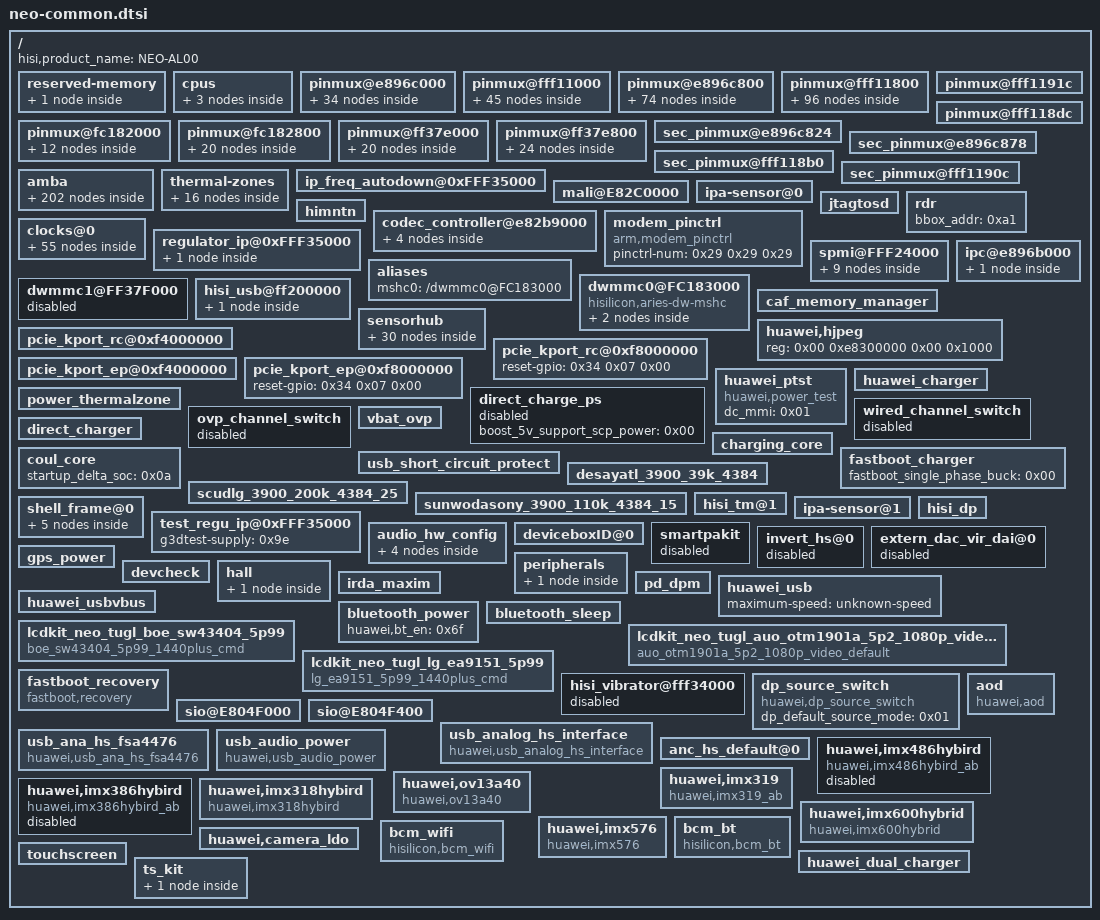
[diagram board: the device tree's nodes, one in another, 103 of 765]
/include/ "../kirin970-common.dtsi"

/ {
	hisi,product_name = "NEO-AL00";

	reserved-memory {
		bbox-mem {
			phandle = <0xa1>;
		};
	};

	cpus {
		cpu-map {
			cluster0 {
				phandle = <0x98>;
			};

			cluster1 {
				phandle = <0x99>;
			};
		};
	};

	pinmux@e896c000 {
		phandle = <0x52>;

		gpio006_pmx_idle {
			pinctrl-single,pins = <0x10 0x00>;
		};

		gpio007_pmx_idle {
			pinctrl-single,pins = <0x14 0x00>;
		};

		gpio016_pmx_func {
			pinctrl-single,pins = <0x720 0x02>;
		};

		gpio016_pmx_idle {
			pinctrl-single,pins = <0x720 0x02>;
		};

		gpio024_pmx_func {
			pinctrl-single,pins = <0x34 0x01>;
		};

		gpio024_pmx_idle {
			pinctrl-single,pins = <0x34 0x01>;
		};

		gpio025_pmx_func {
			pinctrl-single,pins = <0x38 0x01>;
		};

		gpio025_pmx_idle {
			pinctrl-single,pins = <0x38 0x01>;
		};

		gpio037_pmx_func {
			pinctrl-single,pins = <0x5c 0x01>;
		};

		gpio037_pmx_idle {
			pinctrl-single,pins = <0x5c 0x01>;
		};

		gpio038_pmx_func {
			pinctrl-single,pins = <0x60 0x01>;
		};

		gpio038_pmx_idle {
			pinctrl-single,pins = <0x60 0x01>;
		};

		gpio039_pmx_func {
			pinctrl-single,pins = <0x64 0x02>;
		};

		gpio039_pmx_idle {
			pinctrl-single,pins = <0x64 0x02>;
		};

		gpio040_pmx_func {
			pinctrl-single,pins = <0x68 0x02>;
		};

		gpio040_pmx_idle {
			pinctrl-single,pins = <0x68 0x02>;
		};

		gpio041_pmx_func {
			pinctrl-single,pins = <0x6c 0x02>;
		};

		gpio041_pmx_idle {
			pinctrl-single,pins = <0x6c 0x02>;
		};

		gpio042_pmx_func {
			pinctrl-single,pins = <0x70 0x02>;
		};

		gpio042_pmx_idle {
			pinctrl-single,pins = <0x70 0x02>;
		};

		gpio043_pmx_func {
			pinctrl-single,pins = <0x74 0x01>;
		};

		gpio043_pmx_idle {
			pinctrl-single,pins = <0x74 0x01>;
		};

		gpio044_pmx_func {
			pinctrl-single,pins = <0x78 0x01>;
		};

		gpio044_pmx_idle {
			pinctrl-single,pins = <0x78 0x01>;
		};

		gpio050_pmx_func {
			pinctrl-single,pins = <0x8c 0x00>;
		};

		gpio050_pmx_idle {
			pinctrl-single,pins = <0x8c 0x00>;
		};

		gpio055_pmx_func {
			pinctrl-single,pins = <0xa0 0x00>;
		};

		gpio055_pmx_idle {
			pinctrl-single,pins = <0xa0 0x00>;
		};

		gpio059_pmx_func {
			pinctrl-single,pins = <0xb0 0x00>;
		};

		gpio059_pmx_idle {
			pinctrl-single,pins = <0xb0 0x00>;
		};

		gpio060_pmx_func {
			pinctrl-single,pins = <0xb4 0x00>;
		};

		gpio060_pmx_idle {
			pinctrl-single,pins = <0xb4 0x00>;
		};

		gpio061_pmx_func {
			pinctrl-single,pins = <0xb8 0x00>;
		};

		gpio061_pmx_idle {
			pinctrl-single,pins = <0xb8 0x00>;
		};
	};

	pinmux@fff11000 {
		phandle = <0x66>;

		gpio144_pmx_func {
			pinctrl-single,pins = <0x72c 0x00>;
			phandle = <0x45>;
		};

		gpio144_pmx_idle {
			pinctrl-single,pins = <0x72c 0x00>;
			phandle = <0x4b>;
		};

		gpio145_pmx_func {
			pinctrl-single,pins = <0x730 0x00>;
			phandle = <0x46>;
		};

		gpio145_pmx_idle {
			pinctrl-single,pins = <0x730 0x00>;
			phandle = <0x4c>;
		};

		gpio146_pmx_func {
			pinctrl-single,pins = <0x734 0x00>;
			phandle = <0x47>;
		};

		gpio146_pmx_idle {
			pinctrl-single,pins = <0x734 0x00>;
			phandle = <0x4d>;
		};

		gpio182_pmx_func {
		};

		gpio182_pmx_idle {
		};

		gpio183_pmx_func {
			pinctrl-single,pins = <0x14 0x02>;
		};

		gpio183_pmx_idle {
			pinctrl-single,pins = <0x14 0x02>;
		};

		gpio184_pmx_func {
			pinctrl-single,pins = <0x18 0x00>;
		};

		gpio185_pmx_func {
			pinctrl-single,pins = <0x1c 0x00>;
		};

		gpio185_pmx_idle {
			pinctrl-single,pins = <0x1c 0x00>;
		};

		gpio188_pmx_idle {
			pinctrl-single,pins = <0x28 0x00>;
		};

		gpio189_pmx_idle {
			pinctrl-single,pins = <0x2c 0x00>;
		};

		gpio190_pmx_func {
			pinctrl-single,pins = <0x30 0x03>;
		};

		gpio190_pmx_idle {
			pinctrl-single,pins = <0x30 0x03>;
		};

		gpio191_pmx_func {
			pinctrl-single,pins = <0x34 0x03>;
		};

		gpio191_pmx_idle {
			pinctrl-single,pins = <0x34 0x03>;
		};

		gpio194_pmx_func {
			pinctrl-single,pins = <0x40 0x00>;
		};

		gpio194_pmx_idle {
			pinctrl-single,pins = <0x40 0x00>;
		};

		gpio195_pmx_func {
			pinctrl-single,pins = <0x44 0x02>;
		};

		gpio195_pmx_idle {
			pinctrl-single,pins = <0x44 0x02>;
		};

		gpio198_pmx_idle {
			pinctrl-single,pins = <0x50 0x00>;
		};

		gpio199_pmx_idle {
			pinctrl-single,pins = <0x54 0x00>;
		};

		gpio200_pmx_func {
			pinctrl-single,pins = <0x58 0x00>;
		};

		gpio200_pmx_idle {
			pinctrl-single,pins = <0x58 0x00>;
		};

		gpio206_pmx_func {
			pinctrl-single,pins = <0x70 0x00>;
		};

		gpio206_pmx_idle {
			pinctrl-single,pins = <0x70 0x00>;
		};

		gpio208_pmx_func {
			pinctrl-single,pins = <0x78 0x02>;
		};

		gpio208_pmx_idle {
			pinctrl-single,pins = <0x78 0x02>;
		};

		gpio216_pmx_func {
			pinctrl-single,pins = <0x71c 0x01>;
		};

		gpio216_pmx_idle {
			pinctrl-single,pins = <0x71c 0x01>;
		};

		gpio217_pmx_func {
			pinctrl-single,pins = <0x720 0x00>;
		};

		gpio217_pmx_idle {
			pinctrl-single,pins = <0x720 0x00>;
		};

		gpio218_pmx_func {
			pinctrl-single,pins = <0x724 0x02>;
		};

		gpio218_pmx_idle {
			pinctrl-single,pins = <0x724 0x02>;
		};

		gpio220_pmx_func {
			pinctrl-single,pins = <0x7c 0x02>;
		};

		gpio220_pmx_idle {
			pinctrl-single,pins = <0x7c 0x02>;
		};

		gpio221_pmx_func {
			pinctrl-single,pins = <0x80 0x02>;
		};

		gpio221_pmx_idle {
			pinctrl-single,pins = <0x80 0x02>;
		};

		gpio222_pmx_func {
			pinctrl-single,pins = <0x84 0x01>;
		};

		gpio222_pmx_idle {
			pinctrl-single,pins = <0x84 0x01>;
		};

		gpio223_pmx_func {
			pinctrl-single,pins = <0x88 0x01>;
		};

		gpio223_pmx_idle {
			pinctrl-single,pins = <0x88 0x01>;
		};
	};

	pinmux@e896c800 {
		gpio003_cfg_func {
			pinctrl-single,bias-pulldown = <0x00 0x02 0x00 0x02>;
		};

		gpio003_cfg_idle {
			pinctrl-single,bias-pulldown = <0x00 0x02 0x00 0x02>;
		};

		gpio004_cfg_func {
			pinctrl-single,bias-pulldown = <0x00 0x02 0x00 0x02>;
			pinctrl-single,bias-pullup = <0x00 0x01 0x00 0x01>;
		};

		gpio004_cfg_idle {
			pinctrl-single,bias-pulldown = <0x00 0x02 0x00 0x02>;
			pinctrl-single,bias-pullup = <0x00 0x01 0x00 0x01>;
		};

		gpio005_cfg_func {
			pinctrl-single,drive-strength = <0x20 0x70>;
		};

		gpio005_cfg_idle {
			pinctrl-single,drive-strength = <0x20 0x70>;
		};

		gpio006_cfg_func {
			pinctrl-single,drive-strength = <0x20 0x70>;
		};

		gpio007_cfg_func {
			pinctrl-single,drive-strength = <0x20 0x70>;
		};

		gpio008_cfg_func {
			pinctrl-single,bias-pulldown = <0x00 0x02 0x00 0x02>;
			pinctrl-single,bias-pullup = <0x00 0x01 0x00 0x01>;
		};

		gpio008_cfg_idle {
			pinctrl-single,bias-pulldown = <0x00 0x02 0x00 0x02>;
			pinctrl-single,bias-pullup = <0x00 0x01 0x00 0x01>;
		};

		gpio009_cfg_func {
			pinctrl-single,bias-pullup = <0x00 0x01 0x00 0x01>;
		};

		gpio009_cfg_idle {
			pinctrl-single,bias-pulldown = <0x00 0x02 0x00 0x02>;
			pinctrl-single,bias-pullup = <0x00 0x01 0x00 0x01>;
		};

		gpio010_cfg_func {
			pinctrl-single,bias-pulldown = <0x00 0x02 0x00 0x02>;
			pinctrl-single,bias-pullup = <0x00 0x01 0x00 0x01>;
		};

		gpio010_cfg_idle {
			pinctrl-single,bias-pulldown = <0x00 0x02 0x00 0x02>;
			pinctrl-single,bias-pullup = <0x00 0x01 0x00 0x01>;
		};

		gpio011_cfg_func {
			pinctrl-single,bias-pulldown = <0x00 0x02 0x00 0x02>;
			pinctrl-single,bias-pullup = <0x00 0x01 0x00 0x01>;
		};

		gpio011_cfg_idle {
			pinctrl-single,bias-pulldown = <0x00 0x02 0x00 0x02>;
			pinctrl-single,bias-pullup = <0x00 0x01 0x00 0x01>;
		};

		gpio012_cfg_func {
			pinctrl-single,bias-pulldown = <0x00 0x02 0x00 0x02>;
		};

		gpio012_cfg_idle {
			pinctrl-single,bias-pulldown = <0x00 0x02 0x00 0x02>;
		};

		gpio014_cfg_func {
			pinctrl-single,bias-pulldown = <0x00 0x02 0x00 0x02>;
		};

		gpio014_cfg_idle {
			pinctrl-single,bias-pulldown = <0x00 0x02 0x00 0x02>;
		};

		gpio015_cfg_func {
			pinctrl-single,bias-pulldown = <0x00 0x02 0x00 0x02>;
		};

		gpio015_cfg_idle {
			pinctrl-single,bias-pulldown = <0x00 0x02 0x00 0x02>;
		};

		gpio026_cfg_func {
			pinctrl-single,drive-strength = <0x20 0x70>;
		};

		gpio026_cfg_idle {
			pinctrl-single,drive-strength = <0x20 0x70>;
		};

		gpio027_cfg_func {
			pinctrl-single,drive-strength = <0x20 0x70>;
		};

		gpio027_cfg_idle {
			pinctrl-single,drive-strength = <0x20 0x70>;
		};

		gpio030_cfg_func {
			pinctrl-single,bias-pulldown = <0x00 0x02 0x00 0x02>;
		};

		gpio030_cfg_idle {
			pinctrl-single,bias-pulldown = <0x00 0x02 0x00 0x02>;
		};

		gpio034_cfg_func {
			pinctrl-single,bias-pulldown = <0x00 0x02 0x00 0x02>;
		};

		gpio034_cfg_idle {
			pinctrl-single,bias-pulldown = <0x00 0x02 0x00 0x02>;
		};

		gpio035_cfg_func {
			pinctrl-single,bias-pulldown = <0x00 0x02 0x00 0x02>;
			pinctrl-single,bias-pullup = <0x00 0x01 0x00 0x01>;
		};

		gpio035_cfg_idle {
			pinctrl-single,bias-pulldown = <0x00 0x02 0x00 0x02>;
			pinctrl-single,bias-pullup = <0x01 0x01 0x00 0x01>;
		};

		gpio036_cfg_func {
			pinctrl-single,bias-pulldown = <0x00 0x02 0x00 0x02>;
			pinctrl-single,bias-pullup = <0x00 0x01 0x00 0x01>;
		};

		gpio036_cfg_idle {
			pinctrl-single,bias-pulldown = <0x00 0x02 0x00 0x02>;
			pinctrl-single,bias-pullup = <0x00 0x01 0x00 0x01>;
			pinctrl-single,drive-strength = <0x10 0x70>;
		};

		gpio037_cfg_func {
			pinctrl-single,bias-pulldown = <0x00 0x02 0x00 0x02>;
			pinctrl-single,bias-pullup = <0x01 0x01 0x00 0x01>;
			pinctrl-single,drive-strength = <0x10 0x70>;
		};

		gpio037_cfg_idle {
			pinctrl-single,bias-pulldown = <0x00 0x02 0x00 0x02>;
			pinctrl-single,bias-pullup = <0x01 0x01 0x00 0x01>;
			pinctrl-single,drive-strength = <0x10 0x70>;
		};

		gpio038_cfg_func {
			pinctrl-single,bias-pulldown = <0x00 0x02 0x00 0x02>;
			pinctrl-single,drive-strength = <0x10 0x70>;
		};

		gpio038_cfg_idle {
			pinctrl-single,bias-pulldown = <0x00 0x02 0x00 0x02>;
			pinctrl-single,drive-strength = <0x10 0x70>;
		};

		gpio039_cfg_func {
			pinctrl-single,bias-pulldown = <0x02 0x02 0x00 0x02>;
		};

		gpio039_cfg_idle {
			pinctrl-single,bias-pulldown = <0x02 0x02 0x00 0x02>;
		};

		gpio040_cfg_func {
			pinctrl-single,bias-pulldown = <0x02 0x02 0x00 0x02>;
		};

		gpio040_cfg_idle {
			pinctrl-single,bias-pulldown = <0x02 0x02 0x00 0x02>;
		};

		gpio041_cfg_func {
			pinctrl-single,bias-pulldown = <0x00 0x02 0x00 0x02>;
			pinctrl-single,bias-pullup = <0x01 0x01 0x00 0x01>;
		};

		gpio041_cfg_idle {
			pinctrl-single,bias-pulldown = <0x00 0x02 0x00 0x02>;
			pinctrl-single,bias-pullup = <0x01 0x01 0x00 0x01>;
		};

		gpio042_cfg_func {
			pinctrl-single,bias-pulldown = <0x00 0x02 0x00 0x02>;
			pinctrl-single,bias-pullup = <0x01 0x01 0x00 0x01>;
		};

		gpio042_cfg_idle {
			pinctrl-single,bias-pulldown = <0x00 0x02 0x00 0x02>;
			pinctrl-single,bias-pullup = <0x01 0x01 0x00 0x01>;
		};

		gpio043_cfg_func {
			pinctrl-single,bias-pullup = <0x00 0x01 0x00 0x01>;
		};

		gpio043_cfg_idle {
			pinctrl-single,bias-pullup = <0x00 0x01 0x00 0x01>;
		};

		gpio044_cfg_func {
			pinctrl-single,bias-pullup = <0x00 0x01 0x00 0x01>;
		};

		gpio044_cfg_idle {
			pinctrl-single,bias-pullup = <0x00 0x01 0x00 0x01>;
		};

		gpio045_cfg_func {
			pinctrl-single,bias-pullup = <0x01 0x01 0x00 0x01>;
		};

		gpio045_cfg_idle {
			pinctrl-single,bias-pullup = <0x01 0x01 0x00 0x01>;
		};

		gpio046_cfg_func {
			pinctrl-single,bias-pullup = <0x00 0x01 0x00 0x01>;
		};

		gpio046_cfg_idle {
			pinctrl-single,bias-pullup = <0x00 0x01 0x00 0x01>;
		};

		gpio047_cfg_func {
			pinctrl-single,bias-pulldown = <0x00 0x02 0x00 0x02>;
			pinctrl-single,bias-pullup = <0x00 0x01 0x00 0x01>;
		};

		gpio047_cfg_idle {
			pinctrl-single,bias-pulldown = <0x00 0x02 0x00 0x02>;
			pinctrl-single,bias-pullup = <0x00 0x01 0x00 0x01>;
		};

		gpio049_cfg_idle {
			pinctrl-single,bias-pulldown = <0x00 0x02 0x00 0x02>;
		};

		gpio050_cfg_idle {
			pinctrl-single,bias-pulldown = <0x00 0x02 0x00 0x02>;
		};

		gpio051_cfg_func {
			pinctrl-single,bias-pulldown = <0x00 0x02 0x00 0x02>;
			pinctrl-single,bias-pullup = <0x00 0x01 0x00 0x01>;
		};

		gpio051_cfg_idle {
			pinctrl-single,bias-pulldown = <0x02 0x02 0x00 0x02>;
			pinctrl-single,bias-pullup = <0x00 0x01 0x00 0x01>;
		};

		gpio054_cfg_func {
			pinctrl-single,bias-pulldown = <0x00 0x02 0x00 0x02>;
		};

		gpio054_cfg_idle {
			pinctrl-single,bias-pulldown = <0x00 0x02 0x00 0x02>;
		};

		gpio055_cfg_func {
			pinctrl-single,pins = <0xa4 0x00>;
			pinctrl-single,bias-pulldown = <0x00 0x02 0x00 0x02>;
			pinctrl-single,bias-pullup = <0x01 0x01 0x00 0x01>;
			pinctrl-single,drive-strength = <0x40 0x70>;
			pinctrl-single,slew-rate = <0x00 0x80>;
		};

		gpio055_cfg_idle {
			pinctrl-single,pins = <0xa4 0x00>;
			pinctrl-single,bias-pulldown = <0x00 0x02 0x00 0x02>;
			pinctrl-single,bias-pullup = <0x01 0x01 0x00 0x01>;
			pinctrl-single,drive-strength = <0x40 0x70>;
			pinctrl-single,slew-rate = <0x00 0x80>;
		};

		gpio056_cfg_func {
			pinctrl-single,bias-pulldown = <0x00 0x02 0x00 0x02>;
			pinctrl-single,bias-pullup = <0x00 0x01 0x00 0x01>;
		};

		gpio056_cfg_idle {
			pinctrl-single,bias-pulldown = <0x00 0x02 0x00 0x02>;
			pinctrl-single,bias-pullup = <0x00 0x01 0x00 0x01>;
		};

		gpio057_cfg_func {
			pinctrl-single,bias-pulldown = <0x00 0x02 0x00 0x02>;
		};

		gpio057_cfg_idle {
			pinctrl-single,bias-pulldown = <0x00 0x02 0x00 0x02>;
		};

		gpio059_cfg_func {
			pinctrl-single,pins = <0xb4 0x00>;
			pinctrl-single,bias-pulldown = <0x00 0x02 0x00 0x02>;
			pinctrl-single,bias-pullup = <0x00 0x01 0x00 0x01>;
			pinctrl-single,drive-strength = <0x00 0x70>;
			pinctrl-single,slew-rate = <0x00 0x80>;
		};

		gpio059_cfg_idle {
			pinctrl-single,pins = <0xb4 0x00>;
			pinctrl-single,bias-pulldown = <0x00 0x02 0x00 0x02>;
			pinctrl-single,bias-pullup = <0x00 0x01 0x00 0x01>;
			pinctrl-single,drive-strength = <0x00 0x70>;
			pinctrl-single,slew-rate = <0x00 0x80>;
		};

		gpio060_cfg_func {
			pinctrl-single,pins = <0xb8 0x00>;
			pinctrl-single,bias-pulldown = <0x00 0x02 0x00 0x02>;
			pinctrl-single,bias-pullup = <0x00 0x01 0x00 0x01>;
			pinctrl-single,drive-strength = <0x00 0x70>;
			pinctrl-single,slew-rate = <0x00 0x80>;
		};

		gpio060_cfg_idle {
			pinctrl-single,pins = <0xb8 0x00>;
			pinctrl-single,bias-pulldown = <0x00 0x02 0x00 0x02>;
			pinctrl-single,bias-pullup = <0x00 0x01 0x00 0x01>;
			pinctrl-single,drive-strength = <0x00 0x70>;
			pinctrl-single,slew-rate = <0x00 0x80>;
		};

		gpio061_cfg_func {
			pinctrl-single,pins = <0xbc 0x00>;
			pinctrl-single,bias-pulldown = <0x00 0x02 0x00 0x02>;
			pinctrl-single,bias-pullup = <0x00 0x01 0x00 0x01>;
			pinctrl-single,drive-strength = <0x00 0x70>;
			pinctrl-single,slew-rate = <0x00 0x80>;
		};

		gpio061_cfg_idle {
			pinctrl-single,pins = <0xbc 0x00>;
			pinctrl-single,bias-pullup = <0x00 0x01 0x00 0x01>;
			pinctrl-single,drive-strength = <0x00 0x70>;
			pinctrl-single,slew-rate = <0x00 0x80>;
		};
	};

	pinmux@fff11800 {
		gpio144_cfg_func {
			pinctrl-single,bias-pulldown = <0x00 0x02 0x00 0x02>;
			pinctrl-single,bias-pullup = <0x00 0x01 0x00 0x01>;
			pinctrl-single,drive-strength = <0x00 0x70>;
			phandle = <0x48>;
		};

		gpio144_cfg_idle {
			pinctrl-single,bias-pulldown = <0x00 0x02 0x00 0x02>;
			pinctrl-single,bias-pullup = <0x00 0x01 0x00 0x01>;
			pinctrl-single,drive-strength = <0x00 0x70>;
			phandle = <0x4e>;
		};

		gpio145_cfg_func {
			pinctrl-single,bias-pulldown = <0x00 0x02 0x00 0x02>;
			pinctrl-single,bias-pullup = <0x00 0x01 0x00 0x01>;
			pinctrl-single,drive-strength = <0x00 0x70>;
			phandle = <0x49>;
		};

		gpio145_cfg_idle {
			pinctrl-single,bias-pulldown = <0x00 0x02 0x00 0x02>;
			pinctrl-single,bias-pullup = <0x00 0x01 0x00 0x01>;
			pinctrl-single,drive-strength = <0x00 0x70>;
			phandle = <0x4f>;
		};

		gpio146_cfg_func {
			pinctrl-single,bias-pulldown = <0x00 0x02 0x00 0x02>;
			pinctrl-single,drive-strength = <0x00 0x70>;
			phandle = <0x4a>;
		};

		gpio146_cfg_idle {
			pinctrl-single,bias-pulldown = <0x00 0x02 0x00 0x02>;
			pinctrl-single,drive-strength = <0x00 0x70>;
			phandle = <0x50>;
		};

		gpio147_cfg_func {
			pinctrl-single,bias-pulldown = <0x00 0x02 0x00 0x02>;
			pinctrl-single,drive-strength = <0x00 0x70>;
		};

		gpio147_cfg_idle {
			pinctrl-single,bias-pulldown = <0x00 0x02 0x00 0x02>;
			pinctrl-single,drive-strength = <0x00 0x70>;
		};

		gpio177_cfg_func {
			pinctrl-single,bias-pulldown = <0x02 0x02 0x00 0x02>;
			pinctrl-single,bias-pullup = <0x00 0x01 0x00 0x01>;
		};

		gpio177_cfg_idle {
			pinctrl-single,bias-pulldown = <0x02 0x02 0x00 0x02>;
			pinctrl-single,bias-pullup = <0x00 0x01 0x00 0x01>;
		};

		gpio182_cfg_func {
		};

		gpio182_cfg_idle {
		};

		gpio183_cfg_func {
			pinctrl-single,bias-pulldown = <0x00 0x02 0x00 0x02>;
			pinctrl-single,bias-pullup = <0x00 0x01 0x00 0x01>;
		};

		gpio183_cfg_idle {
			pinctrl-single,pins = <0x40 0x00>;
			pinctrl-single,bias-pulldown = <0x00 0x02 0x00 0x02>;
			pinctrl-single,bias-pullup = <0x00 0x01 0x00 0x01>;
		};

		gpio184_cfg_func {
			pinctrl-single,bias-pulldown = <0x00 0x02 0x00 0x02>;
			pinctrl-single,bias-pullup = <0x01 0x01 0x00 0x01>;
		};

		gpio184_cfg_idle {
			pinctrl-single,bias-pulldown = <0x00 0x02 0x00 0x02>;
			pinctrl-single,bias-pullup = <0x01 0x01 0x00 0x01>;
		};

		gpio185_cfg_func {
			pinctrl-single,bias-pulldown = <0x00 0x02 0x00 0x02>;
		};

		gpio185_cfg_idle {
			pinctrl-single,bias-pulldown = <0x00 0x02 0x00 0x02>;
		};

		gpio188_cfg_func {
			pinctrl-single,drive-strength = <0x20 0x70>;
		};

		gpio188_cfg_idle {
			pinctrl-single,drive-strength = <0x20 0x70>;
		};

		gpio189_cfg_func {
			pinctrl-single,drive-strength = <0x20 0x70>;
		};

		gpio189_cfg_idle {
			pinctrl-single,drive-strength = <0x20 0x70>;
		};

		gpio190_cfg_func {
			pinctrl-single,bias-pulldown = <0x00 0x02 0x00 0x02>;
			pinctrl-single,drive-strength = <0x30 0x70>;
		};

		gpio190_cfg_idle {
			pinctrl-single,bias-pulldown = <0x00 0x02 0x00 0x02>;
			pinctrl-single,drive-strength = <0x30 0x70>;
		};

		gpio191_cfg_func {
			pinctrl-single,bias-pulldown = <0x00 0x02 0x00 0x02>;
			pinctrl-single,drive-strength = <0x30 0x70>;
		};

		gpio191_cfg_idle {
			pinctrl-single,bias-pulldown = <0x00 0x02 0x00 0x02>;
			pinctrl-single,drive-strength = <0x30 0x70>;
		};

		gpio192_cfg_func {
			pinctrl-single,drive-strength = <0x20 0x70>;
		};

		gpio192_cfg_idle {
			pinctrl-single,drive-strength = <0x20 0x70>;
		};

		gpio193_cfg_func {
			pinctrl-single,drive-strength = <0x20 0x70>;
		};

		gpio193_cfg_idle {
			pinctrl-single,drive-strength = <0x20 0x70>;
		};

		gpio194_cfg_func {
			pinctrl-single,bias-pulldown = <0x00 0x02 0x00 0x02>;
		};

		gpio194_cfg_idle {
			pinctrl-single,bias-pulldown = <0x00 0x02 0x00 0x02>;
		};

		gpio195_cfg_func {
			pinctrl-single,bias-pulldown = <0x00 0x02 0x00 0x02>;
		};

		gpio195_cfg_idle {
			pinctrl-single,bias-pulldown = <0x00 0x02 0x00 0x02>;
		};

		gpio198_cfg_func {
			pinctrl-single,drive-strength = <0x20 0x70>;
		};

		gpio198_cfg_idle {
			pinctrl-single,drive-strength = <0x20 0x70>;
		};

		gpio199_cfg_func {
			pinctrl-single,drive-strength = <0x20 0x70>;
		};

		gpio199_cfg_idle {
			pinctrl-single,drive-strength = <0x20 0x70>;
		};

		gpio200_cfg_func {
			pinctrl-single,pins = <0x84 0x00>;
			pinctrl-single,bias-pulldown = <0x00 0x02 0x00 0x02>;
			pinctrl-single,bias-pullup = <0x01 0x01 0x00 0x01>;
			pinctrl-single,drive-strength = <0x10 0x70>;
			pinctrl-single,slew-rate = <0x00 0x80>;
		};

		gpio200_cfg_idle {
			pinctrl-single,pins = <0x84 0x00>;
			pinctrl-single,bias-pulldown = <0x00 0x02 0x00 0x02>;
			pinctrl-single,bias-pullup = <0x01 0x01 0x00 0x01>;
			pinctrl-single,drive-strength = <0x10 0x70>;
			pinctrl-single,slew-rate = <0x00 0x80>;
		};

		gpio201_cfg_func {
			pinctrl-single,bias-pulldown = <0x02 0x02 0x00 0x02>;
			pinctrl-single,bias-pullup = <0x00 0x01 0x00 0x01>;
			pinctrl-single,drive-strength = <0x10 0x70>;
			phandle = <0x3cb>;
		};

		gpio201_cfg_idle {
			pinctrl-single,bias-pulldown = <0x02 0x02 0x00 0x02>;
			pinctrl-single,bias-pullup = <0x00 0x01 0x00 0x01>;
			pinctrl-single,drive-strength = <0x10 0x70>;
			phandle = <0x3cc>;
		};

		gpio202_cfg_func {
			pinctrl-single,bias-pullup = <0x00 0x01 0x00 0x01>;
			phandle = <0x3cd>;
		};

		gpio202_cfg_idle {
			pinctrl-single,bias-pullup = <0x00 0x01 0x00 0x01>;
			phandle = <0x3ce>;
		};

		gpio203_cfg_func {
			pinctrl-single,drive-strength = <0x20 0x70>;
		};

		gpio203_cfg_idle {
			pinctrl-single,bias-pulldown = <0x00 0x02 0x00 0x02>;
			pinctrl-single,drive-strength = <0x20 0x70>;
		};

		gpio204_cfg_func {
			phandle = <0x3cf>;
		};

		gpio204_cfg_idle {
			phandle = <0x3d0>;
		};

		gpio205_cfg_func {
			pinctrl-single,bias-pullup = <0x00 0x01 0x00 0x01>;
			phandle = <0x3d1>;
		};

		gpio205_cfg_idle {
			pinctrl-single,bias-pullup = <0x00 0x01 0x00 0x01>;
			phandle = <0x3d2>;
		};

		gpio206_cfg_func {
			pinctrl-single,pins = <0x9c 0x00>;
			pinctrl-single,bias-pulldown = <0x00 0x02 0x00 0x02>;
			pinctrl-single,bias-pullup = <0x00 0x01 0x00 0x01>;
			pinctrl-single,drive-strength = <0x00 0x70>;
			pinctrl-single,slew-rate = <0x00 0x80>;
			phandle = <0x3d3>;
		};

		gpio206_cfg_idle {
			pinctrl-single,pins = <0x9c 0x00>;
			pinctrl-single,bias-pulldown = <0x00 0x02 0x00 0x02>;
			pinctrl-single,bias-pullup = <0x00 0x01 0x00 0x01>;
			pinctrl-single,drive-strength = <0x00 0x70>;
			pinctrl-single,slew-rate = <0x00 0x80>;
			phandle = <0x3d4>;
		};

		gpio207_cfg_func {
			phandle = <0x3d5>;
		};

		gpio207_cfg_idle {
			phandle = <0x3d6>;
		};

		gpio208_cfg_func {
			pinctrl-single,bias-pulldown = <0x00 0x02 0x00 0x02>;
			pinctrl-single,bias-pullup = <0x00 0x01 0x00 0x01>;
		};

		gpio208_cfg_idle {
			pinctrl-single,bias-pulldown = <0x00 0x02 0x00 0x02>;
			pinctrl-single,bias-pullup = <0x00 0x01 0x00 0x01>;
		};

		gpio209_cfg_func {
			pinctrl-single,bias-pulldown = <0x02 0x02 0x00 0x02>;
			phandle = <0x3d7>;
		};

		gpio209_cfg_idle {
			pinctrl-single,bias-pulldown = <0x02 0x02 0x00 0x02>;
			phandle = <0x3d8>;
		};

		gpio210_cfg_func {
			phandle = <0x3d9>;
		};

		gpio210_cfg_idle {
			phandle = <0x3da>;
		};

		gpio211_cfg_func {
			phandle = <0x3db>;
		};

		gpio211_cfg_idle {
			phandle = <0x3dc>;
		};

		gpio212_cfg_func {
			pinctrl-single,bias-pullup = <0x00 0x01 0x00 0x01>;
			phandle = <0x3dd>;
		};

		gpio212_cfg_idle {
			pinctrl-single,bias-pulldown = <0x00 0x02 0x00 0x02>;
			pinctrl-single,bias-pullup = <0x00 0x01 0x00 0x01>;
			phandle = <0x3de>;
		};

		gpio216_cfg_func {
			pinctrl-single,pins = <0x71c 0x00>;
			pinctrl-single,bias-pulldown = <0x00 0x02 0x00 0x02>;
			pinctrl-single,bias-pullup = <0x00 0x01 0x00 0x01>;
			pinctrl-single,drive-strength = <0x20 0x70>;
			pinctrl-single,slew-rate = <0x00 0x80>;
			phandle = <0x3df>;
		};

		gpio216_cfg_idle {
			pinctrl-single,pins = <0x71c 0x00>;
			pinctrl-single,bias-pulldown = <0x00 0x02 0x00 0x02>;
			pinctrl-single,bias-pullup = <0x00 0x01 0x00 0x01>;
			pinctrl-single,drive-strength = <0x20 0x70>;
			pinctrl-single,slew-rate = <0x00 0x80>;
			phandle = <0x3e0>;
		};

		gpio217_cfg_func {
			pinctrl-single,bias-pulldown = <0x00 0x02 0x00 0x02>;
			phandle = <0x3e1>;
		};

		gpio217_cfg_idle {
			pinctrl-single,bias-pulldown = <0x00 0x02 0x00 0x02>;
			phandle = <0x3e2>;
		};

		gpio218_cfg_func {
			phandle = <0x3e3>;
		};

		gpio218_cfg_idle {
			phandle = <0x3e4>;
		};

		gpio219_cfg_func {
			pinctrl-single,bias-pulldown = <0x00 0x02 0x00 0x02>;
			pinctrl-single,bias-pullup = <0x01 0x01 0x00 0x01>;
			phandle = <0x3e5>;
		};

		gpio219_cfg_idle {
			pinctrl-single,bias-pulldown = <0x00 0x02 0x00 0x02>;
			pinctrl-single,bias-pullup = <0x01 0x01 0x00 0x01>;
			phandle = <0x3e6>;
		};

		gpio220_cfg_func {
			pinctrl-single,bias-pulldown = <0x00 0x02 0x00 0x02>;
			pinctrl-single,bias-pullup = <0x00 0x01 0x00 0x01>;
			phandle = <0x3e7>;
		};

		gpio220_cfg_idle {
			pinctrl-single,bias-pulldown = <0x00 0x02 0x00 0x02>;
			pinctrl-single,bias-pullup = <0x00 0x01 0x00 0x01>;
			phandle = <0x3e8>;
		};

		gpio221_cfg_func {
			pinctrl-single,pins = <0xac 0x00>;
			pinctrl-single,bias-pulldown = <0x00 0x02 0x00 0x02>;
			pinctrl-single,bias-pullup = <0x01 0x01 0x00 0x01>;
			pinctrl-single,drive-strength = <0x00 0x70>;
			pinctrl-single,slew-rate = <0x00 0x80>;
			phandle = <0x3e9>;
		};

		gpio221_cfg_idle {
			pinctrl-single,pins = <0xac 0x00>;
			pinctrl-single,bias-pulldown = <0x00 0x02 0x00 0x02>;
			pinctrl-single,bias-pullup = <0x01 0x01 0x00 0x01>;
			pinctrl-single,drive-strength = <0x00 0x70>;
			pinctrl-single,slew-rate = <0x00 0x80>;
			phandle = <0x3ea>;
		};

		gpio222_cfg_func {
			pinctrl-single,bias-pulldown = <0x00 0x02 0x00 0x02>;
			phandle = <0x3eb>;
		};

		gpio222_cfg_idle {
			pinctrl-single,bias-pulldown = <0x00 0x02 0x00 0x02>;
			phandle = <0x3ec>;
		};

		gpio223_cfg_func {
			pinctrl-single,bias-pulldown = <0x00 0x02 0x00 0x02>;
			phandle = <0x3ed>;
		};

		gpio223_cfg_idle {
			pinctrl-single,bias-pulldown = <0x00 0x02 0x00 0x02>;
			phandle = <0x3ee>;
		};

		gpio224_cfg_func {
			phandle = <0x3ef>;
		};

		gpio224_cfg_idle {
			phandle = <0x3f0>;
		};

		gpio225_cfg_func {
			phandle = <0x3f1>;
		};

		gpio225_cfg_idle {
			pinctrl-single,slew-rate = <0x80 0x80>;
			phandle = <0x3f2>;
		};

		gpio226_cfg_func {
			phandle = <0x3f3>;
		};

		gpio226_cfg_idle {
			pinctrl-single,slew-rate = <0x80 0x80>;
			phandle = <0x3f4>;
		};

		gpio227_cfg_func {
			pinctrl-single,bias-pulldown = <0x00 0x02 0x00 0x02>;
			pinctrl-single,bias-pullup = <0x01 0x01 0x00 0x01>;
			phandle = <0x3f5>;
		};

		gpio227_cfg_idle {
			pinctrl-single,bias-pulldown = <0x00 0x02 0x00 0x02>;
			pinctrl-single,bias-pullup = <0x01 0x01 0x00 0x01>;
			phandle = <0x3f6>;
		};

		gpio228_cfg_func {
			pinctrl-single,bias-pulldown = <0x00 0x02 0x00 0x02>;
			phandle = <0x3f7>;
		};

		gpio228_cfg_idle {
			pinctrl-single,bias-pulldown = <0x00 0x02 0x00 0x02>;
			phandle = <0x3f8>;
		};

		gpio229_cfg_func {
			phandle = <0x3f9>;
		};

		gpio229_cfg_idle {
			phandle = <0x3fa>;
		};

		gpio230_cfg_func {
			phandle = <0x3fb>;
		};

		gpio230_cfg_idle {
			phandle = <0x3fc>;
		};

		gpio231_cfg_func {
			phandle = <0x3fd>;
		};

		gpio231_cfg_idle {
			phandle = <0x3fe>;
		};
	};

	pinmux@fc182000 {
		phandle = <0x63>;

		gpio128_pmx_func {
			pinctrl-single,pins = <0x00 0x00>;
		};

		gpio128_pmx_idle {
			pinctrl-single,pins = <0x00 0x00>;
		};

		gpio129_pmx_func {
			pinctrl-single,pins = <0x04 0x00>;
		};

		gpio129_pmx_idle {
			pinctrl-single,pins = <0x04 0x00>;
		};

		gpio130_pmx_func {
			pinctrl-single,pins = <0x08 0x00>;
		};

		gpio130_pmx_idle {
			pinctrl-single,pins = <0x08 0x00>;
		};

		gpio131_pmx_func {
			pinctrl-single,pins = <0x0c 0x00>;
		};

		gpio131_pmx_idle {
			pinctrl-single,pins = <0x0c 0x00>;
		};

		gpio132_pmx_func {
			pinctrl-single,pins = <0x10 0x00>;
		};

		gpio132_pmx_idle {
			pinctrl-single,pins = <0x10 0x00>;
		};

		gpio133_pmx_func {
			pinctrl-single,pins = <0x14 0x00>;
		};

		gpio133_pmx_idle {
			pinctrl-single,pins = <0x14 0x00>;
		};
	};

	pinmux@fc182800 {
		phandle = <0x3ff>;

		gpio128_cfg_func {
			pinctrl-single,bias-pulldown = <0x00 0x02 0x00 0x02>;
			pinctrl-single,bias-pullup = <0x01 0x01 0x00 0x01>;
			pinctrl-single,drive-strength = <0x00 0x70>;
		};

		gpio128_cfg_idle {
			pinctrl-single,bias-pulldown = <0x00 0x02 0x00 0x02>;
			pinctrl-single,bias-pullup = <0x01 0x01 0x00 0x01>;
			pinctrl-single,drive-strength = <0x00 0x70>;
		};

		gpio129_cfg_func {
			pinctrl-single,bias-pullup = <0x01 0x01 0x00 0x01>;
			pinctrl-single,drive-strength = <0x00 0x70>;
		};

		gpio129_cfg_idle {
			pinctrl-single,bias-pullup = <0x01 0x01 0x00 0x01>;
			pinctrl-single,drive-strength = <0x00 0x70>;
		};

		gpio130_cfg_func {
			pinctrl-single,bias-pulldown = <0x02 0x02 0x00 0x02>;
			pinctrl-single,bias-pullup = <0x00 0x01 0x00 0x01>;
			pinctrl-single,drive-strength = <0x00 0x70>;
		};

		gpio130_cfg_idle {
			pinctrl-single,bias-pulldown = <0x02 0x02 0x00 0x02>;
			pinctrl-single,bias-pullup = <0x00 0x01 0x00 0x01>;
			pinctrl-single,drive-strength = <0x00 0x70>;
		};

		gpio131_cfg_func {
			pinctrl-single,bias-pullup = <0x00 0x01 0x00 0x01>;
			pinctrl-single,drive-strength = <0x00 0x70>;
		};

		gpio131_cfg_idle {
			pinctrl-single,bias-pullup = <0x00 0x01 0x00 0x01>;
			pinctrl-single,drive-strength = <0x00 0x70>;
		};

		gpio132_cfg_func {
			pinctrl-single,bias-pulldown = <0x00 0x02 0x00 0x02>;
			pinctrl-single,bias-pullup = <0x00 0x01 0x00 0x01>;
			pinctrl-single,drive-strength = <0x00 0x70>;
		};

		gpio132_cfg_idle {
			pinctrl-single,bias-pulldown = <0x00 0x02 0x00 0x02>;
			pinctrl-single,bias-pullup = <0x00 0x01 0x00 0x01>;
			pinctrl-single,drive-strength = <0x00 0x70>;
		};

		gpio133_cfg_func {
			pinctrl-single,bias-pullup = <0x00 0x01 0x00 0x01>;
			pinctrl-single,drive-strength = <0x00 0x70>;
		};

		gpio133_cfg_idle {
			pinctrl-single,bias-pullup = <0x00 0x01 0x00 0x01>;
			pinctrl-single,drive-strength = <0x00 0x70>;
		};

		gpio134_cfg_func {
			pinctrl-single,bias-pullup = <0x00 0x01 0x00 0x01>;
		};

		gpio134_cfg_idle {
			pinctrl-single,bias-pullup = <0x00 0x01 0x00 0x01>;
		};

		gpio135_cfg_func {
			pinctrl-single,bias-pulldown = <0x00 0x02 0x00 0x02>;
		};

		gpio135_cfg_idle {
			pinctrl-single,bias-pulldown = <0x00 0x02 0x00 0x02>;
		};

		gpio136_cfg_func {
			pinctrl-single,bias-pullup = <0x00 0x01 0x00 0x01>;
		};

		gpio136_cfg_idle {
			pinctrl-single,bias-pullup = <0x00 0x01 0x00 0x01>;
		};

		gpio137_cfg_func {
			pinctrl-single,bias-pulldown = <0x00 0x02 0x00 0x02>;
			pinctrl-single,bias-pullup = <0x01 0x01 0x00 0x01>;
		};

		gpio137_cfg_idle {
			pinctrl-single,bias-pulldown = <0x00 0x02 0x00 0x02>;
			pinctrl-single,bias-pullup = <0x01 0x01 0x00 0x01>;
		};
	};

	pinmux@ff37e000 {
		phandle = <0x69>;

		gpio160_pmx_func {
			pinctrl-single,pins = <0x00 0x00>;
		};

		gpio161_pmx_func {
			pinctrl-single,pins = <0x04 0x00>;
		};

		gpio161_pmx_idle {
			pinctrl-single,pins = <0x04 0x00>;
		};

		gpio162_pmx_func {
			pinctrl-single,pins = <0x08 0x00>;
		};

		gpio162_pmx_idle {
			pinctrl-single,pins = <0x08 0x00>;
		};

		gpio163_pmx_func {
			pinctrl-single,pins = <0x0c 0x00>;
		};

		gpio164_pmx_func {
			pinctrl-single,pins = <0x10 0x00>;
		};

		gpio165_pmx_func {
			pinctrl-single,pins = <0x14 0x00>;
		};

		gpio166_pmx_func {
			phandle = <0x400>;
		};

		gpio166_pmx_idle {
			phandle = <0x401>;
		};

		gpio167_pmx_func {
			phandle = <0x402>;
		};

		gpio167_pmx_idle {
			phandle = <0x403>;
		};

		gpio168_pmx_func {
			phandle = <0x404>;
		};

		gpio168_pmx_idle {
			phandle = <0x405>;
		};

		gpio169_pmx_func {
			pinctrl-single,pins = <0x24 0x01>;
			phandle = <0x406>;
		};

		gpio169_pmx_idle {
			pinctrl-single,pins = <0x24 0x01>;
			phandle = <0x407>;
		};

		gpio170_pmx_func {
			pinctrl-single,pins = <0x28 0x01>;
			phandle = <0x408>;
		};

		gpio170_pmx_idle {
			pinctrl-single,pins = <0x28 0x01>;
			phandle = <0x409>;
		};

		gpio171_pmx_func {
			pinctrl-single,pins = <0x2c 0x01>;
			phandle = <0x40a>;
		};

		gpio171_pmx_idle {
			pinctrl-single,pins = <0x2c 0x01>;
			phandle = <0x40b>;
		};
	};

	pinmux@ff37e800 {
		phandle = <0x40c>;

		gpio160_cfg_func {
			pinctrl-single,bias-pulldown = <0x00 0x02 0x00 0x02>;
			pinctrl-single,bias-pullup = <0x01 0x01 0x00 0x01>;
			pinctrl-single,drive-strength = <0x00 0x70>;
			pinctrl-single,slew-rate = <0x00 0x80>;
		};

		gpio160_cfg_idle {
			pinctrl-single,bias-pulldown = <0x00 0x02 0x00 0x02>;
			pinctrl-single,bias-pullup = <0x01 0x01 0x00 0x01>;
			pinctrl-single,drive-strength = <0x00 0x70>;
			pinctrl-single,slew-rate = <0x00 0x80>;
		};

		gpio161_cfg_func {
			pinctrl-single,bias-pulldown = <0x00 0x02 0x00 0x02>;
			pinctrl-single,bias-pullup = <0x00 0x01 0x00 0x01>;
			pinctrl-single,drive-strength = <0x00 0x70>;
			pinctrl-single,slew-rate = <0x00 0x80>;
		};

		gpio161_cfg_idle {
			pinctrl-single,bias-pulldown = <0x00 0x02 0x00 0x02>;
			pinctrl-single,bias-pullup = <0x00 0x01 0x00 0x01>;
			pinctrl-single,drive-strength = <0x00 0x70>;
			pinctrl-single,slew-rate = <0x00 0x80>;
		};

		gpio162_cfg_func {
			pinctrl-single,bias-pulldown = <0x00 0x02 0x00 0x02>;
			pinctrl-single,bias-pullup = <0x00 0x01 0x00 0x01>;
			pinctrl-single,drive-strength = <0x00 0x70>;
			pinctrl-single,slew-rate = <0x00 0x80>;
		};

		gpio162_cfg_idle {
			pinctrl-single,bias-pulldown = <0x00 0x02 0x00 0x02>;
			pinctrl-single,drive-strength = <0x00 0x70>;
			pinctrl-single,slew-rate = <0x00 0x80>;
		};

		gpio163_cfg_func {
			pinctrl-single,bias-pulldown = <0x00 0x02 0x00 0x02>;
			pinctrl-single,bias-pullup = <0x00 0x01 0x00 0x01>;
			pinctrl-single,drive-strength = <0x00 0x70>;
			pinctrl-single,slew-rate = <0x00 0x80>;
		};

		gpio163_cfg_idle {
			pinctrl-single,bias-pulldown = <0x00 0x02 0x00 0x02>;
			pinctrl-single,drive-strength = <0x00 0x70>;
			pinctrl-single,slew-rate = <0x00 0x80>;
		};

		gpio164_cfg_func {
			pinctrl-single,bias-pulldown = <0x00 0x02 0x00 0x02>;
			pinctrl-single,bias-pullup = <0x01 0x01 0x00 0x01>;
			pinctrl-single,drive-strength = <0x00 0x70>;
			pinctrl-single,slew-rate = <0x00 0x80>;
		};

		gpio164_cfg_idle {
			pinctrl-single,bias-pulldown = <0x00 0x02 0x00 0x02>;
			pinctrl-single,bias-pullup = <0x01 0x01 0x00 0x01>;
			pinctrl-single,drive-strength = <0x00 0x70>;
			pinctrl-single,slew-rate = <0x00 0x80>;
		};

		gpio165_cfg_func {
			pinctrl-single,bias-pulldown = <0x00 0x02 0x00 0x02>;
			pinctrl-single,bias-pullup = <0x00 0x01 0x00 0x01>;
			pinctrl-single,drive-strength = <0x00 0x70>;
			pinctrl-single,slew-rate = <0x00 0x80>;
		};

		gpio165_cfg_idle {
			pinctrl-single,bias-pulldown = <0x00 0x02 0x00 0x02>;
			pinctrl-single,drive-strength = <0x00 0x70>;
			pinctrl-single,slew-rate = <0x00 0x80>;
		};

		gpio166_cfg_func {
			pinctrl-single,drive-strength = <0x10 0xf0>;
			phandle = <0x40d>;
		};

		gpio166_cfg_idle {
			pinctrl-single,drive-strength = <0x10 0xf0>;
			phandle = <0x40e>;
		};

		gpio167_cfg_func {
			pinctrl-single,drive-strength = <0x10 0xf0>;
			phandle = <0x40f>;
		};

		gpio167_cfg_idle {
			pinctrl-single,drive-strength = <0x10 0xf0>;
			phandle = <0x410>;
		};

		gpio168_cfg_func {
			pinctrl-single,drive-strength = <0x10 0xf0>;
			phandle = <0x411>;
		};

		gpio168_cfg_idle {
			pinctrl-single,drive-strength = <0x10 0xf0>;
			phandle = <0x412>;
		};

		gpio169_cfg_func {
			pinctrl-single,bias-pullup = <0x00 0x01 0x00 0x01>;
			pinctrl-single,drive-strength = <0x10 0xf0>;
			phandle = <0x413>;
		};

		gpio169_cfg_idle {
			pinctrl-single,bias-pullup = <0x00 0x01 0x00 0x01>;
			pinctrl-single,drive-strength = <0x10 0xf0>;
			phandle = <0x414>;
		};

		gpio170_cfg_func {
			pinctrl-single,drive-strength = <0x10 0xf0>;
			phandle = <0x415>;
		};

		gpio170_cfg_idle {
			pinctrl-single,drive-strength = <0x10 0xf0>;
			phandle = <0x416>;
		};

		gpio171_cfg_func {
			pinctrl-single,bias-pullup = <0x00 0x01 0x00 0x01>;
			pinctrl-single,drive-strength = <0x10 0xf0>;
			phandle = <0x417>;
		};

		gpio171_cfg_idle {
			pinctrl-single,bias-pullup = <0x00 0x01 0x00 0x01>;
			pinctrl-single,drive-strength = <0x10 0xf0>;
			phandle = <0x418>;
		};
	};

	pinmux@fff1191c {
		phandle = <0x419>;
	};

	pinmux@fff118dc {
		phandle = <0x41a>;
	};

	sec_pinmux@e896c824 {
		phandle = <0x41b>;
	};

	sec_pinmux@e896c878 {
		phandle = <0x41c>;
	};

	sec_pinmux@fff118b0 {
		phandle = <0x41d>;
	};

	sec_pinmux@fff1190c {
		phandle = <0x41e>;
	};

	amba {
		phandle = <0x41f>;

		i2c@FFD71000 {
			phandle = <0x420>;
		};

		i2c@FFD72000 {
			phandle = <0x421>;

			rt9748@67 {
				status = "ok";
				phandle = <0x422>;
			};

			fusb30x_i2c1@22 {
				status = "ok";
				fairchild,int_n = <0x2b 0x06 0x00>;
			};

			tusb422_i2c1@20 {
				status = "ok";
				ti,alert-gpio = <0x2b 0x06 0x00>;
			};

			rt1711_i2c1@4e {
				status = "ok";
				rt1711,irq_pin = <0x2b 0x06 0x00>;

				pd-data {
					pd,id-vdo-size = <0x04>;
					pd,id-vdo-data = <0xec0012d1 0x00 0x107e0000 0x11000001>;
				};
			};
		};

		i2c@FFD73000 {
			clocks = <0x2c 0x28>;
			phandle = <0x423>;
		};

		i2c@FDF0C000 {
			clocks = <0x2d 0x28>;
			status = "ok";
			phandle = <0x424>;

			bq25892_charger_aux@6B {
				gpio_cd = <0x2e 0x07 0x00>;
				gpio_int = <0x2f 0x06 0x00>;
				phandle = <0x425>;
			};

			ti,lm36923 {
				compatible = "ti,lm36923", "ti,lm36923_i2c3";
				support = <0x01>;
				lm36923-ctrl-mode = <0x00>;
				lcd-bl-ic-name = "LM36923YFFR";
				lm36923-led-num = <0x02>;
				fake_panel_enable_reg = <0x03>;
				lm36923_hw_en_gpio = <0x0b>;
				lm36923-boost-ctrl-1 = <0x7d>;
				lm36923-fault-ctrl = <0x00>;
				status = "ok";
			};

			max77813@18 {
				reg = <0x18>;
				phandle = <0x426>;
			};

			huawei,vl53l0@29 {
				compatible = "huawei,vl53l0_970";
				reg = <0x29>;
				status = "ok";
				phandle = <0x427>;
			};
		};

		i2c@FDF0D000 {
			clocks = <0x30 0x28>;
			phandle = <0x428>;

			huawei,lm3646@67 {
				huawei,led-type = <0x01>;
				huawei,flash-current = <0x7c 0x7f 0x00>;
				status = "disabled";
				phandle = <0x429>;
			};

			huawei,mp3336@27 {
				huawei,led-type = <0x01>;
				huawei,flash-current = <0xbe 0xbe 0x00>;
				status = "disabled";
				phandle = <0x42a>;
			};

			charger@6B {
				gpio_cd = <0x2f 0x01 0x00>;
				gpio_int = <0x2f 0x04 0x00>;
				phandle = <0x42b>;
			};

			bq2429x_charger@6B {
				gpio_cd = <0x2f 0x01 0x00>;
				gpio_int = <0x2f 0x04 0x00>;
				phandle = <0x42c>;
			};

			bq25892_charger@6B {
				gpio_cd = <0x2f 0x01 0x00>;
				gpio_int = <0x2f 0x04 0x00>;
				phandle = <0x42d>;
			};

			bq25892_charger_main@6B {
				gpio_cd = <0x2f 0x01 0x00>;
				gpio_int = <0x2f 0x04 0x00>;
				phandle = <0x42e>;
			};

			hi6523_charger@6B {
				gpio_int = <0x2f 0x04 0x00>;
				phandle = <0x42f>;
			};

			ak4376@10 {
				status = "disabled";
				phandle = <0x430>;
			};

			smartpa@31 {
				phandle = <0x431>;
			};

			smartpa@34 {
				compatible = "huawei,max98925";
				smartpa_type = <0x01>;
				reg = <0x34>;
				gain = <0x34>;
				gain_incall = <0x36>;
				iv_slot_change = <0x00>;
				status = "disabled";
				phandle = <0x432>;
			};

			smartpa@35 {
				compatible = "huawei,tfa9872";
				smartpa_type = <0x00>;
				reg = <0x35>;
				gain = <0x14>;
				gain_incall = <0x14>;
				gpio_irq = <0x00>;
				gpio_reset = <0x00>;
				status = "disabled";
				phandle = <0x433>;
			};

			smartpa@36 {
				compatible = "huawei,tfa9872";
				smartpa_type = <0x01>;
				reg = <0x36>;
				gain = <0x34>;
				gain_incall = <0x36>;
				gpio_irq = <0x00>;
				gpio_reset = <0x00>;
				status = "disabled";
				phandle = <0x434>;
			};

			smartpa@4C {
				compatible = "huawei,tas2560";
				gpio_reset = <0x00>;
				status = "disabled";
				phandle = <0x435>;
			};

			smartpa@4F {
				compatible = "huawei,tas2560";
				status = "disabled";
				phandle = <0x436>;
			};

			fusb30x_i2c4@22 {
				compatible = "fairchild,fusb302";
				reg = <0x22>;
				status = "disabled";
				fairchild,int_n = <0x2b 0x06 0x00>;
				vconn_swap_to_on_supported;
				vconn_swap_to_off_supported;
				dp_enabled;
				product_type_ama;
				modal_operation_supported;
				discover_mode_supported;
				enter_mode_supported;
				discover_svid_supported;
			};

			tusb422_i2c4@20 {
				compatible = "ti,tusb422-usb-pd";
				reg = <0x20>;
				status = "disabled";
				ti,alert-gpio = <0x2b 0x06 0x00>;
				ti,usb-comm-capable;
				ti,no-usb-suspend;
				ti,dual-role-data;
				ti,auto-accept-swap-to-dfp;
				ti,auto-accept-swap-to-ufp;
				ti,auto-accept-swap-to-source;
				ti,auto-accept-swap-to-sink;
				ti,auto-accept-vconn-swap;
				ti,src-settling-time-ms = <0x32>;
				ti,fast-role-swap-support = <0x00>;
				ti,pdo-priority = <0x00>;
				ti,role = <0x02>;
				ti,rp-val = <0x00>;
				ti,flags = <0x02>;
				ti,id-header-vdo = <0xd50012d1>;
				ti,cert-stat-vdo = <0x00>;
				ti,product-vdo = <0x107e0000>;
				ti,num-product-type-vdos = <0x00>;
				ti,product-type-vdo-1 = <0x00>;
				ti,product-type-vdo-2 = <0x00>;
				ti,product-type-vdo-3 = <0x00>;
				ti,num-svids = <0x01>;
				ti,svid-1 = <0xff01>;
				ti,svid-2 = <0x00>;
				ti,svid-3 = <0x00>;
				ti,mode-1 = <0x1c46>;
				ti,mode-2 = <0x00>;
				ti,mode-3 = <0x00>;

				source@1 {
					ti,current-flow = <0x00>;
					ti,supply-type = <0x00>;
					ti,pdo-number = <0x00>;
					ti,min-voltage = <0x1388>;
					ti,max-voltage = <0x00>;
					ti,peak-current = <0x00>;
					ti,max-current = <0x3e8>;
					ti,max-power = <0x00>;
				};

				sink@1 {
					ti,current-flow = <0x01>;
					ti,supply-type = <0x00>;
					ti,pdo-number = <0x00>;
					ti,min-voltage = <0x1388>;
					ti,max-voltage = <0x00>;
					ti,max-operating-curr = <0x7d0>;
					ti,min-operating-curr = <0x64>;
					ti,operational-curr = <0x7d0>;
					ti,max-operating-pwr = <0x00>;
					ti,min-operating-pwr = <0x00>;
					ti,operational-pwr = <0x00>;
					ti,peak-current = <0x00>;
				};

				sink@2 {
					ti,current-flow = <0x01>;
					ti,supply-type = <0x00>;
					ti,pdo-number = <0x01>;
					ti,min-voltage = <0x2328>;
					ti,max-voltage = <0x00>;
					ti,max-operating-curr = <0x7d0>;
					ti,min-operating-curr = <0x64>;
					ti,operational-curr = <0x7d0>;
					ti,max-operating-pwr = <0x00>;
					ti,min-operating-pwr = <0x00>;
					ti,operational-pwr = <0x00>;
					ti,peak-current = <0x00>;
				};
			};

			rt1711_i2c4@4e {
				compatible = "richtek,rt1711";
				reg = <0x4e>;
				status = "disabled";
				rt1711,irq_pin = <0x2b 0x06 0x00>;
				rt-dual,supported_modes = <0x00>;
				rt-tcpc,name = "type_c_port0";
				rt-tcpc,role_def = <0x04>;
				rt-tcpc,rp_level = <0x00>;
				rt-tcpc,notifier_supply_num = <0x00>;

				pd-data {
					pd,source-pdo-size = <0x01>;
					pd,source-pdo-data = <0x19064>;
					pd,sink-pdo-size = <0x02>;
					pd,sink-pdo-data = <0x190c8 0x2d0c8>;
					pd,id-vdo-size = <0x04>;
					pd,id-vdo-data = <0xec0012d1 0x00 0x107e0000 0x11000001>;
				};

				dpm_caps {
					local_dr_power;
					local_dr_data;
					local_usb_comm;
					local_no_suspend;
					local_vconn_supply;
					attemp_enter_dp_mode;
					attemp_discover_cable;
					attemp_discover_id;
					pr_check = <0x00>;
					pr_check_gp_source;
					dr_check = <0x00>;
					snk_prefer_low_voltage;
				};

				displayport {
					1st_connection = "dfp_d";
					2nd_connection = "dfp_d";
					signal,dp_v13;
					typec,receptacle;

					ufp_d {
					};

					dfp_d {
						pin_assignment,mode_c;
						pin_assignment,mode_d;
					};
				};
			};

			ti-drv2605@5a {
				status = "ok";
			};

			ams_tcs3430@39 {
				status = "ok";
				reg = <0x39>;
				compatible = "ams,tcs3430";
			};

			nfc@28 {
				status = "ok";
				reg = <0x28>;
				compatible = "hisilicon,pn547_nfc";
				phandle = <0x437>;
			};

			huawei,mp3331@67 {
				compatible = "huawei,mp3331";
				reg = <0x67>;
				huawei,flash-name = "mp3331";
				status = "ok";
				phandle = <0x438>;
			};

			huawei,lm3642@63 {
				compatible = "huawei,lm3642";
				reg = <0x63>;
				huawei,flash-name = "lm3642";
				status = "ok";
				phandle = <0x439>;
			};

			tps65132@3e {
				status = "ok";
				reg = <0x3e>;
				compatible = "huawei,hw_tps65132";
				phandle = <0x43a>;
			};

			lv52134a@42 {
				status = "ok";
				reg = <0x42>;
				compatible = "huawei,hw_lv52134a";
				phandle = <0x43b>;
			};

			rt4801h@73 {
				status = "ok";
				reg = <0x73>;
				compatible = "huawei,hw_rt4801h";
				phandle = <0x43c>;
			};
		};

		i2c@FFD6A000 {
			clocks = <0x31 0x28>;
			phandle = <0x43d>;

			bq25892_charger_i2c6@6B {
				gpio_cd = <0x32 0x04 0x00>;
				gpio_int = <0x2f 0x04 0x00>;
				phandle = <0x43e>;
			};

			hi6523_charger_i2c6@6B {
				gpio_int = <0x2f 0x04 0x00>;
				bat_comp = <0x3c>;
				vclamp = <0xc0>;
				single_phase_buck = <0x00>;
				fcp_support = <0x00>;
				phandle = <0x43f>;
			};

			wireless_idtp9221_i2c6@61 {
				gpio_int = <0x33 0x00 0x00>;
				gpio_en = <0x34 0x02 0x00>;
				gpio_sleep_en = <0x35 0x01 0x00>;
				phandle = <0x440>;
			};
		};

		i2c@FDF0B000 {
			clocks = <0x36 0x28>;
			phandle = <0x441>;
		};

		uart@fdf02000 {
			dmas = <0x37 0x00 0x37 0x01>;
			clocks = <0x38 0x39>;
			phandle = <0x442>;
		};

		uart@fdf00000 {
			dmas = <0x37 0x02 0x37 0x03>;
			clocks = <0x3a 0x3a>;
			phandle = <0x443>;
		};

		uart@fdf03000 {
			dmas = <0x37 0x04 0x37 0x05>;
			clocks = <0x3b 0x3b>;
			phandle = <0x444>;
		};

		uart@ffd74000 {
			dmas = <0x37 0x18 0x37 0x19>;
			clocks = <0x3c 0x28>;
			phandle = <0x445>;
		};

		uart@fdf01000 {
			dmas = <0x37 0x06 0x37 0x07>;
			clocks = <0x3d 0x3e>;
			phandle = <0x446>;
		};

		uart@fdf05000 {
			dmas = <0x37 0x08 0x37 0x09>;
			clocks = <0x3f 0x3f>;
			phandle = <0x447>;
		};

		uart@fff32000 {
			clocks = <0x40 0x28>;
			phandle = <0x448>;
		};

		spi@ffd70000 {
			clocks = <0x41 0x41>;
			phandle = <0x449>;

			spi_dev0@0 {
				phandle = <0x44a>;
			};

			spi_dev1@1 {
				reg = <0x01>;
				phandle = <0x44b>;
			};

			spi_dev2@2 {
				reg = <0x02>;
				phandle = <0x44c>;
			};

			spi_dev3@3 {
				reg = <0x03>;
				phandle = <0x44d>;
			};
		};

		spi@fdf08000 {
			clocks = <0x42 0x42>;
			dmas = <0x37 0x0a 0x37 0x0b>;
			phandle = <0x44e>;

			spi_dev10@10 {
				reg = <0x00>;
				phandle = <0x44f>;
			};
		};

		spi@ffd68000 {
			clocks = <0x43 0x43>;
			dmas = <0x37 0x16 0x37 0x17>;
			phandle = <0x450>;
		};

		spi@fff2a000 {
			status = "ok";
			clocks = <0x44 0x44>;
			dmas = <0x37 0x0c 0x37 0x0d>;
			pinctrl-0 = <0x45 0x46 0x47 0x48 0x49 0x4a>;
			pinctrl-1 = <0x4b 0x4c 0x4d 0x4e 0x4f 0x50>;
			phandle = <0x451>;

			huawei_thp@10 {
				compatible = "huawei,thp";
				reg = <0x00>;
				phandle = <0x452>;

				thp_input_dev {
					compatible = "huawei,thp_input";
				};

				novatech {
				};

				rohm-bu21150 {
				};
			};

			spi_dev30@30 {
				compatible = "spi_dev30";
				reg = <0x00>;
				phandle = <0x453>;
			};

			spi_dev31@31 {
				compatible = "spi_dev31";
				reg = <0x01>;
				phandle = <0x454>;
			};

			spi_dev32@32 {
				compatible = "spi_dev32";
				reg = <0x02>;
				phandle = <0x455>;
			};

			spi_dev33@33 {
				compatible = "spi_dev33";
				reg = <0x03>;
				phandle = <0x456>;
			};
		};

		spi@fdf06000 {
			clocks = <0x51 0x51>;
			dmas = <0x37 0x14 0x37 0x15>;
			phandle = <0x457>;
		};

		gpio@e8a0b000 {
			gpio-ranges = <0x52 0x01 0x00 0x01 0x52 0x03 0x01 0x05>;
			clocks = <0x53 0x28>;
			phandle = <0x2e>;
		};

		gpio@e8a0c000 {
			clocks = <0x54 0x28>;
		};

		gpio@e8a0d000 {
			gpio-ranges = <0x52 0x01 0x06 0x07>;
			clocks = <0x55 0x28>;
		};

		gpio@e8a0e000 {
			gpio-ranges = <0x52 0x00 0x0d 0x04 0x52 0x07 0x11 0x01>;
			clocks = <0x56 0x28>;
			phandle = <0x458>;
		};

		gpio@e8a0f000 {
			gpio-ranges = <0x52 0x00 0x12 0x08>;
			clocks = <0x57 0x28>;
		};

		gpio@e8a10000 {
			gpio-ranges = <0x52 0x00 0x1a 0x08>;
			clocks = <0x58 0x28>;
			phandle = <0x32>;
		};

		gpio@e8a11000 {
			gpio-ranges = <0x52 0x01 0x22 0x07>;
			clocks = <0x59 0x28>;
			phandle = <0x34>;
		};

		gpio@e8a12000 {
			gpio-ranges = <0x52 0x00 0x29 0x08>;
			clocks = <0x5a 0x28>;
		};

		gpio@e8a13000 {
			gpio-ranges = <0x52 0x00 0x31 0x08>;
			clocks = <0x5b 0x28>;
			phandle = <0xa2>;
		};

		gpio@e8a14000 {
			gpio-ranges = <0x52 0x00 0x39 0x08>;
			clocks = <0x5c 0x28>;
		};

		gpio@e8a15000 {
			gpio-ranges = <0x52 0x00 0x41 0x08>;
			clocks = <0x5d 0x28>;
			phandle = <0x459>;
		};

		gpio@e8a16000 {
			gpio-ranges = <0x52 0x00 0x49 0x08>;
			clocks = <0x5e 0x28>;
			phandle = <0x45a>;
		};

		gpio@e8a17000 {
			gpio-ranges = <0x52 0x00 0x51 0x01>;
			clocks = <0x5f 0x28>;
			phandle = <0x45b>;
		};

		gpio@e8a18000 {
			clocks = <0x60 0x28>;
			phandle = <0x45c>;
		};

		gpio@e8a19000 {
			clocks = <0x61 0x28>;
			phandle = <0x45d>;
		};

		gpio@e8a1a000 {
			clocks = <0x62 0x28>;
			phandle = <0x45e>;
		};

		gpio@e8a1b000 {
			gpio-ranges = <0x63 0x00 0x00 0x08>;
			clocks = <0x64 0x28>;
			phandle = <0xa3>;
		};

		gpio@e8a1c000 {
			gpio-ranges = <0x63 0x00 0x08 0x02>;
			clocks = <0x65 0x28>;
			phandle = <0x45f>;
		};

		gpio@fff28000 {
			gpio-ranges = <0x66 0x04 0x2a 0x04>;
			clocks = <0x67 0x28>;
			phandle = <0x33>;
		};

		gpio@fff29000 {
			gpio-ranges = <0x66 0x00 0x3d 0x02>;
			clocks = <0x68 0x28>;
			phandle = <0x460>;
		};

		gpio@e8a1f000 {
			gpio-ranges = <0x69 0x00 0x00 0x08>;
			clocks = <0x6a 0x28>;
			phandle = <0x35>;
		};

		gpio@e8a20000 {
			gpio-ranges = <0x69 0x00 0x08 0x04>;
			clocks = <0x6b 0x28>;
			phandle = <0x461>;
		};

		gpio@fff0b000 {
			gpio-ranges = <0x66 0x02 0x00 0x06>;
			clocks = <0x6c 0x28>;
			phandle = <0x2f>;
		};

		gpio@fff0c000 {
			gpio-ranges = <0x66 0x00 0x06 0x08>;
			clocks = <0x6d 0x28>;
		};

		gpio@fff0d000 {
			gpio-ranges = <0x66 0x00 0x0e 0x08>;
			clocks = <0x6e 0x28>;
		};

		gpio@fff0e000 {
			gpio-ranges = <0x66 0x00 0x16 0x08>;
			clocks = <0x6f 0x28>;
		};

		gpio@fff0f000 {
			gpio-ranges = <0x66 0x00 0x1e 0x01>;
			clocks = <0x70 0x28>;
		};

		gpio@fff10000 {
			gpio-ranges = <0x66 0x04 0x1f 0x04>;
		};

		gpio@fff1d000 {
			gpio-ranges = <0x66 0x01 0x23 0x07>;
			clocks = <0x71 0x28>;
			phandle = <0x462>;
		};

		etm@0,ecc40000 {
			cluster_etb = <0x72>;
			cluster_funnel = <0x73>;

			port {
				endpoint {
					remote-endpoint = <0x74>;
					phandle = <0x79>;
				};
			};
		};

		cti_cpu0@0,ecc20000 {
			phandle = <0x463>;
		};

		etm@1,ecd40000 {
			cluster_etb = <0x72>;
			cluster_funnel = <0x73>;

			port {
				endpoint {
					remote-endpoint = <0x75>;
					phandle = <0x7a>;
				};
			};
		};

		cti_cpu1@1,ecd20000 {
			phandle = <0x464>;
		};

		etm@2,ece40000 {
			cluster_etb = <0x72>;
			cluster_funnel = <0x73>;

			port {
				endpoint {
					remote-endpoint = <0x76>;
					phandle = <0x7b>;
				};
			};
		};

		cti_cpu2@2,ece20000 {
			phandle = <0x465>;
		};

		etm@3,ecf40000 {
			cluster_etb = <0x72>;
			cluster_funnel = <0x73>;

			port {
				endpoint {
					remote-endpoint = <0x77>;
					phandle = <0x7c>;
				};
			};
		};

		cti_cpu3@3,ecf20000 {
			phandle = <0x466>;
		};

		funnel@0,ec801000 {
			phandle = <0x73>;

			ports {
				port@0 {
					endpoint {
						remote-endpoint = <0x78>;
						phandle = <0x7d>;
					};
				};

				port@1 {
					endpoint {
						remote-endpoint = <0x79>;
						phandle = <0x74>;
					};
				};

				port@2 {
					endpoint {
						remote-endpoint = <0x7a>;
						phandle = <0x75>;
					};
				};

				port@3 {
					endpoint {
						remote-endpoint = <0x7b>;
						phandle = <0x76>;
					};
				};

				port@4 {
					endpoint {
						remote-endpoint = <0x7c>;
						phandle = <0x77>;
					};
				};
			};
		};

		etb@0,ec802000 {
			phandle = <0x72>;

			ports {
				port@0 {
					endpoint {
						remote-endpoint = <0x7d>;
						phandle = <0x78>;
					};
				};

				port@1 {
					endpoint {
						remote-endpoint = <0x7e>;
						phandle = <0x8e>;
					};
				};
			};
		};

		etm@4,ed440000 {
			cluster_etb = <0x7f>;
			cluster_funnel = <0x80>;

			port {
				endpoint {
					remote-endpoint = <0x81>;
					phandle = <0x86>;
				};
			};
		};

		cti_cpu4@4,ed420000 {
			phandle = <0x467>;
		};

		etm@5,ed540000 {
			cluster_etb = <0x7f>;
			cluster_funnel = <0x80>;

			port {
				endpoint {
					remote-endpoint = <0x82>;
					phandle = <0x87>;
				};
			};
		};

		cti_cpu5@5,ed520000 {
			phandle = <0x468>;
		};

		etm@6,ed640000 {
			cluster_etb = <0x7f>;
			cluster_funnel = <0x80>;

			port {
				endpoint {
					remote-endpoint = <0x83>;
					phandle = <0x88>;
				};
			};
		};

		cti_cpu6@6,ed620000 {
			phandle = <0x469>;
		};

		etm@7,ed740000 {
			cluster_etb = <0x7f>;
			cluster_funnel = <0x80>;

			port {
				endpoint {
					remote-endpoint = <0x84>;
					phandle = <0x89>;
				};
			};
		};

		cti_cpu7@7,ed720000 {
			phandle = <0x46a>;
		};

		funnel@1,ed001000 {
			phandle = <0x80>;

			ports {
				port@0 {
					endpoint {
						remote-endpoint = <0x85>;
						phandle = <0x8a>;
					};
				};

				port@1 {
					endpoint {
						remote-endpoint = <0x86>;
						phandle = <0x81>;
					};
				};

				port@2 {
					endpoint {
						remote-endpoint = <0x87>;
						phandle = <0x82>;
					};
				};

				port@3 {
					endpoint {
						remote-endpoint = <0x88>;
						phandle = <0x83>;
					};
				};

				port@4 {
					endpoint {
						remote-endpoint = <0x89>;
						phandle = <0x84>;
					};
				};
			};
		};

		etb@1,ed002000 {
			phandle = <0x7f>;

			ports {
				port@0 {
					endpoint {
						remote-endpoint = <0x8a>;
						phandle = <0x85>;
					};
				};

				port@1 {
					endpoint {
						remote-endpoint = <0x8b>;
						phandle = <0x8f>;
					};
				};
			};
		};

		funnel@2,ec031000 {
			clocks = <0x8c 0x28>;

			ports {
				port@0 {
					endpoint {
						remote-endpoint = <0x8d>;
						phandle = <0x90>;
					};
				};

				port@1 {
					endpoint {
						remote-endpoint = <0x8e>;
						phandle = <0x7e>;
					};
				};

				port@2 {
					endpoint {
						remote-endpoint = <0x8f>;
						phandle = <0x8b>;
					};
				};
			};
		};

		etb@2,ec036000 {
			clocks = <0x8c 0x28>;

			ports {
				port@0 {
					endpoint {
						remote-endpoint = <0x90>;
						phandle = <0x8d>;
					};
				};

				port@1 {
					endpoint {
						remote-endpoint = <0x91>;
						phandle = <0x92>;
					};
				};
			};
		};

		replicator@0 {
			clocks = <0x8c 0x28>;

			ports {
				port@0 {
					endpoint {
						remote-endpoint = <0x92>;
						phandle = <0x91>;
					};
				};

				port@1 {
					endpoint {
						remote-endpoint = <0x93>;
						phandle = <0x94>;
					};
				};
			};
		};

		etr@0,ec033000 {
			clocks = <0x8c 0x28>;

			ports {
				port@0 {
					endpoint {
						remote-endpoint = <0x94>;
						phandle = <0x93>;
					};
				};
			};
		};

		tsgen@0,ec037000 {
			clocks = <0x95>;
		};

		watchdog0 {
			status = "disabled";
		};

		watchdog@ffd7c000 {
			phandle = <0x46b>;
		};

		dx_cc63p@fdf0e000 {
			phandle = <0x46c>;
		};
	};

	thermal-zones {
		soc_thermal@0 {
			thermal-sensors = <0x96 0xff>;
			phandle = <0x46d>;

			trips {
				trip-point@0 {
					phandle = <0x46e>;
				};

				trip-point@1 {
					phandle = <0x97>;
				};
			};

			cooling-maps {
				map0 {
					trip = <0x97>;
					cooling-device = <0x98 0xffffffff 0xffffffff 0x01>;
				};

				map1 {
					trip = <0x97>;
					cooling-device = <0x99 0xffffffff 0xffffffff 0x01>;
				};

				map2 {
					trip = <0x97>;
					cooling-device = <0x9a 0xffffffff 0xffffffff 0x01>;
				};
			};
		};

		board_thermal {
			thermal-sensors = <0x9b 0x00>;

			trips {
				trip-point@0 {
					phandle = <0x46f>;
				};

				trip-point@1 {
					phandle = <0x9c>;
				};
			};

			cooling-maps {
				map0 {
					trip = <0x9c>;
					cooling-device = <0x98 0xffffffff 0xffffffff 0x01>;
				};

				map1 {
					trip = <0x9c>;
					cooling-device = <0x99 0xffffffff 0xffffffff 0x01>;
				};

				map2 {
					trip = <0x9c>;
					cooling-device = <0x9a 0xffffffff 0xffffffff 0x01>;
				};
			};
		};
	};

	ip_freq_autodown@0xFFF35000 {
		phandle = <0x470>;
	};

	mali@E82C0000 {
		clocks = <0x9d>;
		gpu-supply = <0x9e>;
		physical-memory-group-manager = <0x9f>;
		phandle = <0x9a>;
	};

	ipa-sensor@0 {
		phandle = <0x96>;
	};

	jtagtosd {
		sdio-ldo = <0xa0>;
		not_always_on;
	};

	rdr {
		bbox_addr = <0xa1>;
	};

	himntn {
		phandle = <0x471>;
	};

	codec_controller@e82b9000 {
		gpios = <0x2b 0x01 0x00 0xa2 0x04 0x00>;
		slimbusclk_io_driver = <0x02>;
		slimbusdata_io_driver = <0x02>;
		phandle = <0x472>;

		hi64xx_irq@0 {
			phandle = <0x473>;

			hi6403_codec@0 {
				hisilicon,mic_num = <0x03>;
				hisilicon,hs_det_trigger = <0x00>;
				hisilicon,ir_gpio = <0xa3 0x05 0x00>;
				use_stereo_smartpa = <0x01>;
				phandle = <0x474>;
			};

			test_hi64xx_irq@0 {
				phandle = <0x475>;
			};
		};

		test_codec_controller@0 {
			phandle = <0x476>;
		};
	};

	modem_pinctrl {
		compatible = "arm,modem_pinctrl";
		pinctrl-names = "init", "default", "idle";
		pinctrl-num = <0x29 0x29 0x29>;
		status = "ok";
	};

	clocks@0 {
		uart6clk {
			phandle = <0x40>;
		};

		clk_pmctrl@0xfff31000 {
			clk_g3d {
				phandle = <0x9d>;
			};
		};

		sctrl@0xfff0a000 {
			pclk_gpio18 {
				phandle = <0x67>;
			};

			pclk_gpio19 {
				phandle = <0x68>;
			};

			clk_spi3 {
				phandle = <0x44>;
			};

			pclk_ao_gpio0 {
				phandle = <0x6c>;
			};

			pclk_ao_gpio1 {
				phandle = <0x6d>;
			};

			pclk_ao_gpio2 {
				phandle = <0x6e>;
			};

			pclk_ao_gpio3 {
				phandle = <0x6f>;
			};

			pclk_ao_gpio4 {
				phandle = <0x70>;
			};

			pclk_ao_gpio6 {
				phandle = <0x71>;
			};
		};

		crgctrl@0xfff35000 {
			pclk_gpio0 {
				phandle = <0x53>;
			};

			pclk_gpio1 {
				phandle = <0x54>;
			};

			pclk_gpio2 {
				phandle = <0x55>;
			};

			pclk_gpio3 {
				phandle = <0x56>;
			};

			pclk_gpio4 {
				phandle = <0x57>;
			};

			pclk_gpio5 {
				phandle = <0x58>;
			};

			pclk_gpio6 {
				phandle = <0x59>;
			};

			pclk_gpio7 {
				phandle = <0x5a>;
			};

			pclk_gpio8 {
				phandle = <0x5b>;
			};

			pclk_gpio9 {
				phandle = <0x5c>;
			};

			pclk_gpio10 {
				phandle = <0x5d>;
			};

			pclk_gpio11 {
				phandle = <0x5e>;
			};

			pclk_gpio12 {
				phandle = <0x5f>;
			};

			pclk_gpio13 {
				phandle = <0x60>;
			};

			pclk_gpio14 {
				phandle = <0x61>;
			};

			pclk_gpio15 {
				phandle = <0x62>;
			};

			pclk_gpio16 {
				phandle = <0x64>;
			};

			pclk_gpio17 {
				phandle = <0x65>;
			};

			pclk_gpio20 {
				phandle = <0x6a>;
			};

			pclk_gpio21 {
				phandle = <0x6b>;
			};

			clk_at {
				phandle = <0x8c>;
			};

			clk_timestp_gt {
				phandle = <0x95>;
			};

			clk_timestp_div {
				clocks = <0x95>;
			};

			clk_uart1 {
				phandle = <0x3a>;
			};

			clk_uart4 {
				phandle = <0x3d>;
			};

			pclk_uart4 {
				phandle = <0x3e>;
			};

			clk_uart2 {
				phandle = <0x3b>;
			};

			clk_uart5 {
				phandle = <0x3f>;
			};

			pclk_uart0 {
				phandle = <0x39>;
			};

			clk_uart0_fac {
				phandle = <0x38>;
			};

			clk_i2c3 {
				phandle = <0x2d>;
			};

			clk_i2c4 {
				phandle = <0x30>;
			};

			clk_i2c7 {
				phandle = <0x36>;
			};

			clk_spi1 {
				phandle = <0x42>;
			};

			clk_spi4 {
				phandle = <0x51>;
			};
		};

		iomcu_crgctrl@0xFFD7E000 {
			clk_i2c2 {
				phandle = <0x2c>;
			};

			clk_i2c6 {
				phandle = <0x31>;
			};

			clk_spi0 {
				phandle = <0x41>;
			};

			clk_spi2 {
				phandle = <0x43>;
			};

			clk_uart3 {
				phandle = <0x3c>;
			};
		};
	};

	regulator_ip@0xFFF35000 {
		ip@9 {
			phandle = <0x9e>;
		};
	};

	spmi@FFF24000 {
		pmic@0 {
			ldo9@1C {
				phandle = <0xa0>;
			};

			pmic_mntn@a0 {
				OCP@216 {
					hisilicon,inacceptable-event = <0xf8>;
				};

				OCP@217 {
					hisilicon,inacceptable-event = <0xef>;
				};

				OCP@218 {
					hisilicon,inacceptable-event = <0xff>;
				};

				OCP@219 {
					hisilicon,inacceptable-event = <0x7f>;
				};
			};

			sim0 {
				allocate_gpio = <0x00>;
				shared_det_irq = <0x00>;
				send_msg_to_cp = <0x00>;
				card_tray_style = <0x00>;
				hpd_interrupt_to_close_ldo = <0x00>;
				det_debounce_wait_time = <0x00>;
				pmu_status1_address = <0x00>;
				pmu_ldo11_onoff_eco_address = <0x00>;
				pmu_ldo11_vset_address = <0x00>;
				pmu_ldo12_onoff_eco_address = <0x00>;
				pmu_ldo12_vset_address = <0x00>;
				pmu_sim_ctrl_address = <0x00>;
				pmu_sim_deb_ctrl_address = <0x00>;
				pmu_ldo11_onoff_value = <0x00>;
				pmu_ldo11_vset_value = <0x00>;
				pmu_ldo12_onoff_value = <0x00>;
				pmu_ldo12_vset_value = <0x00>;
			};

			sim1 {
				status = "ok";
			};
		};
	};

	aliases {
		mshc0 = "/dwmmc0@FC183000";
	};

	dwmmc0@FC183000 {
		compatible = "hisilicon,aries-dw-mshc";
		reg = <0x00 0xfc183000 0x00 0x1000>;
		interrupts = <0x00 0x8c 0x04>;
		clock-names = "ciu", "biu";
		interrupt-parent = <0x01>;
		num-slots = <0x01>;
		fifo-depth = <0x100>;
		card-detect-delay = <0xc8>;
		broken-cd;
		non-removable;
		supports-highspeed;
		caps2-mmc-hs200-1_8v;
		caps2-mmc-cache-ctrl;
		pinctrl-names = "default", "idle";
		status = "ok";

		slot@0 {
			reg = <0x00>;
			bus-width = <0x08>;
			disable-wp;
		};

		mmccard@0 {
			reg = <0x00>;
			compatible = "mmc-card";
			broken-hpi;
		};
	};

	dwmmc1@FF37F000 {
		status = "disabled";
	};

	ipc@e896b000 {
		mailbox-10 {
			timeout = <0x7d0>;
		};
	};

	hisi_usb@ff200000 {
		usb_support_dp = <0x00>;
		eye_diagram_param = <0xfdfee4>;
		eye_diagram_host_param = <0xfdfee4>;

		dwc3@ff100000 {
			maximum-speed = "super-speed";
		};
	};

	caf_memory_manager {
		phandle = <0x9f>;
	};

	huawei,hjpeg {
		reg = <0x00 0xe8300000 0x00 0x1000>;
	};

	sensorhub {
		light {
			als1 {
				compatible = "huawei,rohm_bh1745";
				reg = <0x38>;
				chip_id_value = <0x20 0x29 0x30 0x39>;
				file_id = <0x02>;
				poll_interval = <0x1f4>;
			};

			als2 {
				compatible = "huawei,avago_apds9251";
				reg = <0x52>;
			};
		};

		proximity {
			ps1 {
				compatible = "huawei,txc-pa224";
				reg = <0x1e>;
				chip_id_register = <0x92>;
				chip_id_value = <0x20 0x29 0x30 0x39>;
				file_id = <0x02>;
				min_proximity_value = <0x2ee>;
				pwindows_value = <0x6e>;
				pwave_value = <0x50>;
				threshold_value = <0x5a>;
				poll_interval = <0x12c>;
			};

			ps2 {
				compatible = "huawei,avago-apds9110";
				reg = <0x53>;
			};
		};

		gsensor {
			acc1 {
				compatible = "huawei,st-lsm6dsm";
				reg = <0x6a>;
				negate_z = <0x00>;
				gpio_int2 = <0xa2 0x03 0x00>;
			};

			acc2 {
				compatible = "huawei,invensense-icm20690";
				reg = <0x68>;
				status = "ok";
			};
		};

		gyroscope {
			gyro1 {
				compatible = "huawei,st-lsm6dsm";
				reg = <0x6a>;
				axis_map_x = <0x01>;
				axis_map_y = <0x00>;
				negate_z = <0x00>;
				gpio_int2 = <0xa2 0x03 0x00>;
			};

			gyro2 {
				compatible = "huawei,inv-icm20690";
				reg = <0x68>;
				status = "ok";
			};
		};

		compass {
			mag1 {
				compatible = "huawei,akm-akm09911";
				reg = <0x0d>;
				file_id = <0x25>;
				axis_map_x = <0x01>;
				axis_map_y = <0x00>;
				negate_x = <0x01>;
				negate_z = <0x00>;
				gpio_int1 = <0x2e 0x00 0x00>;
				gpio_reset = <0x2e 0x00 0x00>;
				softiron_parameter = <0x10 0x27 0x00 0x00 0x00 0x00 0x00 0x00 0x10 0x27 0x00 0x00 0x00 0x00 0x00 0x00 0x10 0x27 0x00 0x00 0x00 0x00 0x00 0x00 0x00 0x00 0x00>;
				softfilter = <0x02>;
				sensorlist_name = "mag-akm09911";
				vendor = "akm";
				minDelay = <0x2710>;
				fifoReservedEventCount = <0x00>;
				fifoMaxEventCount = <0x00>;
			};

			mag2 {
				compatible = "huawei,yamaha-yas537";
				reg = <0x2e>;
				chip_id_register = <0x80>;
				chip_id_value = <0x07>;
				file_id = <0x42>;
				sensor_list_info_id = <0x01>;
				sensor_type = "mag";
				outbit = <0x00>;
				softfilter = <0x02>;
				calibrate_method = <0x02>;
				axis_map_x = <0x01>;
				axis_map_y = <0x00>;
				axis_map_z = <0x02>;
				negate_x = <0x01>;
				negate_y = <0x00>;
				negate_z = <0x00>;
				poll_interval = <0x0a>;
				gpio_int1 = <0x2e 0x00 0x00>;
				gpio_reset = <0x2e 0x00 0x00>;
				softiron_parameter = <0x10 0x27 0x00 0x00 0x00 0x00 0x00 0x00 0x10 0x27 0x00 0x00 0x00 0x00 0x00 0x00 0x10 0x27 0x00 0x00 0x00 0x00 0x00 0x00 0x00 0x00 0x00>;
				sensorlist_name = "mag-yas537";
				vendor = "yamaha";
				minDelay = <0x2710>;
				fifoReservedEventCount = <0x00>;
				fifoMaxEventCount = <0x00>;
				status = "ok";
			};

			mag3 {
				compatible = "huawei,akm-akm09918";
				reg = <0x0c>;
				chip_id_register = <0x00>;
				chip_id_value = <0x48>;
				file_id = <0x43>;
				sensor_list_info_id = <0x01>;
				sensor_type = "mag";
				outbit = <0x00>;
				calibrate_method = <0x02>;
				axis_map_x = <0x01>;
				axis_map_y = <0x00>;
				axis_map_z = <0x02>;
				negate_x = <0x01>;
				negate_y = <0x00>;
				negate_z = <0x00>;
				poll_interval = <0x0a>;
				gpio_int1 = <0x2e 0x00 0x00>;
				gpio_reset = <0x2e 0x00 0x00>;
				softiron_parameter = <0x10 0x27 0x00 0x00 0x00 0x00 0x00 0x00 0x10 0x27 0x00 0x00 0x00 0x00 0x00 0x00 0x10 0x27 0x00 0x00 0x00 0x00 0x00 0x00 0x00 0x00 0x00>;
				sensorlist_name = "akm-akm09918";
				vendor = "akm";
				minDelay = <0x2710>;
				fifoReservedEventCount = <0x00>;
				fifoMaxEventCount = <0x00>;
				status = "ok";
			};
		};

		airpress {
			airpress1 {
				compatible = "huawei,st_lps22bh";
				reg = <0x5d>;
				status = "ok";
			};

			airpress2 {
				compatible = "huawei,bosch_bmp380";
				reg = <0x77>;
				status = "ok";
			};
		};

		fingerprint {
			finger1 {
				compatible = "goodix,goodix5288";
			};

			finger2 {
				compatible = "fpc,fpc1291";
				status = "ok";
			};
		};

		fingerprint_ud {
			finger1 {
				compatible = "goodix,goodixBaikal";
				status = "ok";
			};

			finger2 {
				compatible = "qfp,qfp1500";
				status = "ok";
			};
		};

		gps_4774_i2c {
			gps_4774_i2c {
				compatible = "huawei,gps_4774_i2c";
				bus_number = <0x00>;
				reg = <0x6e>;
				chip_id_register = <0x91>;
				chip_id_value = <0x00>;
				file_id = <0x2f>;
				sensor_type = "gps_4774_i2c";
				gpio1_gps_cmd_ap = <0xce>;
				gpio1_gps_cmd_sh = <0x3f1>;
				gpio2_gps_ready_ap = <0xdd>;
				gpio2_gps_ready_sh = <0x3ea>;
				gpio3_wakeup_gps_ap = <0xdc>;
				gpio3_wakeup_gps_sh = <0x3f8>;
				status = "ok";
			};
		};

		sar {
			sar1 {
				compatible = "huawei,semtech-sx9323";
				reg = <0x28>;
				status = "disabled";
			};

			sar2 {
				compatible = "huawei,adi-adux1050";
				reg = <0x2c>;
				status = "disabled";
			};
		};
	};

	pcie_kport_rc@0xf4000000 {
		reg = <0x00 0xf4000000 0x00 0x1000000 0x00 0xfc180000 0x00 0x1000 0x00 0xfc000000 0x00 0x80000 0x00 0xf4000000 0x00 0x2000>;
		status = "ok";
	};

	pcie_kport_rc@0xf8000000 {
		reset-gpio = <0x34 0x07 0x00>;
	};

	pcie_kport_ep@0xf4000000 {
		reg = <0x00 0xf4000000 0x00 0x1000000 0x00 0xfc180000 0x00 0x1000 0x00 0xfc000000 0x00 0x80000 0x00 0xf4000000 0x00 0x2000>;
	};

	pcie_kport_ep@0xf8000000 {
		reset-gpio = <0x34 0x07 0x00>;
	};

	huawei_ptst {
		compatible = "huawei,power_test";
		dc_mmi = <0x01>;
		status = "ok";
	};

	direct_charge_ps {
		boost_5v_support_scp_power = <0x00>;
		status = "disabled";
	};

	huawei_charger {
		pd_support = <0x00>;
		support_usb_nonstandard_ico = <0x00>;
		fcp_vindpm = <0x11f8>;
	};

	power_thermalzone {
		status = "ok";
	};

	wired_channel_switch {
		use_ovp_cutoff_wired_channel = <0x01>;
		use_super_switch_cutoff_wired_channel = <0x00>;
		status = "disabled";
	};

	ovp_channel_switch {
		status = "disabled";
	};

	vbat_ovp {
		status = "ok";
	};

	direct_charger {
		compensate_r = <0x00>;
		use_5A = <0x00>;
		scp_work_on_charger = <0x00>;
		full_path_res_max = <0x78>;
		standard_cable_full_path_res_max = <0xa0>;
		temp_para = "-32767", "10", "0", "10", "45", "4750", "45", "32767", "0";
		status = "ok";
	};

	charging_core {
		ichg_ac = <0x76c>;
		iin_usb = <0x1f4>;
		iterm = <0x64>;
		inductance_para = "-32767", "15", "1600", "0", "15", "32767", "1700", "0";
	};

	coul_core {
		startup_delta_soc = <0x0a>;
	};

	fastboot_charger {
		fastboot_single_phase_buck = <0x00>;
	};

	usb_short_circuit_protect {
		gpio_usb_short_circuit_protect = <0x2e 0x03 0x00>;
		open_mosfet_temp = <0x0a>;
		close_mosfet_temp = <0x09>;
		interval_switch_temp = <0x07>;
		status = "ok";
	};

	desayatl_3900_39k_4384 {
		fcc = <0xf3c>;
		default_rbatt_mohm = <0x64>;
		identify_type = "id_volt";
		id_identify_min = <0x4d3>;
		id_identify_max = <0x6df>;
		id_voltage_min = <0x58c>;
		id_voltage_max = <0x61a>;
		vbat_max = <0x1120>;
		temp_para = "-32767", "0", "-1", "0", "4100", "0", "0", "5", "-1", "390", "4384", "0", "5", "10", "-1", "1170", "4384", "3", "10", "45", "-1", "-1", "4384", "3", "45", "50", "-1", "1365", "4100", "3", "50", "32767", "-1", "0", "4100", "0";
		vbat_para = "-32767", "3400", "-1", "820", "0", "3400", "32767", "-1", "-1", "0";
		segment_para = "-32767", "4150", "3900", "4208", "50", "4150", "4450", "2730", "4384", "0";
		batt_brand = "desayatl";
		fcc_temp = <0xf1e 0xf20 0xf2a 0xf3c 0xf37 0xf1a>;
		fcc_sf_x = <0x00 0x64 0xc8 0x12c 0x190 0x1f4 0x258 0x2bc 0x320 0x3e8 0x5dc>;
		fcc_sf_y = <0x64 0x60 0x5e 0x5c 0x5a 0x58 0x57 0x54 0x51 0x4b 0x32>;
		fcc_sf_cols = <0x0b>;
		pc_sf_rows = <0x01>;
		pc_sf_cols = <0x01>;
		pc_sf_row_entries = <0x00>;
		pc_sf_percent = <0x64>;
		pc_sf_sf = <0x64>;
		rbatt_sf_rows = <0x1c>;
		rbatt_sf_cols = <0x06>;
		rbatt_sf_percent = <0x64 0x5f 0x5a 0x55 0x50 0x4b 0x46 0x41 0x3c 0x37 0x32 0x2d 0x28 0x23 0x1e 0x19 0x14 0x0f 0x0a 0x09 0x08 0x07 0x06 0x05 0x04 0x03 0x02 0x01>;
		rbatt_sf_sf = <0x6cd 0x3fd 0x193 0x76 0x62 0x5b 0x6cd 0x3fd 0x193 0x76 0x62 0x5b 0x647 0x3e6 0x193 0x77 0x63 0x5b 0x5df 0x3c8 0x192 0x79 0x64 0x5c 0x5ba 0x3bb 0x190 0x7d 0x67 0x5d 0x547 0x3aa 0x1bb 0x82 0x6a 0x5f 0x50b 0x356 0x196 0x8a 0x6f 0x62 0x4f9 0x353 0x18b 0x93 0x75 0x65 0x4e8 0x341 0x176 0x97 0x7f 0x6c 0x4db 0x332 0x164 0x77 0x65 0x5e 0x4ec 0x33e 0x162 0x74 0x62 0x5c 0x50c 0x35e 0x164 0x76 0x63 0x5c 0x531 0x387 0x175 0x7a 0x67 0x5f 0x562 0x3b2 0x193 0x7f 0x6b 0x63 0x59f 0x3e8 0x1be 0x80 0x6d 0x60 0x5e5 0x42b 0x1eb 0x78 0x64 0x5d 0x641 0x47c 0x224 0x79 0x64 0x5f 0x6bb 0x4da 0x26e 0x7b 0x65 0x5f 0x774 0x55d 0x2eb 0x7f 0x66 0x60 0x85e 0x51c 0x26a 0x81 0x6b 0x62 0xa30 0x4d5 0x238 0x82 0x6a 0x66 0xb3f 0x558 0x271 0x80 0x6a 0x64 0xc40 0x603 0x2bb 0x7f 0x68 0x62 0xd36 0x697 0x302 0x7c 0x66 0x5e 0xe37 0x6e8 0x332 0x7f 0x66 0x5f 0xf50 0x795 0x38a 0x83 0x68 0x61 0x10c0 0x895 0x40a 0x8b 0x6c 0x61 0x131d 0xa36 0x4cd 0x14a 0x80 0x68>;
		pc_temp_ocv_rows = <0x1d>;
		pc_temp_ocv_cols = <0x06>;
		pc_temp_ocv_percent = <0x64 0x5f 0x5a 0x55 0x50 0x4b 0x46 0x41 0x3c 0x37 0x32 0x2d 0x28 0x23 0x1e 0x19 0x14 0x0f 0x0a 0x09 0x08 0x07 0x06 0x05 0x04 0x03 0x02 0x01>;
		pc_temp_ocv_ocv = <0x1104 0x1102 0x1100 0x10fb 0x10f5 0x10f0 0x10a4 0x10ae 0x10b7 0x10bf 0x10ba 0x10b6 0x105f 0x106c 0x107b 0x1087 0x1082 0x107e 0x1024 0x1033 0x1043 0x1050 0x104b 0x1047 0xffb 0x1003 0x100f 0x101b 0x1016 0x1013 0xfb0 0xfce 0xfe6 0xfe9 0xfe4 0xfe1 0xf76 0xf87 0xfa3 0xfb8 0xfb5 0xfb4 0xf4d 0xf5d 0xf75 0xf8b 0xf8b 0xf8a 0xf28 0xf32 0xf48 0xf60 0xf62 0xf61 0xf08 0xf0c 0xf1e 0xf2b 0xf2b 0xf2c 0xef2 0xef3 0xefe 0xf0c 0xf0c 0xf0c 0xee3 0xee3 0xee6 0xef4 0xef4 0xef4 0xed6 0xed8 0xed6 0xee0 0xee0 0xee0 0xec9 0xecf 0xecc 0xecf 0xed0 0xecf 0xebd 0xec5 0xec4 0xebf 0xebf 0xeb8 0xeae 0xeb9 0xeb9 0xeac 0xea6 0xe9c 0xe9e 0xea6 0xea7 0xe99 0xe92 0xe87 0xe8d 0xe8b 0xe8a 0xe7d 0xe78 0xe6b 0xe78 0xe76 0xe70 0xe68 0xe61 0xe57 0xe72 0xe71 0xe6b 0xe67 0xe60 0xe54 0xe6a 0xe6c 0xe66 0xe64 0xe5e 0xe53 0xe61 0xe66 0xe62 0xe61 0xe5b 0xe4f 0xe54 0xe5f 0xe5b 0xe56 0xe54 0xe46 0xe40 0xe4f 0xe4a 0xe3a 0xe3d 0xe2e 0xe20 0xe2d 0xe28 0xe0e 0xe15 0xe06 0xdf0 0xdfb 0xdf5 0xdd3 0xde0 0xdd3 0xdab 0xdb6 0xdaf 0xd84 0xd9a 0xd90 0xd46 0xd50 0xd4a 0xd12 0xd36 0xd2f 0xc80 0xc80 0xc80 0xc80 0xc80 0xc80>;
	};

	scudlg_3900_200k_4384_25 {
		fcc = <0xf3c>;
		default_rbatt_mohm = <0x64>;
		identify_type = "id_volt";
		id_identify_min = <0xae2>;
		id_identify_max = <0xcf0>;
		id_voltage_min = <0xb7d>;
		id_voltage_max = <0xc5f>;
		vbat_max = <0x1120>;
		temp_para = "-32767", "0", "-1", "0", "4100", "0", "0", "5", "-1", "390", "4384", "0", "5", "10", "-1", "1170", "4384", "3", "10", "45", "-1", "-1", "4384", "3", "45", "50", "-1", "1365", "4100", "3", "50", "32767", "-1", "0", "4100", "0";
		vbat_para = "-32767", "3400", "-1", "820", "0", "3400", "32767", "-1", "-1", "0";
		segment_para = "-32767", "4150", "3900", "4208", "50", "4150", "4450", "2730", "4384", "0";
		batt_brand = "scudlg";
		fcc_temp = <0xf31 0xf2b 0xf36 0xf50 0xf1a 0xefe>;
		fcc_sf_x = <0x00 0x64 0xc8 0x12c 0x190 0x1f4 0x258 0x2bc 0x320 0x3e8 0x5dc>;
		fcc_sf_y = <0x64 0x60 0x5e 0x5c 0x5a 0x58 0x57 0x54 0x51 0x4b 0x32>;
		fcc_sf_cols = <0x0b>;
		pc_sf_rows = <0x01>;
		pc_sf_cols = <0x01>;
		pc_sf_row_entries = <0x00>;
		pc_sf_percent = <0x64>;
		pc_sf_sf = <0x64>;
		rbatt_sf_rows = <0x1c>;
		rbatt_sf_cols = <0x06>;
		rbatt_sf_percent = <0x64 0x5f 0x5a 0x55 0x50 0x4b 0x46 0x41 0x3c 0x37 0x32 0x2d 0x28 0x23 0x1e 0x19 0x14 0x0f 0x0a 0x09 0x08 0x07 0x06 0x05 0x04 0x03 0x02 0x01>;
		rbatt_sf_sf = <0x690 0x31a 0x149 0x5c 0x47 0x3c 0x66b 0x31a 0x14b 0x5d 0x47 0x3c 0x5e1 0x319 0x154 0x60 0x48 0x3d 0x58b 0x318 0x159 0x63 0x4a 0x3e 0x563 0x31d 0x16a 0x69 0x4e 0x40 0x4f0 0x2fd 0x17a 0x70 0x53 0x42 0x4d2 0x2bb 0x152 0x78 0x55 0x44 0x4d4 0x2c7 0x14a 0x83 0x5c 0x49 0x4c8 0x2bb 0x13e 0x77 0x5d 0x49 0x4c2 0x2b0 0x134 0x60 0x4b 0x3f 0x4de 0x2b3 0x131 0x5b 0x46 0x3d 0x510 0x2c8 0x131 0x5e 0x48 0x3e 0x551 0x2ed 0x135 0x61 0x4b 0x41 0x5a3 0x31e 0x143 0x64 0x4e 0x43 0x607 0x362 0x15c 0x62 0x4d 0x42 0x67a 0x3c2 0x17b 0x60 0x46 0x3d 0x708 0x455 0x1a8 0x60 0x47 0x3d 0x7c5 0x52d 0x1f7 0x5f 0x48 0x3e 0xa3c 0x460 0x1a8 0x61 0x49 0x40 0xc43 0x4d1 0x1c5 0x60 0x49 0x40 0xe85 0x581 0x1f9 0x63 0x49 0x3f 0x10fd 0x681 0x23a 0x65 0x4a 0x40 0x13d6 0x748 0x281 0x66 0x4c 0x3f 0x16d5 0x8a4 0x2e3 0x68 0x47 0x3f 0x19bc 0xa5d 0x345 0x74 0x49 0x41 0x1caa 0xca1 0x3da 0x15e 0x51 0x45 0x1f7f 0xfe3 0x573 0x25c 0x74 0x45 0x2472 0x13e7 0x785 0x2be 0x11d 0x97>;
		pc_temp_ocv_rows = <0x1d>;
		pc_temp_ocv_cols = <0x06>;
		pc_temp_ocv_percent = <0x64 0x5f 0x5a 0x55 0x50 0x4b 0x46 0x41 0x3c 0x37 0x32 0x2d 0x28 0x23 0x1e 0x19 0x14 0x0f 0x0a 0x09 0x08 0x07 0x06 0x05 0x04 0x03 0x02 0x01>;
		pc_temp_ocv_ocv = <0x10e3 0x10e2 0x10e0 0x10e0 0x10d1 0x10ca 0x1089 0x1094 0x1099 0x10a1 0x1093 0x108e 0x1048 0x1058 0x1060 0x1069 0x105b 0x1056 0x1010 0x1022 0x102a 0x1032 0x1026 0x1021 0xfdf 0xfee 0xff9 0x1002 0xff4 0xfee 0xf8c 0xfae 0xfc3 0xfcd 0xfc4 0xfbf 0xf56 0xf68 0xf7b 0xf98 0xf94 0xf93 0xf34 0xf48 0xf57 0xf73 0xf6f 0xf6c 0xf11 0xf24 0xf32 0xf46 0xf44 0xf43 0xef2 0xf01 0xf10 0xf19 0xf17 0xf15 0xede 0xee6 0xef4 0xefc 0xefa 0xef8 0xed1 0xed5 0xede 0xee6 0xee4 0xee3 0xec5 0xeca 0xecd 0xed5 0xed4 0xed1 0xebb 0xec0 0xec3 0xec6 0xec5 0xec3 0xeb0 0xeb7 0xebb 0xeb9 0xeb6 0xeb1 0xea4 0xeab 0xeb0 0xeaa 0xea3 0xe96 0xe97 0xe9d 0xea0 0xe97 0xe90 0xe82 0xe85 0xe8c 0xe89 0xe7b 0xe77 0xe6a 0xe6b 0xe77 0xe70 0xe69 0xe61 0xe55 0xe63 0xe70 0xe6d 0xe67 0xe60 0xe54 0xe59 0xe69 0xe69 0xe64 0xe5e 0xe52 0xe4c 0xe64 0xe64 0xe5f 0xe5b 0xe4f 0xe3d 0xe59 0xe5a 0xe50 0xe53 0xe47 0xe2a 0xe48 0xe48 0xe2e 0xe3e 0xe30 0xe0b 0xe2b 0xe25 0xdfd 0xe16 0xe0a 0xde0 0xdfc 0xded 0xdcc 0xde0 0xdd9 0xda4 0xdbb 0xda2 0xd95 0xd99 0xd95 0xd4b 0xd57 0xd1f 0xd35 0xd36 0xd36 0xc80 0xc80 0xc80 0xc80 0xc80 0xc80>;
	};

	sunwodasony_3900_110k_4384_15 {
		fcc = <0xf3c>;
		default_rbatt_mohm = <0x64>;
		identify_type = "id_volt";
		id_identify_min = <0x8e9>;
		id_identify_max = <0xae2>;
		id_voltage_min = <0x97a>;
		id_voltage_max = <0xa47>;
		vbat_max = <0x1120>;
		temp_para = "-32767", "0", "-1", "0", "4100", "0", "0", "5", "-1", "390", "4384", "0", "5", "10", "-1", "1170", "4384", "3", "10", "45", "-1", "-1", "4384", "3", "45", "50", "-1", "1365", "4100", "3", "50", "32767", "-1", "0", "4100", "0";
		vbat_para = "-32767", "3400", "-1", "820", "0", "3400", "32767", "-1", "-1", "0";
		segment_para = "-32767", "4150", "3900", "4208", "50", "4150", "4450", "2730", "4384", "0";
		batt_brand = "sunwodasony";
		fcc_temp = <0xef2 0xeff 0xf0b 0xf37 0xf1f 0xf0e>;
		fcc_sf_x = <0x00 0x64 0xc8 0x12c 0x190 0x1f4 0x258 0x2bc 0x320 0x3e8 0x5dc>;
		fcc_sf_y = <0x64 0x60 0x5e 0x5c 0x5a 0x58 0x57 0x54 0x51 0x4b 0x32>;
		fcc_sf_cols = <0x0b>;
		pc_sf_rows = <0x01>;
		pc_sf_cols = <0x01>;
		pc_sf_row_entries = <0x00>;
		pc_sf_percent = <0x64>;
		pc_sf_sf = <0x64>;
		rbatt_sf_rows = <0x1c>;
		rbatt_sf_cols = <0x06>;
		rbatt_sf_percent = <0x64 0x5f 0x5a 0x55 0x50 0x4b 0x46 0x41 0x3c 0x37 0x32 0x2d 0x28 0x23 0x1e 0x19 0x14 0x0f 0x0a 0x09 0x08 0x07 0x06 0x05 0x04 0x03 0x02 0x01>;
		rbatt_sf_sf = <0x54a 0x2a1 0x14b 0x7e 0x64 0x5a 0x549 0x2a4 0x14d 0x7e 0x64 0x5a 0x53d 0x2b1 0x157 0x82 0x66 0x5a 0x522 0x2b5 0x15f 0x86 0x69 0x5b 0x527 0x2b2 0x165 0x8b 0x6b 0x5d 0x510 0x2c0 0x170 0x92 0x6f 0x5f 0x4f2 0x2a3 0x166 0x99 0x74 0x62 0x4f2 0x2ab 0x15c 0x9c 0x78 0x66 0x4f5 0x2ae 0x153 0x90 0x75 0x66 0x4f0 0x2ae 0x14e 0x81 0x67 0x5b 0x506 0x2b9 0x150 0x80 0x64 0x5a 0x532 0x2d1 0x156 0x82 0x65 0x5a 0x560 0x2f9 0x160 0x87 0x69 0x5c 0x59e 0x322 0x170 0x8c 0x6c 0x5f 0x5ee 0x355 0x190 0x8c 0x6d 0x5d 0x64c 0x38d 0x1a6 0x88 0x67 0x5b 0x6da 0x3e3 0x1c7 0x88 0x68 0x5e 0x7d5 0x492 0x1fb 0x88 0x69 0x5e 0xc8a 0x668 0x292 0x8d 0x6a 0x5f 0xddc 0x619 0x221 0x8e 0x6a 0x5f 0x1051 0x630 0x215 0x8e 0x6a 0x60 0x14b9 0x713 0x257 0x90 0x6c 0x61 0x1b37 0x8e5 0x2b4 0x92 0x6c 0x60 0x261d 0xb23 0x32a 0x92 0x6b 0x5e 0x4090 0xe9b 0x3a3 0x95 0x6c 0x60 0x75a8 0x15be 0x4a9 0x9b 0x6f 0x61 0xcc0d 0x28cf 0x657 0xe4 0x75 0x66 0x12974 0x568e 0xa2f 0x25e 0xc1 0x89>;
		pc_temp_ocv_rows = <0x1d>;
		pc_temp_ocv_cols = <0x06>;
		pc_temp_ocv_percent = <0x64 0x5f 0x5a 0x55 0x50 0x4b 0x46 0x41 0x3c 0x37 0x32 0x2d 0x28 0x23 0x1e 0x19 0x14 0x0f 0x0a 0x09 0x08 0x07 0x06 0x05 0x04 0x03 0x02 0x01>;
		pc_temp_ocv_ocv = <0x10f3 0x10f2 0x10ef 0x10eb 0x10e2 0x10dc 0x109b 0x10a6 0x10aa 0x10ad 0x10a4 0x109f 0x1055 0x1067 0x106e 0x1072 0x106a 0x1065 0x1013 0x102c 0x1033 0x1039 0x1032 0x102e 0xfe2 0xff2 0xffc 0x1003 0xffd 0xff9 0xfaa 0xfc0 0xfca 0xfd1 0xfcc 0xfc8 0xf6f 0xf85 0xf95 0xfa2 0xf9f 0xf9c 0xf41 0xf56 0xf64 0xf74 0xf73 0xf71 0xf1a 0xf2c 0xf39 0xf45 0xf47 0xf45 0xef4 0xf06 0xf13 0xf1c 0xf1c 0xf19 0xed7 0xee7 0xef5 0xeff 0xefe 0xefc 0xec0 0xecf 0xedd 0xee8 0xee8 0xee5 0xeab 0xebe 0xec9 0xed5 0xed5 0xed3 0xe98 0xeae 0xeb9 0xec5 0xec5 0xec2 0xe88 0xea0 0xeae 0xeb4 0xeb4 0xeac 0xe75 0xe8d 0xe9e 0xea1 0xe9c 0xe8f 0xe63 0xe74 0xe88 0xe8b 0xe87 0xe7a 0xe4c 0xe54 0xe66 0xe6d 0xe6a 0xe5e 0xe27 0xe31 0xe3b 0xe4f 0xe4c 0xe41 0xe1e 0xe2a 0xe36 0xe4a 0xe47 0xe3d 0xe0e 0xe1e 0xe2d 0xe43 0xe42 0xe38 0xdfb 0xe10 0xe25 0xe3b 0xe3b 0xe31 0xde5 0xe02 0xe1a 0xe2c 0xe2e 0xe23 0xdca 0xdef 0xe09 0xe0e 0xe13 0xe06 0xda9 0xdcc 0xde8 0xddf 0xdea 0xddb 0xd7d 0xd96 0xdb3 0xda4 0xdb3 0xda7 0xd42 0xd4a 0xd6a 0xd59 0xd6d 0xd63 0xcf2 0xced 0xd02 0xd05 0xd0f 0xd07 0xc80 0xc80 0xc80 0xc80 0xc80 0xc80>;
	};

	hisi_tm@1 {
		hisi,peripheral_sensors = <0x0d>;
		hisi,detect_flash_led_tm_chanel = <0x0d>;
		hisi,detect_flash_led_tm_state = "enable";
	};

	shell_frame@0 {
		bias = <0x00>;
		count = <0x08>;

		sensors {
			sensor0 {
				type = "Battery";
				coef = "0", "0", "0", "0", "0", "0", "0", "0";
			};

			sensor1 {
				type = "system_h";
				coef = "0", "0", "0", "0", "0", "0", "0", "0";
			};

			sensor2 {
				type = "charger";
				coef = "0", "0", "0", "0", "0", "0", "0", "0";
			};

			sensor3 {
				type = "pa_0";
				coef = "0", "0", "0", "0", "0", "0", "0", "0";
			};
		};
	};

	ipa-sensor@1 {
		phandle = <0x9b>;
	};

	test_regu_ip@0xFFF35000 {
		g3dtest-supply = <0x9e>;
	};

	hisi_dp {
		preemphasis_swing = <0x3c0 0x9788 0x2040 0xa188 0x2640 0xa598 0x2c40 0xa1f8 0x3040 0xa388 0x2040 0xa9a0 0x2840 0xa5f8 0x2c40 0xafa0 0x2040 0xa9f8 0x2840 0xb1f8 0x2040>;
		status = "ok";
	};

	audio_hw_config {
		product_name = "NEO";
		cust_name = "audio_custom";
		spk_pa_name = "smartpakit";
		codec_name = "DA_combine_v3";
		codec_dsp_algo = "mad";
		ear_pa_name = "smartpakit";
		multi_mic_enable = "true";
		vqm_enable = "true";
		audio_sar_support = "false";
		speaker_test_content = "speaker";
		analog_earpiece_enable = "false";

		smartpa_info {
			pa_num = "1";
			pa_type = "0001";
		};

		hardware_info {
			mic_num = "3";
			mic_type = "000b";
		};

		audio_capability {
			bwe_ui_support = "true";
			wnr_support = "false";
			lvm_support = "false";
			dhf_support = "true";
			dual_smartpa_support = "true";
			dual_smartpa_version = "2.0";
			spk_rcv_stereo_support = "true";
			asr_vibrate_support = "true";
			swb_support = "true";
			nv_evs_support = "true";
			earphone_multi_eq_support = "true";
			vdr_ui_support = "false";
			mmi_capture_enable = "true";
			irda_support = "true";
			visualizer_support = "true";
			visualizer_frame = "Medium";
			soundtrigger_version = "2.0";
			soundtrigger_enhance_enable = "false";
			soundtrigger_mic_info = "1";
			max_stream_volume = "15";
		};

		hifi_info {
			dsp_voice_vol_control = "1";
		};
	};

	deviceboxID@0 {
		status = "ok";
		check_mode = "gpio";
		box_num = <0x01>;
		enable_boxID = <0x01 0x00 0x00 0x00>;
		gpio_num = <0x01 0x00 0x00 0x00>;
		gpio_speakerID = <0x35 0x00 0x00>;
		speaker_map = <0x01 0x02>;
		pinctrl-names = "default", "idle";
		deviceboxID_limit = <0x1f4>;
	};

	smartpakit {
		status = "disabled";
	};

	invert_hs@0 {
		gpio_type = <0x00>;
		status = "disabled";
		gpios = <0x2b 0x00 0x00>;
		pinctrl-names = "default", "idle";
	};

	extern_dac_vir_dai@0 {
		status = "disabled";
	};

	gps_power {
		huawei,gps_hostwake = <0x2b 0x02 0x00>;
		pinctrl-0;
		pinctrl-1;
		huawei,gps_refclk = <0x61>;
		status = "ok";
	};

	peripherals {
		dma@fdf30000 {
			phandle = <0x37>;
		};
	};

	devcheck {
		touch_panel = <0x00>;
		compass = <0x00>;
		g_sensor = <0x00>;
		gyroscope = <0x00>;
		nfc = <0x00>;
		dc_dc = <0x00>;
		tps = <0x00>;
		l_sensor = <0x00>;
		charge = <0x00>;
		usb_switch = <0x00>;
		airpress = <0x00>;
		vibrator_lra = <0x00>;
		laser = <0x00>;
		charge_loadswitch = <0x00>;
	};

	hall {
		status = "ok";

		huawei,hall_0 {
			huawei,type = <0x03>;
			huawei,default-state = "off";
		};
	};

	irda_maxim {
		status = "ok";
	};

	pd_dpm {
		switch_manual_enable = <0x01>;
		support_dp = <0x01>;
		abnormal_cc_detection = <0x00>;
	};

	huawei_usb {
		maximum-speed = "unknown-speed";
	};

	huawei_usbvbus {
		support_pd = <0x00>;
		support_dp = <0x01>;
	};

	bluetooth_power {
		huawei,bt_en = <0x6f>;
		status = "ok";
	};

	bluetooth_sleep {
		huawei,bt_wake_host = <0xd5>;
		huawei,host_wake_bt = <0x48>;
		status = "ok";
	};

	lcdkit_neo_tugl_auo_otm1901a_5p2_1080p_video_default {
		compatible = "auo_otm1901a_5p2_1080p_video_default";
		hw,lcdkit-panel-name = "unknown_OTM1901A 5.2' VIDEO TFT 1080 x 1920 DEFAULT";
		hw,lcdkit-panel-type = <0x01>;
		hw,lcdkit-panel-xres = <0x438>;
		hw,lcdkit-panel-yres = <0x780>;
		hw,lcdkit-panel-width = <0x4b>;
		hw,lcdkit-panel-height = <0x85>;
		hw,lcdkit-panel-on-command = <0x29 0x01 0x00 0x00 0x0a 0x00 0x02 0x00 0x00 0x29 0x01 0x00 0x00 0x0a 0x00 0x04 0xff 0x19 0x01 0x01 0x29 0x01 0x00 0x00 0x0a 0x00 0x02 0x00 0x80 0x29 0x01 0x00 0x00 0x0a 0x00 0x03 0xff 0x19 0x01 0x29 0x01 0x00 0x00 0x0a 0x00 0x02 0x00 0x88 0x29 0x01 0x00 0x00 0x0a 0x00 0x02 0xf3 0x00 0x29 0x01 0x00 0x00 0x0a 0x00 0x02 0x00 0xb0 0x29 0x01 0x00 0x00 0x0a 0x00 0x02 0xca 0x01 0x29 0x01 0x00 0x00 0x0a 0x00 0x02 0x00 0xb1 0x29 0x01 0x00 0x00 0x0a 0x00 0x02 0xca 0x01 0x29 0x01 0x00 0x00 0x0a 0x00 0x02 0x00 0xb3 0x29 0x01 0x00 0x00 0x0a 0x00 0x02 0xca 0x40 0x29 0x01 0x00 0x00 0x0a 0x00 0x02 0x00 0x00 0x29 0x01 0x00 0x00 0x0a 0x00 0x04 0xff 0xff 0xff 0xff 0x15 0x01 0x00 0x00 0x0a 0x00 0x02 0x35 0x01 0x15 0x01 0x00 0x00 0x0a 0x00 0x02 0x53 0x24 0x15 0x01 0x00 0x00 0x0a 0x00 0x02 0x55 0x00 0x15 0x01 0x00 0x00 0x0a 0x00 0x02 0x5e 0x28 0x05 0x01 0x00 0x00 0x78 0x01 0x02 0x11 0x00 0x05 0x01 0x00 0x00 0x64 0x01 0x02 0x29 0x00>;
		hw,lcdkit-panel-display-on-command = <0x05 0x01 0x00 0x00 0x78 0x01 0x02 0x29 0x00>;
		hw,lcdkit-panel-off-command = <0x05 0x01 0x00 0x00 0x3c 0x01 0x02 0x28 0x00 0x05 0x01 0x00 0x00 0x78 0x01 0x02 0x10 0x00>;
		hw,lcdkit-panel-backlight-command = <0x15 0x01 0x00 0x00 0x00 0x00 0x02 0x51 0x00>;
		hw,lcdkit-panel-cabc-support = <0x00>;
		hw,lcdkit-panel-rgbw-support = <0x00>;
		hw,lcdkit-panel-display-on-effect-command = <0x15 0x01 0x00 0x00 0x0a 0x00 0x02 0x55 0x81>;
		hw,lcdkit-panel-display-on-effect-support = <0x00>;
		hw,lcdkit-panel-ce-support = <0x00>;
		hw,lcdkit-panel-version-support = <0x00>;
		hw,lcdkit-panel-otp-support = <0x00>;
		hw,lcdkit-panel-inversion-support = <0x00>;
		hw,lcdkit-panel-scan-support = <0x00>;
		hw,lcdkit-panel-display-region-support = <0x00>;
		hw,lcdkit-panel-checksum-support = <0x00>;
		hw,lcdkit-panel-esd-support = <0x00>;
		hw,lcdkit-panel-check-reg-support = <0x00>;
		hw,lcdkit-panel-brightness-color-uniform-support = <0x00>;
		hw,lcdkit-panel-dynamic-gamma-support = <0x00>;
		hw,lcdkit-panel-mipi-detect-support = <0x00>;
		hw,lcdkit-panel-dynamic-sram-check-support = <0x00>;
		hw,lcdkit-panel-fps-updt-support = <0x00>;
		hw,lcdkit-panel-fps-func-switch = <0x00>;
		hw,lcdkit-panel-check-reg-on-support = <0x00>;
		hw,lcdkit-panel-fps-tscall-support = <0x00>;
		hw,lcdkit-panel-dis-on-cmds-delay-margin-support = <0x00>;
		hw,lcdkit-panel-snd-cmd-before-frame-support = <0x00>;
		hw,lcdkit-panel-ts-resume-ctrl-mode = <0x00>;
		hw,lcdkit-panel-dis-on-cmds-delay-margin-time = <0x00>;
		hw,lcdkit-panel-lptohs-mipi-check-support = <0x00>;
		hw,lcdkit-panel-acl-ctrl-support = <0x00>;
		hw,lcdkit-panel-hbm-ctrl-support = <0x00>;
		hw,lcdkit-panel-vr-support = <0x00>;
		hw,lcdkit-panel-current-detect-support = <0x00>;
		hw,lcdkit-panel-lv-detect-support = <0x00>;
		hw,lcdkit-reset-shutdown-later = <0x01>;
		hw,lcdkit-panel-pcd-errflag-check-support = <0x00>;
		hw,lcdkit-panel-pt-ulps-support = <0x00>;
		hw,lcdkit-panel-aod-support = <0x00>;
		hw,lcdkit-panel-orientation = <0x01>;
		hw,lcdkit-panel-bpp = <0x00>;
		hw,lcdkit-panel-bgrfmt = <0x00>;
		hw,lcdkit-panel-bl-type = <0x04>;
		hw,lcdkit-panel-blmin = <0x21>;
		hw,lcdkit-panel-blmax = <0x2274>;
		hw,lcdkit-mask-delay-time-before-fp = <0x411a>;
		hw,lcdkit-mask-delay-time-after-fp = <0x411a>;
		hw,lcdkit-tp-reset-gpio = <0x00>;
		hw,lcdkit-panel-bl-def = <0xfa0>;
		hw,lcdkit-panel-bl-maxnit = <0x212>;
		hw,lcdkit-panel-getblmaxnit-type = <0x00>;
		hw,lcdkit-panel-cmd-type = <0x10>;
		hw,lcdkit-panel-ifbctype = <0x09>;
		hw,lcdkit-panel-ifbc-vesa3x-set = <0x00>;
		hw,lcdkit-panel-frc-enable = <0x00>;
		hw,lcdkit-panel-esd-skip-mipi-check = <0x01>;
		hw,lcdkit-panel-pxl-clk = <0x115>;
		hw,lcdkit-panel-pxl-clk-div = <0x03>;
		hw,lcdkit-panel-tp-resume-nosync = <0x00>;
		hw,lcdkit-panel-display-on-in-backlight = <0x00>;
		hw,lcdkit-panel-display-on-new-seq = <0x00>;
		hw,lcdkit-panel-dirt-updt-support = <0x00>;
		hw,lcdkit-is-hostprocessing = <0x00>;
		hw,lcdkit-host-info-all-in-ddic = <0x01>;
		hw,lcdkit-panel-dsi-upt-support = <0x00>;
		hw,mipiclk-updt-support-new = <0x00>;
		hw,lcdkit-panel-vsyn-ctr-type = <0x00>;
		hw,lcdkit-panel-bl-pwm-preci-no-convert = <0x00>;
		hw,lcdkit-panel-bl-pwm-preci-type = <0x02>;
		hw,lcdkit-panel-bl-ic-ctrl-type = <0x01>;
		hw,lcdkit-panel-fps-updt-only = <0x00>;
		hw,lcdkit-panel-step-support = <0x01>;
		hw,lcdkit-ldi-hsync-plr = <0x00>;
		hw,lcdkit-ldi-vsync-plr = <0x00>;
		hw,lcdkit-ldi-pixel-clk-plr = <0x00>;
		hw,lcdkit-ldi-data-en-plr = <0x00>;
		hw,lcdkit-ldi-dpi-a-overlap-size = <0x00>;
		hw,lcdkit-ldi-dpi-b-overlap-size = <0x00>;
		hw,lcdkit-sbl-stren-limit = <0x80>;
		hw,lcdkit-sbl-cal-a = <0x3c>;
		hw,lcdkit-sbl-cal-b = <0x5f>;
		hw,lcdkit-sbl-cal-c = <0x05>;
		hw,lcdkit-sbl-cal-d = <0x01>;
		hw,lcdkit-sbl-tf-ctl = <0x05>;
		hw,lcdkit-sbl-bl-min = <0x1e0>;
		hw,lcdkit-sbl-bl-max = <0x1000>;
		hw,lcdkit-sbl-bl-scale = <0xff>;
		hw,lcdkit-sbl-am-light-min = <0x0e>;
		hw,lcdkit-sbl-filter-a = <0x6ca>;
		hw,lcdkit-sbl-filter-b = <0x06>;
		hw,lcdkit-sbl-logo-left = <0x00>;
		hw,lcdkit-sbl-logo-top = <0x00>;
		hw,lcdkit-sbl-variance-intensity-space = <0x91>;
		hw,lcdkit-sbl-slope-max = <0x36>;
		hw,lcdkit-sbl-slope-min = <0xa0>;
		hw,lcdkit-mipi-lane-nums = <0x00>;
		hw,lcdkit-mipi-color-mode = <0x05>;
		hw,lcdkit-mipi-vc = <0x00>;
		hw,lcdkit-mipi-dsi-bit-clk = <0x3e8>;
		hw,lcdkit-mipi-burst-mode = <0x02>;
		hw,lcdkit-mipi-max-esc-clk = <0x0a>;
		hw,lcdkit-mipi-dsi-bit-clk-val-a = <0x1d7>;
		hw,lcdkit-mipi-dsi-bit-clk-val-b = <0x1f4>;
		hw,lcdkit-mipi-dsi-bit-clk-val-c = <0x1ea>;
		hw,lcdkit-mipi-dsi-bit-clk-val-d = <0x1f4>;
		hw,lcdkit-mipi-dsi-bit-clk-val-e = <0x00>;
		hw,lcdkit-mipi-dsi-bit-clk-upt = <0x3e8>;
		hw,lcdkit-mipi-rg-vcm-adjust = <0x00>;
		hw,lcdkit-mipi-non-continue-enable = <0x01>;
		hw,lcdkit-mipi-clk-post-adjust = <0xd7>;
		hw,lcdkit-mipi-clk-pre-adjust = <0x00>;
		hw,lcdkit-mipi-clk-t-hs-prepare-adjust = <0x00>;
		hw,lcdkit-mipi-clk-t-lpx-adjust = <0x00>;
		hw,lcdkit-mipi-clk-t-hs-trail-adjust = <0x00>;
		hw,lcdkit-mipi-clk-t-hs-exit-adjust = <0x00>;
		hw,lcdkit-mipi-clk-t-hs-zero-adjust = <0x00>;
		hw,lcdkit-mipi-data-t-lpx-adjust = <0x00>;
		hw,lcdkit-mipi-phy-mode = <0x01>;
		hw,lcdkit-mipi-eotp-disable-flag = <0x00>;
		hw,lcdkit-blpwm-input-disable = <0x00>;
		hw,lcdkit-dirt-left-align = <0x02>;
		hw,lcdkit-dirt-right-align = <0x02>;
		hw,lcdkit-dirt-top-align = <0x02>;
		hw,lcdkit-dirt-bott-align = <0x02>;
		hw,lcdkit-dirt-width-align = <0x02>;
		hw,lcdkit-dirt-height-align = <0x02>;
		hw,lcdkit-dirt-width-min = <0x02>;
		hw,lcdkit-dirt-height-min = <0x02>;
		hw,lcdkit-dirt-top-start = <0xffff>;
		hw,lcdkit-dirt-bott-start = <0xffff>;
		hw,lcdkit-bl-byte-order = <0x00>;
		hw,lcdkit-iovcc-before-vci-flag = <0x00>;
		pinctrl-names = "default", "idle";
		hw,lcdkit-sbl-support = <0x00>;
		hw,lcdkit-gamma-support = <0x00>;
		hw,lcdkit-gmp-support = <0x00>;
		hw,lcdkit-color-temp-support = <0x00>;
		hw,lcdkit-color-temp-rectify-support = <0x00>;
		hw,lcdkit-comform-mode-support = <0x00>;
		hw,lcdkit-cinema-mode-support = <0x00>;
		hw,lcdkit-prefix-sharp-two-d-support = <0x00>;
		hw,lcdkit-xcc-support = <0x00>;
		hw,lcdkit-prefix-ce-support = <0x00>;
		hw,lcdkit-prefix-sharp-one-d-support = <0x00>;
		hw,lcdkit-acm-support = <0x00>;
		hw,lcdkit-smart-color-mode-support = <0x00>;
		hw,lcdkit-acm-ce-support = <0x00>;
		hw,lcdkit-acm-valid-num = <0x07>;
		hw,lcdkit-r_hh0 = <0x7f>;
		hw,lcdkit-r_lh0 = <0x0e>;
		hw,lcdkit-r_hh1 = <0xbe>;
		hw,lcdkit-r_lh1 = <0x80>;
		hw,lcdkit-r_hh2 = <0xff>;
		hw,lcdkit-r_lh2 = <0xbf>;
		hw,lcdkit-r_hh3 = <0x1c0>;
		hw,lcdkit-r_lh3 = <0x100>;
		hw,lcdkit-r_hh4 = <0x27f>;
		hw,lcdkit-r_lh4 = <0x1c1>;
		hw,lcdkit-r_hh5 = <0x323>;
		hw,lcdkit-r_lh5 = <0x280>;
		hw,lcdkit-r_hh6 = <0x381>;
		hw,lcdkit-r_lh6 = <0x324>;
		hw,lcdkit-r_video_hh0 = <0x7f>;
		hw,lcdkit-r_video_lh0 = <0x0e>;
		hw,lcdkit-r_video_hh1 = <0xbe>;
		hw,lcdkit-r_video_lh1 = <0x80>;
		hw,lcdkit-r_video_hh2 = <0xff>;
		hw,lcdkit-r_video_lh2 = <0xbf>;
		hw,lcdkit-r_video_hh3 = <0x1c0>;
		hw,lcdkit-r_video_lh3 = <0x100>;
		hw,lcdkit-r_video_hh4 = <0x27f>;
		hw,lcdkit-r_video_lh4 = <0x1c1>;
		hw,lcdkit-r_video_hh5 = <0x323>;
		hw,lcdkit-r_video_lh5 = <0x280>;
		hw,lcdkit-r_video_hh6 = <0x381>;
		hw,lcdkit-r_video_lh6 = <0x324>;
		hw,lcdkit-color-temp-rectify-r = <0x8000>;
		hw,lcdkit-color-temp-rectify-g = <0x8000>;
		hw,lcdkit-color-temp-rectify-b = <0x8000>;
		hw,lcdkit-hiace-support = <0x00>;
		hw,lcdkit-panel-effect-support = <0x00>;
		hw,lcdkit-arsr1p-sharpness-support = <0x00>;
		hw,lcdkit-iglobal-hist-black-pos = <0x10>;
		hw,lcdkit-iglobal-hist-white-pos = <0xf0>;
		hw,lcdkit-iglobal-hist-black-weight = <0x33>;
		hw,lcdkit-iglobal-hist-white-weight = <0x33>;
		hw,lcdkit-iglobal-hist-zero-cut-ratio = <0x1e6>;
		hw,lcdkit-iglobal-hist-slope-cut-ratio = <0x19a>;
		hw,lcdkit-imax-lcd-luminance = <0x1f4>;
		hw,lcdkit-imin-lcd-luminance = <0x03>;
		hw,lcdkit-cfg-name = "/product/etc/display/effect/algorithm/hdr_engine.xml";
		hw,lcdkit-effect-support-mode = <0x10001>;
		hw,lcdkit-bl-support-mode = <0x00>;
		hw,lcdkit-bl-enhance = <0x00>;
		hw,lcdkit-bl-normal = <0x00>;
		hw,lcdkit-delay-af-rst-off = <0x05>;
		hw,lcdkit-h-back-porch = <0x0a>;
		hw,lcdkit-h-front-porch = <0x78>;
		hw,lcdkit-h-pulse-width = <0x08>;
		hw,lcdkit-v-back-porch = <0x1e>;
		hw,lcdkit-v-pulse-width = <0x0a>;
		hw,lcdkit-v-front-porch = <0x0a>;
		hw,lcdkit-h-sync-skew = <0x00>;
		hw,lcdkit-lcd-type = <0x01>;
		hw,lcdkit-panel-pt-test-support = <0x00>;
		hw,lcdkit-mipi-clk-config-support = <0x00>;
		hw,lcdkit-panel-hkadc-support = <0x00>;
		hw,lcdkit-bias-power-ctrl-mode = <0x10>;
		hw,lcdkit-iovcc-power-ctrl-mode = <0x01>;
		hw,lcdkit-vci-power-ctrl-mode = <0x01>;
		hw,lcdkit-id0-gpio = <0x83>;
		hw,lcdkit-id1-gpio = <0x00>;
		hw,lcdkit-reset-gpio = <0x1d>;
		hw,lcdkit-te-gpio = <0x10>;
		hw,lcdkit-vsp-gpio = <0x00>;
		hw,lcdkit-vsn-gpio = <0x00>;
		hw,lcdkit-iovcc-gpio = <0x00>;
		hw,lcdkit-vci-gpio = <0x00>;
		hw,lcdkit-bl-gpio = <0x00>;
		hw,lcdkit-err-flag-gpio = <0x0c>;
		hw,lcdkit-iovcc-on-is-need-reset = <0x00>;
		hw,lcdkit-vsn-on-is-need-reset = <0x01>;
		hw,lcdkit-reset-pull-high-flag = <0x00>;
		hw,lcdkit-lcdanalog-vcc = <0x2f4d60>;
		hw,lcdkit-lcdio-vcc = <0x1c3a90>;
		hw,lcdkit-lcd-bias = <0x53ec60>;
		hw,lcdkit-lcd-vsp = <0x53ec60>;
		hw,lcdkit-lcd-vsn = <0x53ec60>;
		hw,lcdkit-lcd-rst-first-high = <0x01>;
		hw,lcdkit-lcd-rst-low = <0x01>;
		hw,lcdkit-lcd-rst-second-high = <0x0f>;
		hw,lcdkit-delay-af-vci-on = <0x05>;
		hw,lcdkit-delay-af-iovcc-on = <0x05>;
		hw,lcdkit-delay-af-bias-on = <0x00>;
		hw,lcdkit-delay-af-vsp-on = <0x05>;
		hw,lcdkit-delay-af-vsn-on = <0x05>;
		hw,lcdkit-delay-af-lp11 = <0x0a>;
		hw,lcdkit-delay-af-tp-reset = <0x0f>;
		hw,lcdkit-tp-reset-before-lcd-reset = <0x00>;
		hw,lcdkit-delay-af-vsn-off = <0x05>;
		hw,lcdkit-delay-af-vsp-off = <0x05>;
		hw,lcdkit-delay-af-bias-off = <0x00>;
		hw,lcdkit-delay-af-vbat-off = <0x00>;
		hw,lcdkit-delay-af-iovcc-off = <0x0a>;
		hw,lcdkit-delay-af-vci-off = <0x0a>;
	};

	lcdkit_neo_tugl_boe_sw43404_5p99 {
		compatible = "boe_sw43404_5p99_1440plus_cmd";
		hw,lcdkit-panel-name = "BOE_SW43404 5.99' CMD TFT 1440 x 2880";
		hw,lcdkit-panel-type = <0x02>;
		hw,lcdkit-panel-xres = <0x5a0>;
		hw,lcdkit-panel-yres = <0xb40>;
		hw,lcdkit-panel-width = <0x44>;
		hw,lcdkit-panel-height = <0x88>;
		hw,lcdkit-panel-on-command = <0x15 0x01 0x00 0x00 0x0a 0x00 0x02 0x01 0x00 0x0a 0x01 0x00 0x00 0x05 0x01 0x58 0x11 0x00 0x00 0x89 0x30 0x80 0x0b 0x40 0x05 0xa0 0x02 0xd0 0x02 0xd0 0x02 0xd0 0x02 0x00 0x02 0x68 0x00 0x20 0x4e 0xa8 0x00 0x0a 0x00 0x0c 0x00 0x23 0x00 0x1c 0x18 0x00 0x10 0xf0 0x03 0x0c 0x20 0x00 0x06 0x0b 0x0b 0x33 0x0e 0x1c 0x2a 0x38 0x46 0x54 0x62 0x69 0x70 0x77 0x79 0x7b 0x7d 0x7e 0x01 0x02 0x01 0x00 0x09 0x40 0x09 0xbe 0x19 0xfc 0x19 0xfa 0x19 0xf8 0x1a 0x38 0x1a 0x78 0x1a 0xb6 0x2a 0xf6 0x2b 0x34 0x2b 0x74 0x3b 0x74 0x6b 0xf4 0x39 0x01 0x00 0x00 0x0a 0x00 0x03 0xb0 0xa5 0x00 0x39 0x01 0x00 0x00 0x0a 0x00 0x09 0xf8 0x00 0x08 0x10 0x08 0x2d 0x00 0x00 0x2d 0x15 0x01 0x00 0x00 0x0a 0x00 0x02 0x55 0x0c 0x39 0x01 0x00 0x00 0x0a 0x00 0x03 0x51 0x00 0x00 0x05 0x01 0x00 0x00 0x0a 0x00 0x02 0x11 0x00 0x05 0x01 0x00 0x00 0x64 0x01 0x02 0x35 0x00 0x39 0x01 0x00 0x00 0x0a 0x00 0x05 0xc0 0x00 0x48 0x65 0x51 0x39 0x01 0x00 0x00 0x0a 0x00 0x03 0xb0 0xa5 0x00 0x39 0x01 0x00 0x00 0x0a 0x00 0x03 0xe0 0x18 0x01 0x39 0x01 0x00 0x00 0x0a 0x00 0x0c 0xe5 0x04 0x84 0x13 0x03 0x56 0x33 0x00 0xff 0x00 0xff 0x03 0x05 0x01 0x00 0x00 0x0a 0x00 0x02 0x29 0x00>;
		hw,lcdkit-panel-on-command-state = "dsi_lp_mode";
		hw,lcdkit-panel-display-on-command = <0x05 0x01 0x00 0x00 0x64 0x00 0x02 0x29 0x00>;
		hw,lcdkit-panel-off-command = <0x05 0x01 0x00 0x00 0x0a 0x01 0x02 0x28 0x00 0x05 0x01 0x00 0x00 0x78 0x01 0x02 0x10 0x00>;
		hw,lcdkit-panel-off-command-state = "dsi_lp_mode";
		hw,lcdkit-panel-backlight-command = <0x39 0x01 0x00 0x00 0x00 0x00 0x03 0x51 0x00 0x00>;
		hw,lcdkit-panel-backlight-command-state = "dsi_lp_mode";
		hw,lcdkit-panel-cabc-support = <0x00>;
		hw,lcdkit-panel-hbm-enter-command = <0x15 0x01 0x00 0x00 0x0a 0x00 0x02 0x55 0x0c>;
		hw,lcdkit-panel-hbm-enter-command-state = "dsi_lp_mode";
		hw,lcdkit-panel-hbm-exit-command = <0x15 0x01 0x00 0x00 0x0a 0x00 0x02 0x55 0x08>;
		hw,panel-hbm-exit-command-state = "dsi_lp_mode";
		hw,lcdkit-panel-rgbw-support = <0x00>;
		hw,lcdkit-panel-hbm-support = <0x00>;
		hw,lcdkit-panel-display-on-effect-command = <0x15 0x01 0x00 0x00 0x0a 0x00 0x02 0xff 0x23 0x15 0x01 0x00 0x00 0x0a 0x00 0x02 0xfb 0x01 0x15 0x01 0x00 0x00 0x0a 0x00 0x02 0x00 0x02 0x15 0x01 0x00 0x00 0x0a 0x00 0x02 0x01 0x84 0x15 0x01 0x00 0x00 0x0a 0x00 0x02 0x05 0x24 0x15 0x01 0x00 0x00 0x0a 0x00 0x02 0x19 0x00 0x15 0x01 0x00 0x00 0x0a 0x00 0x02 0x1a 0x04 0x15 0x01 0x00 0x00 0x0a 0x00 0x02 0x1b 0x08 0x15 0x01 0x00 0x00 0x0a 0x00 0x02 0x1c 0x0c 0x15 0x01 0x00 0x00 0x0a 0x00 0x02 0x1d 0x10 0x15 0x01 0x00 0x00 0x0a 0x00 0x02 0x1e 0x14 0x15 0x01 0x00 0x00 0x0a 0x00 0x02 0x1f 0x18 0x15 0x01 0x00 0x00 0x0a 0x00 0x02 0x20 0x1c 0x15 0x01 0x00 0x00 0x0a 0x00 0x02 0x21 0x20 0x15 0x01 0x00 0x00 0x0a 0x00 0x02 0x22 0x24 0x15 0x01 0x00 0x00 0x0a 0x00 0x02 0x23 0x28 0x15 0x01 0x00 0x00 0x0a 0x00 0x02 0x24 0x2c 0x15 0x01 0x00 0x00 0x0a 0x00 0x02 0x25 0x30 0x15 0x01 0x00 0x00 0x0a 0x00 0x02 0x26 0x34 0x15 0x01 0x00 0x00 0x0a 0x00 0x02 0x27 0x38 0x15 0x01 0x00 0x00 0x0a 0x00 0x02 0x28 0x3c 0x15 0x01 0x00 0x00 0x0a 0x00 0x02 0x29 0x24 0x15 0x01 0x00 0x00 0x0a 0x00 0x02 0x2b 0x3d 0x15 0x01 0x00 0x00 0x0a 0x00 0x02 0x30 0xff 0x15 0x01 0x00 0x00 0x0a 0x00 0x02 0x31 0xfd 0x15 0x01 0x00 0x00 0x0a 0x00 0x02 0x32 0xfb 0x15 0x01 0x00 0x00 0x0a 0x00 0x02 0x33 0xf9 0x15 0x01 0x00 0x00 0x0a 0x00 0x02 0x34 0xf7 0x15 0x01 0x00 0x00 0x0a 0x00 0x02 0x35 0xf5 0x15 0x01 0x00 0x00 0x0a 0x00 0x02 0x36 0xf3 0x15 0x01 0x00 0x00 0x0a 0x00 0x02 0x37 0xf1 0x15 0x01 0x00 0x00 0x0a 0x00 0x02 0x38 0xef 0x15 0x01 0x00 0x00 0x0a 0x00 0x02 0x39 0xed 0x15 0x01 0x00 0x00 0x0a 0x00 0x02 0x3a 0xeb 0x15 0x01 0x00 0x00 0x0a 0x00 0x02 0x3b 0xe9 0x15 0x01 0x00 0x00 0x0a 0x00 0x02 0x3d 0xe7 0x15 0x01 0x00 0x00 0x0a 0x00 0x02 0x3f 0xe5 0x15 0x01 0x00 0x00 0x0a 0x00 0x02 0x40 0xe3 0x15 0x01 0x00 0x00 0x0a 0x00 0x02 0x41 0xe0 0x15 0x01 0x00 0x00 0x0a 0x00 0x02 0x45 0xff 0x15 0x01 0x00 0x00 0x0a 0x00 0x02 0x46 0xfd 0x15 0x01 0x00 0x00 0x0a 0x00 0x02 0x47 0xfb 0x15 0x01 0x00 0x00 0x0a 0x00 0x02 0x48 0xf9 0x15 0x01 0x00 0x00 0x0a 0x00 0x02 0x49 0xf7 0x15 0x01 0x00 0x00 0x0a 0x00 0x02 0x4a 0xf5 0x15 0x01 0x00 0x00 0x0a 0x00 0x02 0x4b 0xf3 0x15 0x01 0x00 0x00 0x0a 0x00 0x02 0x4c 0xf1 0x15 0x01 0x00 0x00 0x0a 0x00 0x02 0x4d 0xef 0x15 0x01 0x00 0x00 0x0a 0x00 0x02 0x4e 0xed 0x15 0x01 0x00 0x00 0x0a 0x00 0x02 0x4f 0xeb 0x15 0x01 0x00 0x00 0x0a 0x00 0x02 0x50 0xe9 0x15 0x01 0x00 0x00 0x0a 0x00 0x02 0x51 0xe7 0x15 0x01 0x00 0x00 0x0a 0x00 0x02 0x52 0xe5 0x15 0x01 0x00 0x00 0x0a 0x00 0x02 0x53 0xe3 0x15 0x01 0x00 0x00 0x0a 0x00 0x02 0x54 0xe0 0x15 0x01 0x00 0x00 0x0a 0x00 0x02 0x58 0xff 0x15 0x01 0x00 0x00 0x0a 0x00 0x02 0x59 0xf8 0x15 0x01 0x00 0x00 0x0a 0x00 0x02 0x5a 0xf1 0x15 0x01 0x00 0x00 0x0a 0x00 0x02 0x5b 0xea 0x15 0x01 0x00 0x00 0x0a 0x00 0x02 0x5c 0xe3 0x15 0x01 0x00 0x00 0x0a 0x00 0x02 0x5d 0xdc 0x15 0x01 0x00 0x00 0x0a 0x00 0x02 0x5e 0xd5 0x15 0x01 0x00 0x00 0x0a 0x00 0x02 0x5f 0xce 0x15 0x01 0x00 0x00 0x0a 0x00 0x02 0x60 0xc7 0x15 0x01 0x00 0x00 0x0a 0x00 0x02 0x61 0xc0 0x15 0x01 0x00 0x00 0x0a 0x00 0x02 0x62 0xb9 0x15 0x01 0x00 0x00 0x0a 0x00 0x02 0x63 0xb2 0x15 0x01 0x00 0x00 0x0a 0x00 0x02 0x64 0xab 0x15 0x01 0x00 0x00 0x0a 0x00 0x02 0x65 0xa4 0x15 0x01 0x00 0x00 0x0a 0x00 0x02 0x66 0x9d 0x15 0x01 0x00 0x00 0x0a 0x00 0x02 0x67 0x96 0x15 0x01 0x00 0x00 0x0a 0x00 0x02 0xff 0x10 0x15 0x01 0x00 0x00 0x0a 0x00 0x02 0xff 0x22 0x15 0x01 0x00 0x00 0x0a 0x00 0x02 0xfb 0x01 0x15 0x01 0x00 0x00 0x0a 0x00 0x02 0x00 0x40 0x15 0x01 0x00 0x00 0x0a 0x00 0x02 0x01 0x54 0x15 0x01 0x00 0x00 0x0a 0x00 0x02 0x02 0x5a 0x15 0x01 0x00 0x00 0x0a 0x00 0x02 0x03 0x60 0x15 0x01 0x00 0x00 0x0a 0x00 0x02 0x04 0x66 0x15 0x01 0x00 0x00 0x0a 0x00 0x02 0x05 0x6a 0x15 0x01 0x00 0x00 0x0a 0x00 0x02 0x06 0x6c 0x15 0x01 0x00 0x00 0x0a 0x00 0x02 0x07 0x6c 0x15 0x01 0x00 0x00 0x0a 0x00 0x02 0x08 0x68 0x15 0x01 0x00 0x00 0x0a 0x00 0x02 0x09 0x62 0x15 0x01 0x00 0x00 0x0a 0x00 0x02 0x0a 0x5b 0x15 0x01 0x00 0x00 0x0a 0x00 0x02 0x0b 0x53 0x15 0x01 0x00 0x00 0x0a 0x00 0x02 0x0c 0x4d 0x15 0x01 0x00 0x00 0x0a 0x00 0x02 0x0d 0x43 0x15 0x01 0x00 0x00 0x0a 0x00 0x02 0x0e 0x44 0x15 0x01 0x00 0x00 0x0a 0x00 0x02 0x0f 0x41 0x15 0x01 0x00 0x00 0x0a 0x00 0x02 0x10 0x40 0x15 0x01 0x00 0x00 0x0a 0x00 0x02 0x11 0x50 0x15 0x01 0x00 0x00 0x0a 0x00 0x02 0x12 0x60 0x15 0x01 0x00 0x00 0x0a 0x00 0x02 0x13 0x70 0x15 0x01 0x00 0x00 0x0a 0x00 0x02 0x14 0x58 0x15 0x01 0x00 0x00 0x0a 0x00 0x02 0x15 0x68 0x15 0x01 0x00 0x00 0x0a 0x00 0x02 0x16 0x78 0x15 0x01 0x00 0x00 0x0a 0x00 0x02 0x17 0x00 0x15 0x01 0x00 0x00 0x0a 0x00 0x02 0x18 0x40 0x15 0x01 0x00 0x00 0x0a 0x00 0x02 0x19 0x40 0x15 0x01 0x00 0x00 0x0a 0x00 0x02 0x1a 0x40 0x15 0x01 0x00 0x00 0x0a 0x00 0x02 0x1b 0x40 0x15 0x01 0x00 0x00 0x0a 0x00 0x02 0x1c 0x40 0x15 0x01 0x00 0x00 0x0a 0x00 0x02 0x1d 0x40 0x15 0x01 0x00 0x00 0x0a 0x00 0x02 0x1e 0x40 0x15 0x01 0x00 0x00 0x0a 0x00 0x02 0x1f 0x40 0x15 0x01 0x00 0x00 0x0a 0x00 0x02 0x20 0x40 0x15 0x01 0x00 0x00 0x0a 0x00 0x02 0x21 0x45 0x15 0x01 0x00 0x00 0x0a 0x00 0x02 0x22 0x49 0x15 0x01 0x00 0x00 0x0a 0x00 0x02 0x23 0x4c 0x15 0x01 0x00 0x00 0x0a 0x00 0x02 0x24 0x4b 0x15 0x01 0x00 0x00 0x0a 0x00 0x02 0x25 0x48 0x15 0x01 0x00 0x00 0x0a 0x00 0x02 0x26 0x44 0x15 0x01 0x00 0x00 0x0a 0x00 0x02 0x27 0x41 0x15 0x01 0x00 0x00 0x0a 0x00 0x02 0x28 0x40 0x15 0x01 0x00 0x00 0x0a 0x00 0x02 0x2d 0x00 0x15 0x01 0x00 0x00 0x0a 0x00 0x02 0x2f 0x40 0x15 0x01 0x00 0x00 0x0a 0x00 0x02 0x30 0x40 0x15 0x01 0x00 0x00 0x0a 0x00 0x02 0x31 0x3e 0x15 0x01 0x00 0x00 0x0a 0x00 0x02 0x32 0x3e 0x15 0x01 0x00 0x00 0x0a 0x00 0x02 0x33 0x3b 0x15 0x01 0x00 0x00 0x0a 0x00 0x02 0x34 0x3a 0x15 0x01 0x00 0x00 0x0a 0x00 0x02 0x35 0x3a 0x15 0x01 0x00 0x00 0x0a 0x00 0x02 0x36 0x3a 0x15 0x01 0x00 0x00 0x0a 0x00 0x02 0x37 0x3a 0x15 0x01 0x00 0x00 0x0a 0x00 0x02 0x38 0x3b 0x15 0x01 0x00 0x00 0x0a 0x00 0x02 0x39 0x3c 0x15 0x01 0x00 0x00 0x0a 0x00 0x02 0x3a 0x3e 0x15 0x01 0x00 0x00 0x0a 0x00 0x02 0x3b 0x3f 0x15 0x01 0x00 0x00 0x0a 0x00 0x02 0x3d 0x40 0x15 0x01 0x00 0x00 0x0a 0x00 0x02 0x3f 0x40 0x15 0x01 0x00 0x00 0x0a 0x00 0x02 0x40 0x40 0x15 0x01 0x00 0x00 0x0a 0x00 0x02 0x41 0x40 0x15 0x01 0x00 0x00 0x0a 0x00 0x02 0x42 0x40 0x15 0x01 0x00 0x00 0x0a 0x00 0x02 0x43 0x40 0x15 0x01 0x00 0x00 0x0a 0x00 0x02 0x44 0x3e 0x15 0x01 0x00 0x00 0x0a 0x00 0x02 0x45 0x3e 0x15 0x01 0x00 0x00 0x0a 0x00 0x02 0x46 0x3b 0x15 0x01 0x00 0x00 0x0a 0x00 0x02 0x47 0x3a 0x15 0x01 0x00 0x00 0x0a 0x00 0x02 0x48 0x3a 0x15 0x01 0x00 0x00 0x0a 0x00 0x02 0x49 0x3a 0x15 0x01 0x00 0x00 0x0a 0x00 0x02 0x4a 0x3a 0x15 0x01 0x00 0x00 0x0a 0x00 0x02 0x4b 0x3a 0x15 0x01 0x00 0x00 0x0a 0x00 0x02 0x4c 0x3a 0x15 0x01 0x00 0x00 0x0a 0x00 0x02 0x4d 0x3a 0x15 0x01 0x00 0x00 0x0a 0x00 0x02 0x4e 0x3a 0x15 0x01 0x00 0x00 0x0a 0x00 0x02 0x4f 0x3b 0x15 0x01 0x00 0x00 0x0a 0x00 0x02 0x50 0x3d 0x15 0x01 0x00 0x00 0x0a 0x00 0x02 0x51 0x3f 0x15 0x01 0x00 0x00 0x0a 0x00 0x02 0x52 0x40 0x15 0x01 0x00 0x00 0x0a 0x00 0x02 0x53 0x77 0x15 0x01 0x00 0x00 0x0a 0x00 0x02 0x54 0x00 0x15 0x01 0x00 0x00 0x0a 0x00 0x02 0x55 0x88 0x15 0x01 0x00 0x00 0x0a 0x00 0x02 0x56 0x77 0x15 0x01 0x00 0x00 0x0a 0x00 0x02 0x58 0xc0 0x15 0x01 0x00 0x00 0x0a 0x00 0x02 0x59 0xc0 0x15 0x01 0x00 0x00 0x0a 0x00 0x02 0x5a 0x40 0x15 0x01 0x00 0x00 0x0a 0x00 0x02 0x5b 0x40 0x15 0x01 0x00 0x00 0x0a 0x00 0x02 0x5c 0x40 0x15 0x01 0x00 0x00 0x0a 0x00 0x02 0x5d 0x40 0x15 0x01 0x00 0x00 0x0a 0x00 0x02 0x5e 0x40 0x15 0x01 0x00 0x00 0x0a 0x00 0x02 0x5f 0x40 0x15 0x01 0x00 0x00 0x0a 0x00 0x02 0x60 0x40 0x15 0x01 0x00 0x00 0x0a 0x00 0x02 0x61 0x40 0x15 0x01 0x00 0x00 0x0a 0x00 0x02 0x62 0x40 0x15 0x01 0x00 0x00 0x0a 0x00 0x02 0x63 0x40 0x15 0x01 0x00 0x00 0x0a 0x00 0x02 0x64 0x40 0x15 0x01 0x00 0x00 0x0a 0x00 0x02 0x65 0x40 0x15 0x01 0x00 0x00 0x0a 0x00 0x02 0x66 0x40 0x15 0x01 0x00 0x00 0x0a 0x00 0x02 0x67 0x40 0x15 0x01 0x00 0x00 0x0a 0x00 0x02 0x68 0x40 0x15 0x01 0x00 0x00 0x0a 0x00 0x02 0x69 0x40 0x15 0x01 0x00 0x00 0x0a 0x00 0x02 0x6a 0x40 0x15 0x01 0x00 0x00 0x0a 0x00 0x02 0x6b 0x40 0x15 0x01 0x00 0x00 0x0a 0x00 0x02 0x6c 0x40 0x15 0x01 0x00 0x00 0x0a 0x00 0x02 0x6d 0x40 0x15 0x01 0x00 0x00 0x0a 0x00 0x02 0x6e 0x40 0x15 0x01 0x00 0x00 0x0a 0x00 0x02 0x6f 0x40 0x15 0x01 0x00 0x00 0x0a 0x00 0x02 0x70 0x0c 0x15 0x01 0x00 0x00 0x0a 0x00 0x02 0x71 0x00 0x15 0x01 0x00 0x00 0x0a 0x00 0x02 0x72 0x00 0x15 0x01 0x00 0x00 0x0a 0x00 0x02 0x73 0x00 0x15 0x01 0x00 0x00 0x0a 0x00 0x02 0x74 0x03 0x15 0x01 0x00 0x00 0x0a 0x00 0x02 0x75 0x0c 0x15 0x01 0x00 0x00 0x0a 0x00 0x02 0x76 0x03 0x15 0x01 0x00 0x00 0x0a 0x00 0x02 0x77 0x09 0x15 0x01 0x00 0x00 0x0a 0x00 0x02 0x78 0x0f 0x15 0x01 0x00 0x00 0x0a 0x00 0x02 0x79 0x68 0x15 0x01 0x00 0x00 0x0a 0x00 0x02 0x7a 0x88 0x15 0x01 0x00 0x00 0x0a 0x00 0x02 0x83 0x00 0x15 0x01 0x00 0x00 0x0a 0x00 0x02 0x84 0x28 0x15 0x01 0x00 0x00 0x0a 0x00 0x02 0x85 0x5f 0x15 0x01 0x00 0x00 0x0a 0x00 0x02 0x86 0x50 0x15 0x01 0x00 0x00 0x0a 0x00 0x02 0x87 0x22 0x15 0x01 0x00 0x00 0x0a 0x00 0x02 0x88 0x40 0x15 0x01 0x00 0x00 0x0a 0x00 0x02 0x89 0x4e 0x15 0x01 0x00 0x00 0x0a 0x00 0x02 0x8a 0x4f 0x15 0x01 0x00 0x00 0x0a 0x00 0x02 0x8b 0x50 0x15 0x01 0x00 0x00 0x0a 0x00 0x02 0x8c 0x50 0x15 0x01 0x00 0x00 0x0a 0x00 0x02 0x8d 0x40 0x15 0x01 0x00 0x00 0x0a 0x00 0x02 0x8e 0x40 0x15 0x01 0x00 0x00 0x0a 0x00 0x02 0x8f 0x00 0x15 0x01 0x00 0x00 0x0a 0x00 0x02 0x90 0x1e 0x15 0x01 0x00 0x00 0x0a 0x00 0x02 0x91 0x23 0x15 0x01 0x00 0x00 0x0a 0x00 0x02 0x92 0x3a 0x15 0x01 0x00 0x00 0x0a 0x00 0x02 0x93 0x40 0x15 0x01 0x00 0x00 0x0a 0x00 0x02 0x94 0x40 0x15 0x01 0x00 0x00 0x0a 0x00 0x02 0x95 0x40 0x15 0x01 0x00 0x00 0x0a 0x00 0x02 0x96 0x49 0x15 0x01 0x00 0x00 0x0a 0x00 0x02 0x97 0x49 0x15 0x01 0x00 0x00 0x0a 0x00 0x02 0x98 0x43 0x15 0x01 0x00 0x00 0x0a 0x00 0x02 0x99 0x43 0x15 0x01 0x00 0x00 0x0a 0x00 0x02 0x9a 0x3c 0x15 0x01 0x00 0x00 0x0a 0x00 0x02 0x9b 0x40 0x15 0x01 0x00 0x00 0x0a 0x00 0x02 0x9c 0x40 0x15 0x01 0x00 0x00 0x0a 0x00 0x02 0x9d 0x40 0x15 0x01 0x00 0x00 0x0a 0x00 0x02 0x9e 0x4c 0x15 0x01 0x00 0x00 0x0a 0x00 0x02 0x9f 0x4d 0x15 0x01 0x00 0x00 0x0a 0x00 0x02 0xa0 0x4e 0x15 0x01 0x00 0x00 0x0a 0x00 0x02 0xa2 0x20 0x15 0x01 0x00 0x00 0x0a 0x00 0x02 0xb3 0x00 0x15 0x01 0x00 0x00 0x0a 0x00 0x02 0xb7 0x00 0x15 0x01 0x00 0x00 0x0a 0x00 0x02 0xb8 0x00 0x15 0x01 0x00 0x00 0x0a 0x00 0x02 0xff 0x10 0x15 0x01 0x00 0x00 0x0a 0x00 0x02 0x53 0x24 0x15 0x01 0x00 0x00 0x0a 0x00 0x02 0x55 0x81>;
		hw,lcdkit-panel-display-on-effect-support = <0x00>;
		hw,lcdkit-panel-ce-off-command;
		hw,lcdkit-panel-ce-srgb-command;
		hw,lcdkit-panel-ce-user-command;
		hw,lcdkit-panel-ce-vivid-command;
		hw,lcdkit-panel-ce-support = <0x00>;
		hw,lcdkit-panel-version-support = <0x00>;
		hw,lcdkit-panel-otp-support = <0x00>;
		hw,lcdkit-panel-inversion-support = <0x00>;
		hw,lcdkit-panel-scan-support = <0x00>;
		hw,lcdkit-panel-display-region-command = <0x39 0x01 0x00 0x00 0x05 0x00 0x05 0x2a 0x00 0x00 0x05 0x9f 0x39 0x01 0x00 0x00 0x05 0x00 0x05 0x2b 0x00 0x00 0x0b 0x3f>;
		hw,lcdkit-panel-display-region-command-state = "dsi_lp_mode";
		hw,lcdkit-panel-display-region-support = <0x01>;
		hw,lcdkit-panel-checksum-support = <0x00>;
		hw,lcdkit-panel-esd-reg-command = <0x06 0x01 0x00 0x00 0x0a 0x00 0x01 0x0a 0x06 0x01 0x00 0x00 0x0a 0x00 0x01 0x0e>;
		hw,lcdkit-panel-esd-reg-command-state = "dsi_lp_mode";
		hw,lcdkit-panel-esd-value = <0x9c 0x00>;
		hw,lcdkit-panel-esd-support = <0x01>;
		hw,lcdkit-panel-check-reg-command = <0x06 0x01 0x00 0x00 0x0a 0x00 0x01 0x0a>;
		hw,lcdkit-panel-check-reg-value = <0x9c>;
		hw,lcdkit-panel-check-reg-command-state = "dsi_lp_mode";
		hw,lcdkit-panel-check-reg-support = <0x00>;
		hw,lcdkit-panel-brightness-color-uniform-support = <0x00>;
		hw,lcdkit-panel-dynamic-gamma-support = <0x01>;
		hw,lcdkit-panel-mipi-detect-support = <0x00>;
		hw,lcdkit-panel-dynamic-sram-check-support = <0x00>;
		hw,lcdkit-panel-fps-updt-support = <0x00>;
		hw,lcdkit-panel-fps-func-switch = <0x00>;
		hw,lcdkit-panel-check-reg-on-support = <0x00>;
		hw,lcdkit-panel-fps-tscall-support = <0x00>;
		hw,lcdkit-panel-dis-on-cmds-delay-margin-support = <0x00>;
		hw,lcdkit-panel-snd-cmd-before-frame-support = <0x00>;
		hw,lcdkit-panel-ts-resume-ctrl-mode = <0x00>;
		hw,lcdkit-panel-dis-on-cmds-delay-margin-time = <0x00>;
		hw,lcdkit-panel-lptohs-mipi-check-support = <0x00>;
		hw,lcdkit-panel-acl-ctrl-support = <0x00>;
		hw,lcdkit-panel-acl-off-command = <0x15 0x01 0x00 0x00 0x0a 0x00 0x02 0x55 0x0c>;
		hw,lcdkit-panel-acl-off-command-state = "dsi_lp_mode";
		hw,lcdkit-panel-acl-low-command = <0x15 0x01 0x00 0x00 0x0a 0x00 0x02 0x55 0x0f>;
		hw,lcdkit-panel-acl-low-command-state = "dsi_lp_mode";
		hw,lcdkit-panel-acl-middle-command = <0x15 0x01 0x00 0x00 0x0a 0x00 0x02 0x55 0x0e>;
		hw,lcdkit-panel-acl-middle-command-state = "dsi_lp_mode";
		hw,lcdkit-panel-acl-high-command = <0x15 0x01 0x00 0x00 0x0a 0x00 0x02 0x55 0x0d>;
		hw,lcdkit-panel-acl-high-command-state = "dsi_lp_mode";
		hw,lcdkit-panel-hbm-ctrl-support = <0x00>;
		hw,lcdkit-panel-vr-support = <0x00>;
		hw,lcdkit-panel-current-detect-support = <0x00>;
		hw,lcdkit-panel-lv-detect-support = <0x00>;
		hw,lcdkit-reset-shutdown-later = <0x01>;
		hw,lcdkit-panel-pcd-errflag-check-support = <0x01>;
		hw,lcdkit-panel-pt-ulps-support = <0x00>;
		hw,lcdkit-panel-aod-support = <0x00>;
		hw,lcdkit-panel-enter-aod-command = <0x39 0x01 0x00 0x00 0x0a 0x00 0x03 0xb0 0xa5 0x00 0x39 0x01 0x00 0x00 0x0a 0x00 0x03 0xc0 0x00 0x43 0x39 0x01 0x00 0x00 0x0a 0x00 0x03 0xe0 0x18 0x01 0x39 0x01 0x00 0x00 0x32 0x00 0x1f 0xbd 0x02 0xd5 0x00 0x02 0xd5 0x00 0x02 0xd5 0x00 0x02 0xd5 0x00 0x02 0xd5 0x00 0x02 0xd5 0x00 0x02 0xd5 0x00 0x02 0xd5 0x00 0x02 0xd5 0x00 0x02 0xd5 0x00 0x39 0x01 0x00 0x00 0x32 0x00 0x13 0xbe 0x02 0xd5 0x00 0x02 0xd5 0x00 0x02 0xd5 0x00 0x00 0x00 0x00 0x00 0x00 0x00 0x00 0x00 0x00 0x39 0x01 0x00 0x00 0x0a 0x00 0x03 0x51 0x00 0x00 0x05 0x01 0x00 0x00 0x32 0x01 0x01 0x39>;
		hw,lcdkit-panel-aod-low-brightness-command = <0x39 0x01 0x00 0x00 0x0a 0x00 0x03 0x51 0x04 0x00 0x39 0x01 0x00 0x00 0x32 0x00 0x1f 0xbd 0x20 0x01 0xd4 0x20 0x01 0xd4 0x20 0x94 0x41 0x11 0x10 0xc5 0x11 0x7d 0x58 0x11 0xd5 0x00 0x02 0x1f 0xb6 0x02 0x5f 0x76 0x02 0x9d 0x38 0x02 0xd3 0x02 0x39 0x01 0x00 0x00 0x32 0x00 0x13 0xbe 0x20 0x00 0xd5 0x02 0xbf 0x16 0x02 0xbf 0x16 0x00 0x00 0x00 0x00 0x00 0x00 0x00 0x00 0x00 0x05 0x01 0x00 0x00 0x0a 0x00 0x01 0x29>;
		hw,lcdkit-panel-exit-aod-command = <0x39 0x01 0x00 0x00 0x0a 0x00 0x03 0xb0 0xa5 0x00 0x39 0x01 0x00 0x00 0x0a 0x00 0x03 0xc0 0x00 0x43 0x39 0x01 0x00 0x00 0x0a 0x00 0x03 0xe0 0x18 0x00 0x39 0x01 0x00 0x00 0x32 0x00 0x1f 0xbd 0x02 0xd5 0x00 0x02 0xd5 0x00 0x02 0xd5 0x00 0x02 0xd5 0x00 0x02 0xd5 0x00 0x02 0xd5 0x00 0x02 0xd5 0x00 0x02 0xd5 0x00 0x02 0xd5 0x00 0x02 0xd5 0x00 0x39 0x01 0x00 0x00 0x32 0x00 0x13 0xbe 0x02 0xd5 0x00 0x02 0xd5 0x00 0x02 0xd5 0x00 0x00 0x00 0x00 0x00 0x00 0x00 0x00 0x00 0x00 0x39 0x01 0x00 0x00 0x0a 0x00 0x03 0x51 0x00 0x00 0x05 0x01 0x00 0x00 0x46 0x01 0x01 0x38 0x39 0x01 0x00 0x00 0x32 0x00 0x1f 0xbd 0x20 0x01 0xd4 0x20 0x01 0xd4 0x20 0x94 0x41 0x11 0x10 0xc5 0x11 0x7d 0x58 0x11 0xd5 0x00 0x02 0x1f 0xb6 0x02 0x5f 0x76 0x02 0x9d 0x38 0x02 0xd5 0x00 0x39 0x01 0x00 0x00 0x32 0x00 0x13 0xbe 0x20 0x00 0xd5 0x02 0xbf 0x16 0x02 0xbf 0x16 0x00 0x00 0x00 0x00 0x00 0x00 0x00 0x00 0x00>;
		hw,lcdkit-panel-enter-aod-command-state;
		hw,lcdkit-panel-aod-low-brightness-command-state;
		hw,lcdkit-panel-exit-aod-command-state;
		hw,lcdkit-panel-orientation = <0x01>;
		hw,lcdkit-panel-bpp = <0x00>;
		hw,lcdkit-panel-bgrfmt = <0x00>;
		hw,lcdkit-panel-bl-type = <0x08>;
		hw,lcdkit-panel-blmin = <0x04>;
		hw,lcdkit-panel-blmax = <0x3ff>;
		hw,lcdkit-mask-delay-time-before-fp = <0x411a>;
		hw,lcdkit-mask-delay-time-after-fp = <0x411a>;
		hw,lcdkit-tp-reset-gpio = <0x00>;
		hw,lcdkit-panel-bl-def = <0x199>;
		hw,lcdkit-panel-bl-maxnit = <0x212>;
		hw,lcdkit-panel-getblmaxnit-type = <0x00>;
		hw,lcdkit-panel-cmd-type = <0x10>;
		hw,lcdkit-panel-ifbctype = <0x09>;
		hw,lcdkit-panel-ifbc-vesa3x-set = <0x01>;
		hw,lcdkit-panel-frc-enable = <0x00>;
		hw,lcdkit-panel-esd-skip-mipi-check = <0x01>;
		hw,lcdkit-panel-pxl-clk = <0x12c>;
		hw,lcdkit-panel-pxl-clk-div = <0x03>;
		hw,lcdkit-panel-tp-resume-nosync = <0x01>;
		hw,lcdkit-panel-display-on-in-backlight = <0x00>;
		hw,lcdkit-panel-display-on-new-seq = <0x00>;
		hw,lcdkit-panel-dirt-updt-support = <0x01>;
		hw,lcdkit-is-hostprocessing = <0x00>;
		hw,lcdkit-host-info-all-in-ddic = <0x00>;
		hw,lcdkit-panel-dsi-upt-support = <0x01>;
		hw,mipiclk-updt-support-new = <0x00>;
		hw,lcdkit-panel-vsyn-ctr-type = <0x07>;
		hw,lcdkit-panel-bl-pwm-preci-no-convert = <0x00>;
		hw,lcdkit-panel-bl-pwm-preci-type = <0x02>;
		hw,lcdkit-panel-bl-ic-ctrl-type = <0x09>;
		hw,lcdkit-panel-fps-updt-only = <0x00>;
		hw,lcdkit-panel-step-support = <0x01>;
		hw,lcdkit-ldi-hsync-plr = <0x00>;
		hw,lcdkit-ldi-vsync-plr = <0x00>;
		hw,lcdkit-ldi-pixel-clk-plr = <0x00>;
		hw,lcdkit-ldi-data-en-plr = <0x00>;
		hw,lcdkit-ldi-dpi-a-overlap-size = <0x00>;
		hw,lcdkit-ldi-dpi-b-overlap-size = <0x00>;
		hw,lcdkit-sbl-stren-limit = <0x80>;
		hw,lcdkit-sbl-cal-a = <0x3c>;
		hw,lcdkit-sbl-cal-b = <0x5f>;
		hw,lcdkit-sbl-cal-c = <0x05>;
		hw,lcdkit-sbl-cal-d = <0x01>;
		hw,lcdkit-sbl-tf-ctl = <0x05>;
		hw,lcdkit-sbl-bl-min = <0x1e0>;
		hw,lcdkit-sbl-bl-max = <0x1000>;
		hw,lcdkit-sbl-bl-scale = <0xff>;
		hw,lcdkit-sbl-am-light-min = <0x0e>;
		hw,lcdkit-sbl-filter-a = <0x6ca>;
		hw,lcdkit-sbl-filter-b = <0x06>;
		hw,lcdkit-sbl-logo-left = <0x00>;
		hw,lcdkit-sbl-logo-top = <0x00>;
		hw,lcdkit-sbl-variance-intensity-space = <0x91>;
		hw,lcdkit-sbl-slope-max = <0x36>;
		hw,lcdkit-sbl-slope-min = <0xa0>;
		hw,lcdkit-mipi-lane-nums = <0x03>;
		hw,lcdkit-mipi-color-mode = <0x05>;
		hw,lcdkit-mipi-vc = <0x00>;
		hw,lcdkit-mipi-dsi-bit-clk = <0x1e0>;
		hw,lcdkit-mipi-burst-mode = <0x02>;
		hw,lcdkit-mipi-max-esc-clk = <0x0a>;
		hw,lcdkit-mipi-dsi-bit-clk-val-a = <0x1ea>;
		hw,lcdkit-mipi-dsi-bit-clk-val-b = <0x1e0>;
		hw,lcdkit-mipi-dsi-bit-clk-val-c = <0x00>;
		hw,lcdkit-mipi-dsi-bit-clk-val-d = <0x00>;
		hw,lcdkit-mipi-dsi-bit-clk-val-e = <0x00>;
		hw,lcdkit-mipi-dsi-bit-clk-upt = <0x1e0>;
		hw,lcdkit-mipi-rg-vcm-adjust = <0x00>;
		hw,lcdkit-mipi-non-continue-enable = <0x01>;
		hw,lcdkit-mipi-clk-post-adjust = <0xd7>;
		hw,lcdkit-mipi-clk-pre-adjust = <0x00>;
		hw,lcdkit-mipi-clk-t-hs-prepare-adjust = <0x2b>;
		hw,lcdkit-mipi-clk-t-lpx-adjust = <0x00>;
		hw,lcdkit-mipi-clk-t-hs-trail-adjust = <0x00>;
		hw,lcdkit-mipi-clk-t-hs-exit-adjust = <0x00>;
		hw,lcdkit-mipi-clk-t-hs-zero-adjust = <0x00>;
		hw,lcdkit-mipi-data-t-hs-trail-adjust = <0x02>;
		hw,lcdkit-mipi-data-t-hs-prepare-adjust = <0x0e>;
		hw,lcdkit-mipi-data-t-hs-zero-adjust = <0x3c>;
		hw,lcdkit-mipi-data-t-lpx-adjust = <0x00>;
		hw,lcdkit-mipi-phy-mode = <0x00>;
		hw,lcdkit-mipi-eotp-disable-flag = <0x01>;
		hw,lcdkit-blpwm-input-disable = <0x00>;
		hw,lcdkit-dirt-left-align = <0x5a0>;
		hw,lcdkit-dirt-right-align = <0x5a0>;
		hw,lcdkit-dirt-top-align = <0x2d0>;
		hw,lcdkit-dirt-bott-align = <0x2d0>;
		hw,lcdkit-dirt-width-align = <0xffff>;
		hw,lcdkit-dirt-height-align = <0xffff>;
		hw,lcdkit-dirt-width-min = <0xffff>;
		hw,lcdkit-dirt-height-min = <0xffff>;
		hw,lcdkit-dirt-top-start = <0xffff>;
		hw,lcdkit-dirt-bott-start = <0xffff>;
		hw,lcdkit-bl-byte-order = <0x01>;
		hw,lcdkit-iovcc-before-vci-flag = <0x01>;
		pinctrl-names = "default", "idle";
		hw,lcdkit-sbl-support = <0x00>;
		hw,lcdkit-gamma-support = <0x01>;
		hw,lcdkit-gmp-support = <0x01>;
		hw,lcdkit-color-temp-support = <0x01>;
		hw,lcdkit-color-temp-rectify-support = <0x00>;
		hw,lcdkit-comform-mode-support = <0x01>;
		hw,lcdkit-cinema-mode-support = <0x00>;
		hw,lcdkit-prefix-sharp-two-d-support = <0x01>;
		hw,lcdkit-xcc-support = <0x01>;
		hw,lcdkit-prefix-ce-support = <0x00>;
		hw,lcdkit-prefix-sharp-one-d-support = <0x00>;
		hw,lcdkit-acm-support = <0x00>;
		hw,lcdkit-smart-color-mode-support = <0x00>;
		hw,lcdkit-acm-ce-support = <0x00>;
		hw,lcdkit-acm-valid-num = <0x07>;
		hw,lcdkit-r_hh0 = <0x7f>;
		hw,lcdkit-r_lh0 = <0x00>;
		hw,lcdkit-r_hh1 = <0xff>;
		hw,lcdkit-r_lh1 = <0x80>;
		hw,lcdkit-r_hh2 = <0x17f>;
		hw,lcdkit-r_lh2 = <0x100>;
		hw,lcdkit-r_hh3 = <0x1ff>;
		hw,lcdkit-r_lh3 = <0x180>;
		hw,lcdkit-r_hh4 = <0x27f>;
		hw,lcdkit-r_lh4 = <0x200>;
		hw,lcdkit-r_hh5 = <0x2ff>;
		hw,lcdkit-r_lh5 = <0x280>;
		hw,lcdkit-r_hh6 = <0x37f>;
		hw,lcdkit-r_lh6 = <0x300>;
		hw,lcdkit-r_video_hh0 = <0x7f>;
		hw,lcdkit-r_video_lh0 = <0x00>;
		hw,lcdkit-r_video_hh1 = <0x101>;
		hw,lcdkit-r_video_lh1 = <0x80>;
		hw,lcdkit-r_video_hh2 = <0x177>;
		hw,lcdkit-r_video_lh2 = <0x102>;
		hw,lcdkit-r_video_hh3 = <0x1ed>;
		hw,lcdkit-r_video_lh3 = <0x178>;
		hw,lcdkit-r_video_hh4 = <0x26f>;
		hw,lcdkit-r_video_lh4 = <0x1ee>;
		hw,lcdkit-r_video_hh5 = <0x2ff>;
		hw,lcdkit-r_video_lh5 = <0x270>;
		hw,lcdkit-r_video_hh6 = <0x37c>;
		hw,lcdkit-r_video_lh6 = <0x300>;
		hw,lcdkit-color-temp-rectify-r = <0x8000>;
		hw,lcdkit-color-temp-rectify-g = <0x8000>;
		hw,lcdkit-color-temp-rectify-b = <0x8000>;
		hw,lcdkit-hiace-support = <0x01>;
		hw,lcdkit-panel-effect-support = <0x00>;
		hw,lcdkit-arsr1p-sharpness-support = <0x01>;
		hw,lcdkit-iglobal-hist-black-pos = <0x10>;
		hw,lcdkit-iglobal-hist-white-pos = <0xf0>;
		hw,lcdkit-iglobal-hist-black-weight = <0x33>;
		hw,lcdkit-iglobal-hist-white-weight = <0x33>;
		hw,lcdkit-iglobal-hist-zero-cut-ratio = <0x1e6>;
		hw,lcdkit-iglobal-hist-slope-cut-ratio = <0x19a>;
		hw,lcdkit-imax-lcd-luminance = <0x1f4>;
		hw,lcdkit-imin-lcd-luminance = <0x03>;
		hw,lcdkit-cfg-name = "/product/etc/display/effect/algorithm/hdr_engine.xml";
		hw,lcdkit-effect-support-mode = <0x10001>;
		hw,lcdkit-bl-support-mode = <0x00>;
		hw,lcdkit-bl-enhance = <0x00>;
		hw,lcdkit-bl-normal = <0x00>;
		hw,lcdkit-delay-af-rst-off = <0x0a>;
		hw,lcdkit-h-back-porch = <0x12>;
		hw,lcdkit-h-front-porch = <0x12>;
		hw,lcdkit-h-pulse-width = <0x04>;
		hw,lcdkit-v-back-porch = <0x1c>;
		hw,lcdkit-v-pulse-width = <0x3e>;
		hw,lcdkit-v-front-porch = <0x1c>;
		hw,lcdkit-h-sync-skew = <0x00>;
		hw,lcdkit-lcd-type = <0x03>;
		hw,lcdkit-panel-pt-test-support = <0x01>;
		hw,lcdkit-mipi-clk-config-support = <0x00>;
		hw,lcdkit-panel-hkadc-support = <0x00>;
		hw,lcdkit-bias-power-ctrl-mode = <0x10>;
		hw,lcdkit-iovcc-power-ctrl-mode = <0x01>;
		hw,lcdkit-vci-power-ctrl-mode = <0x01>;
		hw,lcdkit-id0-gpio = <0x83>;
		hw,lcdkit-id1-gpio = <0x00>;
		hw,lcdkit-reset-gpio = <0x1d>;
		hw,lcdkit-te-gpio = <0x10>;
		hw,lcdkit-vsp-gpio = <0x00>;
		hw,lcdkit-vsn-gpio = <0x00>;
		hw,lcdkit-iovcc-gpio = <0x00>;
		hw,lcdkit-vci-gpio = <0x00>;
		hw,lcdkit-bl-gpio = <0x00>;
		hw,lcdkit-err-flag-gpio = <0x0c>;
		hw,lcdkit-iovcc-on-is-need-reset = <0x00>;
		hw,lcdkit-vsn-on-is-need-reset = <0x01>;
		hw,lcdkit-reset-pull-high-flag = <0x00>;
		hw,lcdkit-lcdanalog-vcc = <0x2dc6c0>;
		hw,lcdkit-lcdio-vcc = <0x1c3a90>;
		hw,lcdkit-lcd-bias = <0x00>;
		hw,lcdkit-lcd-vsp = <0x00>;
		hw,lcdkit-lcd-vsn = <0x00>;
		hw,lcdkit-lcd-rst-first-high = <0x0a>;
		hw,lcdkit-lcd-rst-low = <0x01>;
		hw,lcdkit-lcd-rst-second-high = <0x14>;
		hw,lcdkit-delay-af-vci-on = <0x01>;
		hw,lcdkit-delay-af-iovcc-on = <0x00>;
		hw,lcdkit-delay-af-bias-on = <0x00>;
		hw,lcdkit-delay-af-vsp-on = <0x00>;
		hw,lcdkit-delay-af-vsn-on = <0x00>;
		hw,lcdkit-delay-af-lp11 = <0x01>;
		hw,lcdkit-delay-af-tp-reset = <0x00>;
		hw,lcdkit-tp-reset-before-lcd-reset = <0x00>;
		hw,lcdkit-delay-af-vsn-off = <0x00>;
		hw,lcdkit-delay-af-vsp-off = <0x00>;
		hw,lcdkit-delay-af-bias-off = <0x00>;
		hw,lcdkit-delay-af-vbat-off = <0x00>;
		hw,lcdkit-delay-af-iovcc-off = <0x00>;
		hw,lcdkit-delay-af-vci-off = <0x05>;
	};

	lcdkit_neo_tugl_lg_ea9151_5p99 {
		compatible = "lg_ea9151_5p99_1440plus_cmd";
		hw,lcdkit-panel-name = "LG_EA9151 5.99' CMD TFT 1440 x 2880";
		hw,lcdkit-panel-type = <0x02>;
		hw,lcdkit-panel-xres = <0x5a0>;
		hw,lcdkit-panel-yres = <0xb40>;
		hw,lcdkit-panel-width = <0x44>;
		hw,lcdkit-panel-height = <0x88>;
		hw,lcdkit-panel-on-command = <0x39 0x01 0x00 0x00 0x0a 0x00 0x03 0x7f 0x5a 0x5a 0x39 0x01 0x00 0x00 0x0a 0x00 0x03 0xf0 0x5a 0x5a 0x39 0x01 0x00 0x00 0x0a 0x00 0x03 0xf1 0x5a 0x5a 0x39 0x01 0x00 0x00 0x0a 0x00 0x03 0xf2 0x5a 0x5a 0x15 0x01 0x00 0x00 0x0a 0x00 0x02 0x02 0x01 0x15 0x01 0x00 0x00 0x0a 0x00 0x02 0x59 0x01 0x39 0x01 0x00 0x00 0x0a 0x00 0x03 0x51 0x00 0x00 0x15 0x01 0x00 0x00 0x0a 0x00 0x02 0x53 0x20 0x39 0x01 0x00 0x00 0x0a 0x00 0x06 0x57 0x20 0x80 0xfe 0x60 0x00 0x39 0x01 0x00 0x00 0x0a 0x00 0x05 0x2a 0x00 0x00 0x05 0x9f 0x39 0x01 0x00 0x00 0x0a 0x00 0x05 0x2b 0x00 0x00 0x0b 0x3f 0x0a 0x01 0x00 0x00 0x05 0x01 0x58 0x11 0x00 0x00 0x89 0x30 0x80 0x0b 0x40 0x05 0xa0 0x02 0xd0 0x02 0xd0 0x02 0xd0 0x02 0x00 0x02 0x68 0x00 0x20 0x4e 0xa8 0x00 0x0a 0x00 0x0c 0x00 0x23 0x00 0x1c 0x18 0x00 0x10 0xf0 0x03 0x0c 0x20 0x00 0x06 0x0b 0x0b 0x33 0x0e 0x1c 0x2a 0x38 0x46 0x54 0x62 0x69 0x70 0x77 0x79 0x7b 0x7d 0x7e 0x01 0x02 0x01 0x00 0x09 0x40 0x09 0xbe 0x19 0xfc 0x19 0xfa 0x19 0xf8 0x1a 0x38 0x1a 0x78 0x1a 0xb6 0x2a 0xf6 0x2b 0x34 0x2b 0x74 0x3b 0x74 0x6b 0xf4 0x15 0x01 0x00 0x00 0x0a 0x00 0x02 0x35 0x01 0x05 0x01 0x00 0x00 0x78 0x01 0x02 0x11 0x00 0x15 0x01 0x00 0x00 0x0a 0x00 0x02 0xb0 0x04 0x15 0x01 0x00 0x00 0x0a 0x00 0x02 0xd2 0x20 0x15 0x01 0x00 0x00 0x0a 0x00 0x02 0xb2 0x05 0x05 0x01 0x00 0x00 0x28 0x01 0x02 0x29 0x00>;
		hw,lcdkit-panel-on-command-state = "dsi_lp_mode";
		hw,lcdkit-panel-display-on-command = <0x05 0x01 0x00 0x00 0x78 0x00 0x02 0x29 0x00>;
		hw,lcdkit-panel-off-command = <0x05 0x01 0x00 0x00 0x0a 0x01 0x02 0x28 0x00 0x05 0x01 0x00 0x00 0x64 0x01 0x02 0x10 0x00>;
		hw,lcdkit-panel-off-command-state = "dsi_lp_mode";
		hw,lcdkit-panel-backlight-command = <0x39 0x01 0x00 0x00 0x00 0x00 0x03 0x51 0x00 0x00>;
		hw,lcdkit-panel-backlight-command-state = "dsi_lp_mode";
		hw,lcdkit-panel-cabc-support = <0x00>;
		hw,lcdkit-panel-rgbw-support = <0x00>;
		hw,lcdkit-panel-display-on-effect-command = <0x15 0x01 0x00 0x00 0x0a 0x00 0x02 0xff 0x23 0x15 0x01 0x00 0x00 0x0a 0x00 0x02 0xfb 0x01 0x15 0x01 0x00 0x00 0x0a 0x00 0x02 0x00 0x02 0x15 0x01 0x00 0x00 0x0a 0x00 0x02 0x01 0x84 0x15 0x01 0x00 0x00 0x0a 0x00 0x02 0x05 0x24 0x15 0x01 0x00 0x00 0x0a 0x00 0x02 0x19 0x00 0x15 0x01 0x00 0x00 0x0a 0x00 0x02 0x1a 0x04 0x15 0x01 0x00 0x00 0x0a 0x00 0x02 0x1b 0x08 0x15 0x01 0x00 0x00 0x0a 0x00 0x02 0x1c 0x0c 0x15 0x01 0x00 0x00 0x0a 0x00 0x02 0x1d 0x10 0x15 0x01 0x00 0x00 0x0a 0x00 0x02 0x1e 0x14 0x15 0x01 0x00 0x00 0x0a 0x00 0x02 0x1f 0x18 0x15 0x01 0x00 0x00 0x0a 0x00 0x02 0x20 0x1c 0x15 0x01 0x00 0x00 0x0a 0x00 0x02 0x21 0x20 0x15 0x01 0x00 0x00 0x0a 0x00 0x02 0x22 0x24 0x15 0x01 0x00 0x00 0x0a 0x00 0x02 0x23 0x28 0x15 0x01 0x00 0x00 0x0a 0x00 0x02 0x24 0x2c 0x15 0x01 0x00 0x00 0x0a 0x00 0x02 0x25 0x30 0x15 0x01 0x00 0x00 0x0a 0x00 0x02 0x26 0x34 0x15 0x01 0x00 0x00 0x0a 0x00 0x02 0x27 0x38 0x15 0x01 0x00 0x00 0x0a 0x00 0x02 0x28 0x3c 0x15 0x01 0x00 0x00 0x0a 0x00 0x02 0x29 0x24 0x15 0x01 0x00 0x00 0x0a 0x00 0x02 0x2b 0x3d 0x15 0x01 0x00 0x00 0x0a 0x00 0x02 0x30 0xff 0x15 0x01 0x00 0x00 0x0a 0x00 0x02 0x31 0xfd 0x15 0x01 0x00 0x00 0x0a 0x00 0x02 0x32 0xfb 0x15 0x01 0x00 0x00 0x0a 0x00 0x02 0x33 0xf9 0x15 0x01 0x00 0x00 0x0a 0x00 0x02 0x34 0xf7 0x15 0x01 0x00 0x00 0x0a 0x00 0x02 0x35 0xf5 0x15 0x01 0x00 0x00 0x0a 0x00 0x02 0x36 0xf3 0x15 0x01 0x00 0x00 0x0a 0x00 0x02 0x37 0xf1 0x15 0x01 0x00 0x00 0x0a 0x00 0x02 0x38 0xef 0x15 0x01 0x00 0x00 0x0a 0x00 0x02 0x39 0xed 0x15 0x01 0x00 0x00 0x0a 0x00 0x02 0x3a 0xeb 0x15 0x01 0x00 0x00 0x0a 0x00 0x02 0x3b 0xe9 0x15 0x01 0x00 0x00 0x0a 0x00 0x02 0x3d 0xe7 0x15 0x01 0x00 0x00 0x0a 0x00 0x02 0x3f 0xe5 0x15 0x01 0x00 0x00 0x0a 0x00 0x02 0x40 0xe3 0x15 0x01 0x00 0x00 0x0a 0x00 0x02 0x41 0xe0 0x15 0x01 0x00 0x00 0x0a 0x00 0x02 0x45 0xff 0x15 0x01 0x00 0x00 0x0a 0x00 0x02 0x46 0xfd 0x15 0x01 0x00 0x00 0x0a 0x00 0x02 0x47 0xfb 0x15 0x01 0x00 0x00 0x0a 0x00 0x02 0x48 0xf9 0x15 0x01 0x00 0x00 0x0a 0x00 0x02 0x49 0xf7 0x15 0x01 0x00 0x00 0x0a 0x00 0x02 0x4a 0xf5 0x15 0x01 0x00 0x00 0x0a 0x00 0x02 0x4b 0xf3 0x15 0x01 0x00 0x00 0x0a 0x00 0x02 0x4c 0xf1 0x15 0x01 0x00 0x00 0x0a 0x00 0x02 0x4d 0xef 0x15 0x01 0x00 0x00 0x0a 0x00 0x02 0x4e 0xed 0x15 0x01 0x00 0x00 0x0a 0x00 0x02 0x4f 0xeb 0x15 0x01 0x00 0x00 0x0a 0x00 0x02 0x50 0xe9 0x15 0x01 0x00 0x00 0x0a 0x00 0x02 0x51 0xe7 0x15 0x01 0x00 0x00 0x0a 0x00 0x02 0x52 0xe5 0x15 0x01 0x00 0x00 0x0a 0x00 0x02 0x53 0xe3 0x15 0x01 0x00 0x00 0x0a 0x00 0x02 0x54 0xe0 0x15 0x01 0x00 0x00 0x0a 0x00 0x02 0x58 0xff 0x15 0x01 0x00 0x00 0x0a 0x00 0x02 0x59 0xf8 0x15 0x01 0x00 0x00 0x0a 0x00 0x02 0x5a 0xf1 0x15 0x01 0x00 0x00 0x0a 0x00 0x02 0x5b 0xea 0x15 0x01 0x00 0x00 0x0a 0x00 0x02 0x5c 0xe3 0x15 0x01 0x00 0x00 0x0a 0x00 0x02 0x5d 0xdc 0x15 0x01 0x00 0x00 0x0a 0x00 0x02 0x5e 0xd5 0x15 0x01 0x00 0x00 0x0a 0x00 0x02 0x5f 0xce 0x15 0x01 0x00 0x00 0x0a 0x00 0x02 0x60 0xc7 0x15 0x01 0x00 0x00 0x0a 0x00 0x02 0x61 0xc0 0x15 0x01 0x00 0x00 0x0a 0x00 0x02 0x62 0xb9 0x15 0x01 0x00 0x00 0x0a 0x00 0x02 0x63 0xb2 0x15 0x01 0x00 0x00 0x0a 0x00 0x02 0x64 0xab 0x15 0x01 0x00 0x00 0x0a 0x00 0x02 0x65 0xa4 0x15 0x01 0x00 0x00 0x0a 0x00 0x02 0x66 0x9d 0x15 0x01 0x00 0x00 0x0a 0x00 0x02 0x67 0x96 0x15 0x01 0x00 0x00 0x0a 0x00 0x02 0xff 0x10 0x15 0x01 0x00 0x00 0x0a 0x00 0x02 0xff 0x22 0x15 0x01 0x00 0x00 0x0a 0x00 0x02 0xfb 0x01 0x15 0x01 0x00 0x00 0x0a 0x00 0x02 0x00 0x40 0x15 0x01 0x00 0x00 0x0a 0x00 0x02 0x01 0x54 0x15 0x01 0x00 0x00 0x0a 0x00 0x02 0x02 0x5a 0x15 0x01 0x00 0x00 0x0a 0x00 0x02 0x03 0x60 0x15 0x01 0x00 0x00 0x0a 0x00 0x02 0x04 0x66 0x15 0x01 0x00 0x00 0x0a 0x00 0x02 0x05 0x6a 0x15 0x01 0x00 0x00 0x0a 0x00 0x02 0x06 0x6c 0x15 0x01 0x00 0x00 0x0a 0x00 0x02 0x07 0x6c 0x15 0x01 0x00 0x00 0x0a 0x00 0x02 0x08 0x68 0x15 0x01 0x00 0x00 0x0a 0x00 0x02 0x09 0x62 0x15 0x01 0x00 0x00 0x0a 0x00 0x02 0x0a 0x5b 0x15 0x01 0x00 0x00 0x0a 0x00 0x02 0x0b 0x53 0x15 0x01 0x00 0x00 0x0a 0x00 0x02 0x0c 0x4d 0x15 0x01 0x00 0x00 0x0a 0x00 0x02 0x0d 0x43 0x15 0x01 0x00 0x00 0x0a 0x00 0x02 0x0e 0x44 0x15 0x01 0x00 0x00 0x0a 0x00 0x02 0x0f 0x41 0x15 0x01 0x00 0x00 0x0a 0x00 0x02 0x10 0x40 0x15 0x01 0x00 0x00 0x0a 0x00 0x02 0x11 0x50 0x15 0x01 0x00 0x00 0x0a 0x00 0x02 0x12 0x60 0x15 0x01 0x00 0x00 0x0a 0x00 0x02 0x13 0x70 0x15 0x01 0x00 0x00 0x0a 0x00 0x02 0x14 0x58 0x15 0x01 0x00 0x00 0x0a 0x00 0x02 0x15 0x68 0x15 0x01 0x00 0x00 0x0a 0x00 0x02 0x16 0x78 0x15 0x01 0x00 0x00 0x0a 0x00 0x02 0x17 0x00 0x15 0x01 0x00 0x00 0x0a 0x00 0x02 0x18 0x40 0x15 0x01 0x00 0x00 0x0a 0x00 0x02 0x19 0x40 0x15 0x01 0x00 0x00 0x0a 0x00 0x02 0x1a 0x40 0x15 0x01 0x00 0x00 0x0a 0x00 0x02 0x1b 0x40 0x15 0x01 0x00 0x00 0x0a 0x00 0x02 0x1c 0x40 0x15 0x01 0x00 0x00 0x0a 0x00 0x02 0x1d 0x40 0x15 0x01 0x00 0x00 0x0a 0x00 0x02 0x1e 0x40 0x15 0x01 0x00 0x00 0x0a 0x00 0x02 0x1f 0x40 0x15 0x01 0x00 0x00 0x0a 0x00 0x02 0x20 0x40 0x15 0x01 0x00 0x00 0x0a 0x00 0x02 0x21 0x45 0x15 0x01 0x00 0x00 0x0a 0x00 0x02 0x22 0x49 0x15 0x01 0x00 0x00 0x0a 0x00 0x02 0x23 0x4c 0x15 0x01 0x00 0x00 0x0a 0x00 0x02 0x24 0x4b 0x15 0x01 0x00 0x00 0x0a 0x00 0x02 0x25 0x48 0x15 0x01 0x00 0x00 0x0a 0x00 0x02 0x26 0x44 0x15 0x01 0x00 0x00 0x0a 0x00 0x02 0x27 0x41 0x15 0x01 0x00 0x00 0x0a 0x00 0x02 0x28 0x40 0x15 0x01 0x00 0x00 0x0a 0x00 0x02 0x2d 0x00 0x15 0x01 0x00 0x00 0x0a 0x00 0x02 0x2f 0x40 0x15 0x01 0x00 0x00 0x0a 0x00 0x02 0x30 0x40 0x15 0x01 0x00 0x00 0x0a 0x00 0x02 0x31 0x3e 0x15 0x01 0x00 0x00 0x0a 0x00 0x02 0x32 0x3e 0x15 0x01 0x00 0x00 0x0a 0x00 0x02 0x33 0x3b 0x15 0x01 0x00 0x00 0x0a 0x00 0x02 0x34 0x3a 0x15 0x01 0x00 0x00 0x0a 0x00 0x02 0x35 0x3a 0x15 0x01 0x00 0x00 0x0a 0x00 0x02 0x36 0x3a 0x15 0x01 0x00 0x00 0x0a 0x00 0x02 0x37 0x3a 0x15 0x01 0x00 0x00 0x0a 0x00 0x02 0x38 0x3b 0x15 0x01 0x00 0x00 0x0a 0x00 0x02 0x39 0x3c 0x15 0x01 0x00 0x00 0x0a 0x00 0x02 0x3a 0x3e 0x15 0x01 0x00 0x00 0x0a 0x00 0x02 0x3b 0x3f 0x15 0x01 0x00 0x00 0x0a 0x00 0x02 0x3d 0x40 0x15 0x01 0x00 0x00 0x0a 0x00 0x02 0x3f 0x40 0x15 0x01 0x00 0x00 0x0a 0x00 0x02 0x40 0x40 0x15 0x01 0x00 0x00 0x0a 0x00 0x02 0x41 0x40 0x15 0x01 0x00 0x00 0x0a 0x00 0x02 0x42 0x40 0x15 0x01 0x00 0x00 0x0a 0x00 0x02 0x43 0x40 0x15 0x01 0x00 0x00 0x0a 0x00 0x02 0x44 0x3e 0x15 0x01 0x00 0x00 0x0a 0x00 0x02 0x45 0x3e 0x15 0x01 0x00 0x00 0x0a 0x00 0x02 0x46 0x3b 0x15 0x01 0x00 0x00 0x0a 0x00 0x02 0x47 0x3a 0x15 0x01 0x00 0x00 0x0a 0x00 0x02 0x48 0x3a 0x15 0x01 0x00 0x00 0x0a 0x00 0x02 0x49 0x3a 0x15 0x01 0x00 0x00 0x0a 0x00 0x02 0x4a 0x3a 0x15 0x01 0x00 0x00 0x0a 0x00 0x02 0x4b 0x3a 0x15 0x01 0x00 0x00 0x0a 0x00 0x02 0x4c 0x3a 0x15 0x01 0x00 0x00 0x0a 0x00 0x02 0x4d 0x3a 0x15 0x01 0x00 0x00 0x0a 0x00 0x02 0x4e 0x3a 0x15 0x01 0x00 0x00 0x0a 0x00 0x02 0x4f 0x3b 0x15 0x01 0x00 0x00 0x0a 0x00 0x02 0x50 0x3d 0x15 0x01 0x00 0x00 0x0a 0x00 0x02 0x51 0x3f 0x15 0x01 0x00 0x00 0x0a 0x00 0x02 0x52 0x40 0x15 0x01 0x00 0x00 0x0a 0x00 0x02 0x53 0x77 0x15 0x01 0x00 0x00 0x0a 0x00 0x02 0x54 0x00 0x15 0x01 0x00 0x00 0x0a 0x00 0x02 0x55 0x88 0x15 0x01 0x00 0x00 0x0a 0x00 0x02 0x56 0x77 0x15 0x01 0x00 0x00 0x0a 0x00 0x02 0x58 0xc0 0x15 0x01 0x00 0x00 0x0a 0x00 0x02 0x59 0xc0 0x15 0x01 0x00 0x00 0x0a 0x00 0x02 0x5a 0x40 0x15 0x01 0x00 0x00 0x0a 0x00 0x02 0x5b 0x40 0x15 0x01 0x00 0x00 0x0a 0x00 0x02 0x5c 0x40 0x15 0x01 0x00 0x00 0x0a 0x00 0x02 0x5d 0x40 0x15 0x01 0x00 0x00 0x0a 0x00 0x02 0x5e 0x40 0x15 0x01 0x00 0x00 0x0a 0x00 0x02 0x5f 0x40 0x15 0x01 0x00 0x00 0x0a 0x00 0x02 0x60 0x40 0x15 0x01 0x00 0x00 0x0a 0x00 0x02 0x61 0x40 0x15 0x01 0x00 0x00 0x0a 0x00 0x02 0x62 0x40 0x15 0x01 0x00 0x00 0x0a 0x00 0x02 0x63 0x40 0x15 0x01 0x00 0x00 0x0a 0x00 0x02 0x64 0x40 0x15 0x01 0x00 0x00 0x0a 0x00 0x02 0x65 0x40 0x15 0x01 0x00 0x00 0x0a 0x00 0x02 0x66 0x40 0x15 0x01 0x00 0x00 0x0a 0x00 0x02 0x67 0x40 0x15 0x01 0x00 0x00 0x0a 0x00 0x02 0x68 0x40 0x15 0x01 0x00 0x00 0x0a 0x00 0x02 0x69 0x40 0x15 0x01 0x00 0x00 0x0a 0x00 0x02 0x6a 0x40 0x15 0x01 0x00 0x00 0x0a 0x00 0x02 0x6b 0x40 0x15 0x01 0x00 0x00 0x0a 0x00 0x02 0x6c 0x40 0x15 0x01 0x00 0x00 0x0a 0x00 0x02 0x6d 0x40 0x15 0x01 0x00 0x00 0x0a 0x00 0x02 0x6e 0x40 0x15 0x01 0x00 0x00 0x0a 0x00 0x02 0x6f 0x40 0x15 0x01 0x00 0x00 0x0a 0x00 0x02 0x70 0x0c 0x15 0x01 0x00 0x00 0x0a 0x00 0x02 0x71 0x00 0x15 0x01 0x00 0x00 0x0a 0x00 0x02 0x72 0x00 0x15 0x01 0x00 0x00 0x0a 0x00 0x02 0x73 0x00 0x15 0x01 0x00 0x00 0x0a 0x00 0x02 0x74 0x03 0x15 0x01 0x00 0x00 0x0a 0x00 0x02 0x75 0x0c 0x15 0x01 0x00 0x00 0x0a 0x00 0x02 0x76 0x03 0x15 0x01 0x00 0x00 0x0a 0x00 0x02 0x77 0x09 0x15 0x01 0x00 0x00 0x0a 0x00 0x02 0x78 0x0f 0x15 0x01 0x00 0x00 0x0a 0x00 0x02 0x79 0x68 0x15 0x01 0x00 0x00 0x0a 0x00 0x02 0x7a 0x88 0x15 0x01 0x00 0x00 0x0a 0x00 0x02 0x83 0x00 0x15 0x01 0x00 0x00 0x0a 0x00 0x02 0x84 0x28 0x15 0x01 0x00 0x00 0x0a 0x00 0x02 0x85 0x5f 0x15 0x01 0x00 0x00 0x0a 0x00 0x02 0x86 0x50 0x15 0x01 0x00 0x00 0x0a 0x00 0x02 0x87 0x22 0x15 0x01 0x00 0x00 0x0a 0x00 0x02 0x88 0x40 0x15 0x01 0x00 0x00 0x0a 0x00 0x02 0x89 0x4e 0x15 0x01 0x00 0x00 0x0a 0x00 0x02 0x8a 0x4f 0x15 0x01 0x00 0x00 0x0a 0x00 0x02 0x8b 0x50 0x15 0x01 0x00 0x00 0x0a 0x00 0x02 0x8c 0x50 0x15 0x01 0x00 0x00 0x0a 0x00 0x02 0x8d 0x40 0x15 0x01 0x00 0x00 0x0a 0x00 0x02 0x8e 0x40 0x15 0x01 0x00 0x00 0x0a 0x00 0x02 0x8f 0x00 0x15 0x01 0x00 0x00 0x0a 0x00 0x02 0x90 0x1e 0x15 0x01 0x00 0x00 0x0a 0x00 0x02 0x91 0x23 0x15 0x01 0x00 0x00 0x0a 0x00 0x02 0x92 0x3a 0x15 0x01 0x00 0x00 0x0a 0x00 0x02 0x93 0x40 0x15 0x01 0x00 0x00 0x0a 0x00 0x02 0x94 0x40 0x15 0x01 0x00 0x00 0x0a 0x00 0x02 0x95 0x40 0x15 0x01 0x00 0x00 0x0a 0x00 0x02 0x96 0x49 0x15 0x01 0x00 0x00 0x0a 0x00 0x02 0x97 0x49 0x15 0x01 0x00 0x00 0x0a 0x00 0x02 0x98 0x43 0x15 0x01 0x00 0x00 0x0a 0x00 0x02 0x99 0x43 0x15 0x01 0x00 0x00 0x0a 0x00 0x02 0x9a 0x3c 0x15 0x01 0x00 0x00 0x0a 0x00 0x02 0x9b 0x40 0x15 0x01 0x00 0x00 0x0a 0x00 0x02 0x9c 0x40 0x15 0x01 0x00 0x00 0x0a 0x00 0x02 0x9d 0x40 0x15 0x01 0x00 0x00 0x0a 0x00 0x02 0x9e 0x4c 0x15 0x01 0x00 0x00 0x0a 0x00 0x02 0x9f 0x4d 0x15 0x01 0x00 0x00 0x0a 0x00 0x02 0xa0 0x4e 0x15 0x01 0x00 0x00 0x0a 0x00 0x02 0xa2 0x20 0x15 0x01 0x00 0x00 0x0a 0x00 0x02 0xb3 0x00 0x15 0x01 0x00 0x00 0x0a 0x00 0x02 0xb7 0x00 0x15 0x01 0x00 0x00 0x0a 0x00 0x02 0xb8 0x00 0x15 0x01 0x00 0x00 0x0a 0x00 0x02 0xff 0x10 0x15 0x01 0x00 0x00 0x0a 0x00 0x02 0x53 0x24 0x15 0x01 0x00 0x00 0x0a 0x00 0x02 0x55 0x81>;
		hw,lcdkit-panel-display-on-effect-support = <0x00>;
		hw,lcdkit-panel-ce-off-command;
		hw,lcdkit-panel-ce-srgb-command;
		hw,lcdkit-panel-ce-user-command;
		hw,lcdkit-panel-ce-vivid-command;
		hw,lcdkit-panel-ce-support = <0x00>;
		hw,lcdkit-panel-version-support = <0x00>;
		hw,lcdkit-panel-otp-support = <0x00>;
		hw,lcdkit-panel-inversion-support = <0x00>;
		hw,lcdkit-panel-scan-support = <0x00>;
		hw,lcdkit-panel-display-region-command = <0x39 0x01 0x00 0x00 0x05 0x00 0x05 0x2a 0x00 0x00 0x05 0x9f 0x39 0x01 0x00 0x00 0x05 0x00 0x05 0x2b 0x00 0x00 0x0b 0x3f>;
		hw,lcdkit-panel-display-region-command-state = "dsi_lp_mode";
		hw,lcdkit-panel-display-region-support = <0x01>;
		hw,lcdkit-panel-checksum-support = <0x00>;
		hw,lcdkit-panel-esd-reg-command = <0x06 0x01 0x00 0x00 0x0a 0x00 0x01 0x0a 0x06 0x01 0x00 0x00 0x0a 0x00 0x01 0x0e 0x06 0x01 0x00 0x00 0x0a 0x00 0x01 0x0f>;
		hw,lcdkit-panel-esd-reg-command-state = "dsi_lp_mode";
		hw,lcdkit-panel-esd-value = <0x9c 0xc0 0xc0>;
		hw,lcdkit-panel-esd-support = <0x01>;
		hw,lcdkit-panel-check-reg-command = <0x06 0x01 0x00 0x00 0x0a 0x00 0x01 0x0a>;
		hw,lcdkit-panel-check-reg-value = <0x9c>;
		hw,lcdkit-panel-check-reg-command-state = "dsi_lp_mode";
		hw,lcdkit-panel-check-reg-support = <0x00>;
		hw,lcdkit-panel-brightness-color-uniform-support = <0x00>;
		hw,lcdkit-panel-dynamic-gamma-support = <0x01>;
		hw,lcdkit-panel-mipi-detect-support = <0x00>;
		hw,lcdkit-panel-dynamic-sram-check-support = <0x00>;
		hw,lcdkit-panel-fps-updt-support = <0x00>;
		hw,lcdkit-panel-fps-func-switch = <0x00>;
		hw,lcdkit-panel-check-reg-on-support = <0x00>;
		hw,lcdkit-panel-fps-tscall-support = <0x00>;
		hw,lcdkit-panel-dis-on-cmds-delay-margin-support = <0x00>;
		hw,lcdkit-panel-snd-cmd-before-frame-support = <0x00>;
		hw,lcdkit-panel-ts-resume-ctrl-mode = <0x00>;
		hw,lcdkit-panel-dis-on-cmds-delay-margin-time = <0x00>;
		hw,lcdkit-panel-lptohs-mipi-check-support = <0x00>;
		hw,lcdkit-panel-acl-ctrl-support = <0x00>;
		hw,lcdkit-panel-acl-off-command = <0x15 0x01 0x00 0x00 0x0a 0x00 0x02 0x55 0x00>;
		hw,lcdkit-panel-acl-off-command-state = "dsi_lp_mode";
		hw,lcdkit-panel-acl-low-command = <0x15 0x01 0x00 0x00 0x0a 0x00 0x02 0x55 0x03>;
		hw,lcdkit-panel-acl-low-command-state = "dsi_lp_mode";
		hw,lcdkit-panel-acl-middle-command = <0x15 0x01 0x00 0x00 0x0a 0x00 0x02 0x55 0x02>;
		hw,lcdkit-panel-acl-middle-command-state = "dsi_lp_mode";
		hw,lcdkit-panel-acl-high-command = <0x15 0x01 0x00 0x00 0x0a 0x00 0x02 0x55 0x01>;
		hw,lcdkit-panel-acl-high-command-state = "dsi_lp_mode";
		hw,lcdkit-panel-hbm-ctrl-support = <0x00>;
		hw,lcdkit-panel-vr-support = <0x00>;
		hw,lcdkit-panel-current-detect-support = <0x00>;
		hw,lcdkit-panel-lv-detect-support = <0x00>;
		hw,lcdkit-reset-shutdown-later = <0x01>;
		hw,lcdkit-panel-pcd-errflag-check-support = <0x01>;
		hw,lcdkit-panel-pt-ulps-support = <0x00>;
		hw,lcdkit-panel-aod-support = <0x00>;
		hw,lcdkit-panel-enter-aod-command = <0x39 0x01 0x00 0x00 0x0a 0x00 0x03 0x7f 0x5a 0x5a 0x39 0x01 0x00 0x00 0x0a 0x00 0x03 0xf0 0x5a 0x5a 0x39 0x01 0x00 0x00 0x0a 0x00 0x03 0xf1 0x5a 0x5a 0x39 0x01 0x00 0x00 0x0a 0x00 0x03 0xf2 0x5a 0x5a 0x05 0x01 0x00 0x00 0x0a 0x00 0x01 0x28 0x15 0x01 0x00 0x00 0x0a 0x00 0x02 0xb0 0x06 0x39 0x01 0x00 0x00 0x0a 0x00 0x05 0xc2 0x23 0x00 0x09 0x69 0x15 0x01 0x00 0x00 0x0a 0x00 0x02 0x5a 0x00 0x15 0x01 0x00 0x00 0x0a 0x00 0x02 0xb0 0x0f 0x15 0x01 0x00 0x00 0x0a 0x00 0x02 0xe1 0xc0 0x05 0x01 0x00 0x00 0x0a 0x01 0x01 0x39 0x05 0x01 0x00 0x00 0x0a 0x00 0x01 0x29 0x39 0x01 0x00 0x00 0x0a 0x00 0x05 0x30 0x00 0x00 0x0b 0x3f 0x05 0x01 0x00 0x00 0x0a 0x00 0x01 0x12>;
		hw,lcdkit-panel-aod-low-brightness-command = <0x39 0x01 0x00 0x00 0x0a 0x00 0x03 0x51 0x00 0x01>;
		hw,lcdkit-panel-exit-aod-command = <0x39 0x01 0x00 0x00 0x0a 0x00 0x03 0x7f 0x5a 0x5a 0x39 0x01 0x00 0x00 0x0a 0x00 0x03 0xf0 0x5a 0x5a 0x39 0x01 0x00 0x00 0x0a 0x00 0x03 0xf1 0x5a 0x5a 0x39 0x01 0x00 0x00 0x0a 0x00 0x03 0xf2 0x5a 0x5a 0x05 0x01 0x00 0x00 0x0a 0x00 0x01 0x28 0x15 0x01 0x00 0x00 0x0a 0x00 0x02 0xb0 0x06 0x39 0x01 0x00 0x00 0x0a 0x00 0x05 0xc2 0x23 0x00 0x12 0x65 0x15 0x01 0x00 0x00 0x0a 0x00 0x02 0xb0 0x0f 0x15 0x01 0x00 0x00 0x0a 0x00 0x02 0xe1 0xc0 0x39 0x01 0x00 0x00 0x0a 0x00 0x03 0x51 0x00 0x00 0x05 0x01 0x00 0x00 0x0a 0x00 0x01 0x13 0x05 0x01 0x00 0x00 0x0a 0x01 0x01 0x38 0x05 0x01 0x00 0x00 0x0a 0x00 0x01 0x29>;
		hw,lcdkit-panel-enter-aod-command-state;
		hw,lcdkit-panel-aod-low-brightness-command-state;
		hw,lcdkit-panel-exit-aod-command-state;
		hw,lcdkit-panel-orientation = <0x01>;
		hw,lcdkit-panel-bpp = <0x00>;
		hw,lcdkit-panel-bgrfmt = <0x00>;
		hw,lcdkit-panel-bl-type = <0x08>;
		hw,lcdkit-panel-blmin = <0x04>;
		hw,lcdkit-panel-blmax = <0x3ff>;
		hw,lcdkit-mask-delay-time-before-fp = <0x411a>;
		hw,lcdkit-mask-delay-time-after-fp = <0x411a>;
		hw,lcdkit-tp-reset-gpio = <0x00>;
		hw,lcdkit-panel-bl-def = <0x199>;
		hw,lcdkit-panel-bl-maxnit = <0x212>;
		hw,lcdkit-panel-getblmaxnit-type = <0x00>;
		hw,lcdkit-panel-cmd-type = <0x10>;
		hw,lcdkit-panel-ifbctype = <0x09>;
		hw,lcdkit-panel-ifbc-vesa3x-set = <0x01>;
		hw,lcdkit-panel-frc-enable = <0x00>;
		hw,lcdkit-panel-esd-skip-mipi-check = <0x01>;
		hw,lcdkit-panel-pxl-clk = <0x12c>;
		hw,lcdkit-panel-pxl-clk-div = <0x03>;
		hw,lcdkit-panel-tp-resume-nosync = <0x01>;
		hw,lcdkit-panel-display-on-in-backlight = <0x00>;
		hw,lcdkit-panel-display-on-new-seq = <0x00>;
		hw,lcdkit-panel-dirt-updt-support = <0x01>;
		hw,lcdkit-is-hostprocessing = <0x00>;
		hw,lcdkit-host-info-all-in-ddic = <0x00>;
		hw,lcdkit-panel-dsi-upt-support = <0x01>;
		hw,mipiclk-updt-support-new = <0x00>;
		hw,lcdkit-panel-vsyn-ctr-type = <0x07>;
		hw,lcdkit-panel-bl-pwm-preci-no-convert = <0x00>;
		hw,lcdkit-panel-bl-pwm-preci-type = <0x02>;
		hw,lcdkit-panel-bl-ic-ctrl-type = <0x09>;
		hw,lcdkit-panel-fps-updt-only = <0x00>;
		hw,lcdkit-panel-step-support = <0x01>;
		hw,lcdkit-ldi-hsync-plr = <0x00>;
		hw,lcdkit-ldi-vsync-plr = <0x00>;
		hw,lcdkit-ldi-pixel-clk-plr = <0x00>;
		hw,lcdkit-ldi-data-en-plr = <0x00>;
		hw,lcdkit-ldi-dpi-a-overlap-size = <0x00>;
		hw,lcdkit-ldi-dpi-b-overlap-size = <0x00>;
		hw,lcdkit-sbl-stren-limit = <0x80>;
		hw,lcdkit-sbl-cal-a = <0x3c>;
		hw,lcdkit-sbl-cal-b = <0x5f>;
		hw,lcdkit-sbl-cal-c = <0x05>;
		hw,lcdkit-sbl-cal-d = <0x01>;
		hw,lcdkit-sbl-tf-ctl = <0x05>;
		hw,lcdkit-sbl-bl-min = <0x1e0>;
		hw,lcdkit-sbl-bl-max = <0x1000>;
		hw,lcdkit-sbl-bl-scale = <0xff>;
		hw,lcdkit-sbl-am-light-min = <0x0e>;
		hw,lcdkit-sbl-filter-a = <0x6ca>;
		hw,lcdkit-sbl-filter-b = <0x06>;
		hw,lcdkit-sbl-logo-left = <0x00>;
		hw,lcdkit-sbl-logo-top = <0x00>;
		hw,lcdkit-sbl-variance-intensity-space = <0x91>;
		hw,lcdkit-sbl-slope-max = <0x36>;
		hw,lcdkit-sbl-slope-min = <0xa0>;
		hw,lcdkit-mipi-lane-nums = <0x03>;
		hw,lcdkit-mipi-color-mode = <0x05>;
		hw,lcdkit-mipi-vc = <0x00>;
		hw,lcdkit-mipi-dsi-bit-clk = <0x1e0>;
		hw,lcdkit-mipi-burst-mode = <0x02>;
		hw,lcdkit-mipi-max-esc-clk = <0x0a>;
		hw,lcdkit-mipi-dsi-bit-clk-val-a = <0x1ea>;
		hw,lcdkit-mipi-dsi-bit-clk-val-b = <0x1e0>;
		hw,lcdkit-mipi-dsi-bit-clk-val-c = <0x00>;
		hw,lcdkit-mipi-dsi-bit-clk-val-d = <0x00>;
		hw,lcdkit-mipi-dsi-bit-clk-val-e = <0x00>;
		hw,lcdkit-mipi-dsi-bit-clk-upt = <0x1e0>;
		hw,lcdkit-mipi-rg-vcm-adjust = <0x00>;
		hw,lcdkit-mipi-non-continue-enable = <0x01>;
		hw,lcdkit-mipi-clk-post-adjust = <0xd7>;
		hw,lcdkit-mipi-clk-pre-adjust = <0x00>;
		hw,lcdkit-mipi-clk-t-hs-prepare-adjust = <0x2b>;
		hw,lcdkit-mipi-clk-t-lpx-adjust = <0x00>;
		hw,lcdkit-mipi-clk-t-hs-trail-adjust = <0x00>;
		hw,lcdkit-mipi-clk-t-hs-exit-adjust = <0x00>;
		hw,lcdkit-mipi-clk-t-hs-zero-adjust = <0x00>;
		hw,lcdkit-mipi-data-t-hs-trail-adjust = <0x02>;
		hw,lcdkit-mipi-data-t-hs-prepare-adjust = <0x0e>;
		hw,lcdkit-mipi-data-t-hs-zero-adjust = <0x3c>;
		hw,lcdkit-mipi-data-t-lpx-adjust = <0xff50>;
		hw,lcdkit-mipi-phy-mode = <0x00>;
		hw,lcdkit-mipi-eotp-disable-flag = <0x00>;
		hw,lcdkit-blpwm-input-disable = <0x00>;
		hw,lcdkit-dirt-left-align = <0x5a0>;
		hw,lcdkit-dirt-right-align = <0x5a0>;
		hw,lcdkit-dirt-top-align = <0x2d0>;
		hw,lcdkit-dirt-bott-align = <0x2d0>;
		hw,lcdkit-dirt-width-align = <0xffff>;
		hw,lcdkit-dirt-height-align = <0xffff>;
		hw,lcdkit-dirt-width-min = <0xffff>;
		hw,lcdkit-dirt-height-min = <0xffff>;
		hw,lcdkit-dirt-top-start = <0xffff>;
		hw,lcdkit-dirt-bott-start = <0xffff>;
		hw,lcdkit-bl-byte-order = <0x00>;
		hw,lcdkit-iovcc-before-vci-flag = <0x01>;
		pinctrl-names = "default", "idle";
		hw,lcdkit-sbl-support = <0x00>;
		hw,lcdkit-gamma-support = <0x01>;
		hw,lcdkit-gmp-support = <0x01>;
		hw,lcdkit-color-temp-support = <0x01>;
		hw,lcdkit-color-temp-rectify-support = <0x00>;
		hw,lcdkit-comform-mode-support = <0x01>;
		hw,lcdkit-cinema-mode-support = <0x00>;
		hw,lcdkit-prefix-sharp-two-d-support = <0x01>;
		hw,lcdkit-xcc-support = <0x01>;
		hw,lcdkit-prefix-ce-support = <0x00>;
		hw,lcdkit-prefix-sharp-one-d-support = <0x00>;
		hw,lcdkit-acm-support = <0x00>;
		hw,lcdkit-smart-color-mode-support = <0x00>;
		hw,lcdkit-acm-ce-support = <0x00>;
		hw,lcdkit-acm-valid-num = <0x07>;
		hw,lcdkit-r_hh0 = <0x7f>;
		hw,lcdkit-r_lh0 = <0x00>;
		hw,lcdkit-r_hh1 = <0xff>;
		hw,lcdkit-r_lh1 = <0x80>;
		hw,lcdkit-r_hh2 = <0x17f>;
		hw,lcdkit-r_lh2 = <0x100>;
		hw,lcdkit-r_hh3 = <0x1ff>;
		hw,lcdkit-r_lh3 = <0x180>;
		hw,lcdkit-r_hh4 = <0x27f>;
		hw,lcdkit-r_lh4 = <0x200>;
		hw,lcdkit-r_hh5 = <0x2ff>;
		hw,lcdkit-r_lh5 = <0x280>;
		hw,lcdkit-r_hh6 = <0x37f>;
		hw,lcdkit-r_lh6 = <0x300>;
		hw,lcdkit-r_video_hh0 = <0x7f>;
		hw,lcdkit-r_video_lh0 = <0x00>;
		hw,lcdkit-r_video_hh1 = <0x101>;
		hw,lcdkit-r_video_lh1 = <0x80>;
		hw,lcdkit-r_video_hh2 = <0x177>;
		hw,lcdkit-r_video_lh2 = <0x102>;
		hw,lcdkit-r_video_hh3 = <0x1ed>;
		hw,lcdkit-r_video_lh3 = <0x178>;
		hw,lcdkit-r_video_hh4 = <0x26f>;
		hw,lcdkit-r_video_lh4 = <0x1ee>;
		hw,lcdkit-r_video_hh5 = <0x2ff>;
		hw,lcdkit-r_video_lh5 = <0x270>;
		hw,lcdkit-r_video_hh6 = <0x37c>;
		hw,lcdkit-r_video_lh6 = <0x300>;
		hw,lcdkit-color-temp-rectify-r = <0x8000>;
		hw,lcdkit-color-temp-rectify-g = <0x8000>;
		hw,lcdkit-color-temp-rectify-b = <0x8000>;
		hw,lcdkit-hiace-support = <0x01>;
		hw,lcdkit-panel-effect-support = <0x00>;
		hw,lcdkit-arsr1p-sharpness-support = <0x01>;
		hw,lcdkit-iglobal-hist-black-pos = <0x10>;
		hw,lcdkit-iglobal-hist-white-pos = <0xf0>;
		hw,lcdkit-iglobal-hist-black-weight = <0x33>;
		hw,lcdkit-iglobal-hist-white-weight = <0x33>;
		hw,lcdkit-iglobal-hist-zero-cut-ratio = <0x1e6>;
		hw,lcdkit-iglobal-hist-slope-cut-ratio = <0x19a>;
		hw,lcdkit-imax-lcd-luminance = <0x1f4>;
		hw,lcdkit-imin-lcd-luminance = <0x03>;
		hw,lcdkit-cfg-name = "/product/etc/display/effect/algorithm/hdr_engine.xml";
		hw,lcdkit-effect-support-mode = <0x10001>;
		hw,lcdkit-bl-support-mode = <0x00>;
		hw,lcdkit-bl-enhance = <0x00>;
		hw,lcdkit-bl-normal = <0x00>;
		hw,lcdkit-delay-af-rst-off = <0x0a>;
		hw,lcdkit-h-back-porch = <0x12>;
		hw,lcdkit-h-front-porch = <0x12>;
		hw,lcdkit-h-pulse-width = <0x04>;
		hw,lcdkit-v-back-porch = <0x1c>;
		hw,lcdkit-v-pulse-width = <0x3e>;
		hw,lcdkit-v-front-porch = <0x1c>;
		hw,lcdkit-h-sync-skew = <0x00>;
		hw,lcdkit-lcd-type = <0x03>;
		hw,lcdkit-panel-pt-test-support = <0x01>;
		hw,lcdkit-mipi-clk-config-support = <0x00>;
		hw,lcdkit-panel-hkadc-support = <0x00>;
		hw,lcdkit-bias-power-ctrl-mode = <0x10>;
		hw,lcdkit-iovcc-power-ctrl-mode = <0x01>;
		hw,lcdkit-vci-power-ctrl-mode = <0x01>;
		hw,lcdkit-id0-gpio = <0x83>;
		hw,lcdkit-id1-gpio = <0x00>;
		hw,lcdkit-reset-gpio = <0x1d>;
		hw,lcdkit-te-gpio = <0x10>;
		hw,lcdkit-vsp-gpio = <0x00>;
		hw,lcdkit-vsn-gpio = <0x00>;
		hw,lcdkit-iovcc-gpio = <0x00>;
		hw,lcdkit-vci-gpio = <0x00>;
		hw,lcdkit-bl-gpio = <0x00>;
		hw,lcdkit-err-flag-gpio = <0x0c>;
		hw,lcdkit-iovcc-on-is-need-reset = <0x00>;
		hw,lcdkit-vsn-on-is-need-reset = <0x01>;
		hw,lcdkit-reset-pull-high-flag = <0x00>;
		hw,lcdkit-lcdanalog-vcc = <0x2dc6c0>;
		hw,lcdkit-lcdio-vcc = <0x1c3a90>;
		hw,lcdkit-lcd-bias = <0x00>;
		hw,lcdkit-lcd-vsp = <0x00>;
		hw,lcdkit-lcd-vsn = <0x00>;
		hw,lcdkit-lcd-rst-first-high = <0x01>;
		hw,lcdkit-lcd-rst-low = <0x01>;
		hw,lcdkit-lcd-rst-second-high = <0x0a>;
		hw,lcdkit-delay-af-vci-on = <0x0a>;
		hw,lcdkit-delay-af-iovcc-on = <0x00>;
		hw,lcdkit-delay-af-bias-on = <0x00>;
		hw,lcdkit-delay-af-vsp-on = <0x00>;
		hw,lcdkit-delay-af-vsn-on = <0x00>;
		hw,lcdkit-delay-af-lp11 = <0x01>;
		hw,lcdkit-delay-af-tp-reset = <0x00>;
		hw,lcdkit-tp-reset-before-lcd-reset = <0x00>;
		hw,lcdkit-delay-af-vsn-off = <0x00>;
		hw,lcdkit-delay-af-vsp-off = <0x00>;
		hw,lcdkit-delay-af-bias-off = <0x00>;
		hw,lcdkit-delay-af-vbat-off = <0x00>;
		hw,lcdkit-delay-af-iovcc-off = <0x00>;
		hw,lcdkit-delay-af-vci-off = <0x05>;
	};

	fastboot_recovery {
		compatible = "fastboot,recovery";
		is_mada_product = <0x01>;
		is_datapre_product = <0x01>;
		status = "ok";
	};

	hisi_vibrator@fff34000 {
		status = "disabled";
	};

	dp_source_switch {
		compatible = "huawei,dp_source_switch";
		dp_default_source_mode = <0x01>;
		status = "ok";
	};

	sio@E804F000 {
		status = "ok";
	};

	sio@E804F400 {
		status = "ok";
	};

	usb_analog_hs_interface {
		compatible = "huawei,usb_analog_hs_interface";
		status = "ok";
	};

	usb_ana_hs_fsa4476 {
		compatible = "huawei,usb_ana_hs_fsa4476";
		gpio_type = <0x00>;
		swtich_enn = <0x32 0x07 0x00>;
		mic_switch_delay = <0x96>;
		pd_unlock_enable = <0x01>;
		using_superswitch = <0x01>;
		switch_antenna = <0x01>;
		sd_gpio_used = <0x01>;
		status = "ok";
	};

	usb_audio_power {
		compatible = "huawei,usb_audio_power";
		gpio_type = <0x00>;
		gpio_chg_vbst_ctrl = <0x35 0x05 0x00>;
		gpio_ear_power_en = <0x2e 0x04 0x00>;
		using_superswitch = <0x01>;
		using_wireless_charger = <0x01>;
		status = "ok";
	};

	anc_hs_default@0 {
		status = "ok";
	};

	aod {
		compatible = "huawei,aod";
		status = "ok";
	};

	huawei,imx486hybird {
		compatible = "huawei,imx486hybird_ab";
		status = "disable";
	};

	huawei,imx319 {
		compatible = "huawei,imx319_ab";
		status = "ok";
	};

	huawei,ov13a40 {
		compatible = "huawei,ov13a40";
		status = "ok";
	};

	huawei,imx386hybird {
		compatible = "huawei,imx386hybird_ab";
		status = "disable";
	};

	huawei,imx318hybird {
		compatible = "huawei,imx318hybird";
		status = "ok";
	};

	huawei,imx600hybrid {
		compatible = "huawei,imx600hybrid";
		status = "ok";
	};

	huawei,imx576 {
		compatible = "huawei,imx576";
		status = "ok";
	};

	huawei,camera_ldo {
	};

	bcm_wifi {
		compatible = "hisilicon,bcm_wifi";
		status = "ok";
	};

	bcm_bt {
		compatible = "hisilicon,bcm_bt";
		status = "ok";
	};

	touchscreen {
	};

	huawei_dual_charger {
	};

	ts_kit {
		touchscreen@49 {
		};
	};

	__symbols__ {
		gpio059_pmx_func = "/pinmux@e896c000/gpio059_pmx_func";
		gpio059_pmx_idle = "/pinmux@e896c000/gpio059_pmx_idle";
		gpio060_pmx_func = "/pinmux@e896c000/gpio060_pmx_func";
		gpio060_pmx_idle = "/pinmux@e896c000/gpio060_pmx_idle";
		gpio061_pmx_func = "/pinmux@e896c000/gpio061_pmx_func";
		gpio061_pmx_idle = "/pinmux@e896c000/gpio061_pmx_idle";
		gpio182_pmx_func = "/pinmux@fff11000/gpio182_pmx_func";
		gpio182_pmx_idle = "/pinmux@fff11000/gpio182_pmx_idle";
		gpio200_pmx_func = "/pinmux@fff11000/gpio200_pmx_func";
		gpio200_pmx_idle = "/pinmux@fff11000/gpio200_pmx_idle";
		gpio206_pmx_func = "/pinmux@fff11000/gpio206_pmx_func";
		gpio206_pmx_idle = "/pinmux@fff11000/gpio206_pmx_idle";
		gpio216_pmx_func = "/pinmux@fff11000/gpio216_pmx_func";
		gpio216_pmx_idle = "/pinmux@fff11000/gpio216_pmx_idle";
		gpio059_cfg_func = "/pinmux@e896c800/gpio059_cfg_func";
		gpio059_cfg_idle = "/pinmux@e896c800/gpio059_cfg_idle";
		gpio060_cfg_func = "/pinmux@e896c800/gpio060_cfg_func";
		gpio060_cfg_idle = "/pinmux@e896c800/gpio060_cfg_idle";
		gpio061_cfg_func = "/pinmux@e896c800/gpio061_cfg_func";
		gpio061_cfg_idle = "/pinmux@e896c800/gpio061_cfg_idle";
		gpio182_cfg_func = "/pinmux@fff11800/gpio182_cfg_func";
		gpio182_cfg_idle = "/pinmux@fff11800/gpio182_cfg_idle";
		gpio200_cfg_func = "/pinmux@fff11800/gpio200_cfg_func";
		gpio200_cfg_idle = "/pinmux@fff11800/gpio200_cfg_idle";
		gpio206_cfg_func = "/pinmux@fff11800/gpio206_cfg_func";
		gpio206_cfg_idle = "/pinmux@fff11800/gpio206_cfg_idle";
		gpio216_cfg_func = "/pinmux@fff11800/gpio216_cfg_func";
		gpio216_cfg_idle = "/pinmux@fff11800/gpio216_cfg_idle";
		huawei_vl53l0 = "/amba/i2c@FDF0C000/huawei,vl53l0@29";
		huawei_lm3646 = "/amba/i2c@FDF0D000/huawei,lm3646@67";
		huawei_mp3336 = "/amba/i2c@FDF0D000/huawei,mp3336@27";
		max98925_smartpa_r = "/amba/i2c@FDF0D000/smartpa@34";
		tfa9872_smartpa_l = "/amba/i2c@FDF0D000/smartpa@35";
		tfa9872_smartpa_r = "/amba/i2c@FDF0D000/smartpa@36";
		pn547_nfc = "/amba/i2c@FDF0D000/nfc@28";
		huawei_mp3331 = "/amba/i2c@FDF0D000/huawei,mp3331@67";
		huawei_lm3642 = "/amba/i2c@FDF0D000/huawei,lm3642@63";
		tps65132_phy = "/amba/i2c@FDF0D000/tps65132@3e";
		lv52134a_phy = "/amba/i2c@FDF0D000/lv52134a@42";
		rt4801h_phy = "/amba/i2c@FDF0D000/rt4801h@73";
		huawei_thp = "/amba/spi@fff2a000/huawei_thp@10";
		spi_dev30 = "/amba/spi@fff2a000/spi_dev30@30";
		spi_dev31 = "/amba/spi@fff2a000/spi_dev31@31";
		spi_dev32 = "/amba/spi@fff2a000/spi_dev32@32";
		spi_dev33 = "/amba/spi@fff2a000/spi_dev33@33";
		modem_pinctrl = "/modem_pinctrl";
		dwmmc0 = "/dwmmc0@FC183000";
		mmccard = "/dwmmc0@FC183000/mmccard@0";
		airpress_sensor = "/sensorhub/airpress";
		fingerprint_ud_sensor = "/sensorhub/fingerprint_ud";
		gps_i2c_sensor = "/sensorhub/gps_4774_i2c";
		sar_sensor = "/sensorhub/sar";
		pcie_kport = "/pcie_kport";
		pcie_kport_rc = "/pcie_kport_rc@0xf4000000";
		pcie_kport_ep = "/pcie_kport_ep@0xf4000000";
		huawei_ptst = "/huawei_ptst";
		chg_watchdog = "/chg_watchdog";
		desayatl_3900_39k_4384 = "/desayatl_3900_39k_4384";
		scudlg_3900_200k_4384_25 = "/scudlg_3900_200k_4384_25";
		sunwodasony_3900_110k_4384_15 = "/sunwodasony_3900_110k_4384_15";
		extern_dac_vir_dai = "/extern_dac_vir_dai@0";
		maxim_ioctl = "/maxim_ioctl";
		hw_connectivity = "/hw_connectivity";
		dsi_neo_tugl_auo_otm1901a_5p2_1080p_video_default = "/lcdkit_neo_tugl_auo_otm1901a_5p2_1080p_video_default";
		dsi_neo_tugl_boe_sw43404_5p99 = "/lcdkit_neo_tugl_boe_sw43404_5p99";
		dsi_neo_tugl_lg_ea9151_5p99 = "/lcdkit_neo_tugl_lg_ea9151_5p99";
		fastboot_recovery = "/fastboot_recovery";
		usb_analog_hs_interface = "/usb_analog_hs_interface";
		usb_ana_hs_fsa4476 = "/usb_ana_hs_fsa4476";
		usb_audio_power = "/usb_audio_power";
		huawei_aod = "/aod";
		huawei_imx486hybird = "/huawei,imx486hybird";
		huawei_imx319 = "/huawei,imx319";
		huawei_ov13a40 = "/huawei,ov13a40";
		huawei_imx386hybird = "/huawei,imx386hybird";
		huawei_imx318hybird = "/huawei,imx318hybird";
		huawei_imx600hybrid = "/huawei,imx600hybrid";
		huawei_imx576 = "/huawei,imx576";
		huawei_camera_ldo = "/huawei,camera_ldo";
		bcm_wifi = "/bcm_wifi";
		bcm_bt = "/bcm_bt";
		touchscreen = "/touchscreen";
		huawei_dual_charger = "/huawei_dual_charger";
		ts_kit = "/ts_kit";
		st = "/ts_kit/touchscreen@49";
	};
};
